VERSION ""

NS_ :

BS_:

BU_: R_STR IAVAS ADAS ADAS_GW ENM THM CHR BAT BEV BEV_GW LCT STA ABG EPS IPMS BST VDC C_ECU C_ECU_GW

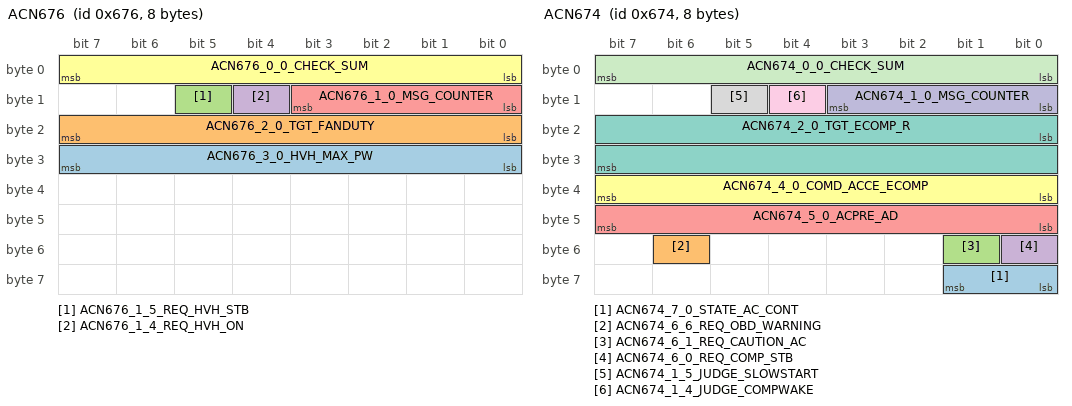
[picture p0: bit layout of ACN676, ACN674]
BO_ 1654 ACN676: 8 C_ECU_GW
 SG_ ACN676_3_0_HVH_MAX_PW : 24|8@1+ (40,0) [0|10200] "W"  THM
 SG_ ACN676_2_0_TGT_FANDUTY : 16|8@1+ (0.4,0) [0|100] "％"  THM
 SG_ ACN676_1_5_REQ_HVH_STB : 13|1@1+ (1,0) [0|1] ""  THM
 SG_ ACN676_1_4_REQ_HVH_ON : 12|1@1+ (1,0) [0|1] ""  THM
 SG_ ACN676_1_0_MSG_COUNTER : 8|4@1+ (1,0) [0|15] ""  THM
 SG_ ACN676_0_0_CHECK_SUM : 0|8@1+ (1,0) [0|255] ""  THM

BO_ 1652 ACN674: 8 C_ECU_GW
 SG_ ACN674_7_0_STATE_AC_CONT : 56|2@1+ (1,0) [0|3] ""  THM
 SG_ ACN674_6_6_REQ_OBD_WARNING : 54|1@1+ (1,0) [0|1] ""  THM
 SG_ ACN674_6_1_REQ_CAUTION_AC : 49|1@1+ (1,0) [0|1] ""  THM
 SG_ ACN674_6_0_REQ_COMP_STB : 48|1@1+ (1,0) [0|1] ""  THM
 SG_ ACN674_5_0_ACPRE_AD : 40|8@1+ (0.01953,0) [0|4.9815] "V"  THM
 SG_ ACN674_4_0_COMD_ACCE_ECOMP : 32|8@1+ (20,0) [0|5100] "rpm/s"  THM
 SG_ ACN674_2_0_TGT_ECOMP_R : 16|16@1+ (1,0) [0|65535] "rpm"  THM
 SG_ ACN674_1_5_JUDGE_SLOWSTART : 13|1@1+ (1,0) [0|1] ""  THM
 SG_ ACN674_1_4_JUDGE_COMPWAKE : 12|1@1+ (1,0) [0|1] ""  THM
 SG_ ACN674_1_0_MSG_COUNTER : 8|4@1+ (1,0) [0|15] ""  THM
 SG_ ACN674_0_0_CHECK_SUM : 0|8@1+ (1,0) [0|255] ""  THM

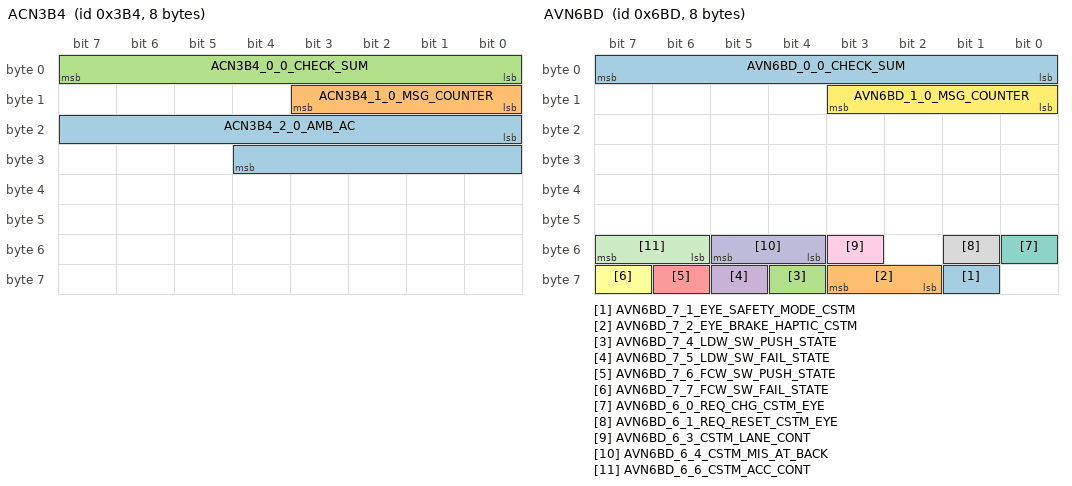
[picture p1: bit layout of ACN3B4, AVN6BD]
BO_ 948 ACN3B4: 8 C_ECU_GW
 SG_ ACN3B4_2_0_AMB_AC : 16|13@1+ (0.1,-400) [-400|419.1] "℃"  THM
 SG_ ACN3B4_1_0_MSG_COUNTER : 8|4@1+ (1,0) [0|15] ""  THM
 SG_ ACN3B4_0_0_CHECK_SUM : 0|8@1+ (1,0) [0|255] ""  THM

BO_ 1725 AVN6BD: 8 C_ECU_GW
 SG_ AVN6BD_7_1_EYE_SAFETY_MODE_CSTM : 57|1@0+ (1,0) [0|1] ""  ADAS
 SG_ AVN6BD_7_2_EYE_BRAKE_HAPTIC_CSTM : 59|2@0+ (1,0) [0|3] ""  ADAS
 SG_ AVN6BD_7_4_LDW_SW_PUSH_STATE : 60|1@0+ (1,0) [0|1] ""  ADAS
 SG_ AVN6BD_7_5_LDW_SW_FAIL_STATE : 61|1@0+ (1,0) [0|1] ""  ADAS
 SG_ AVN6BD_7_6_FCW_SW_PUSH_STATE : 62|1@0+ (1,0) [0|1] ""  ADAS
 SG_ AVN6BD_7_7_FCW_SW_FAIL_STATE : 63|1@0+ (1,0) [0|1] ""  ADAS
 SG_ AVN6BD_6_0_REQ_CHG_CSTM_EYE : 48|1@0+ (1,0) [0|1] ""  ADAS
 SG_ AVN6BD_6_1_REQ_RESET_CSTM_EYE : 49|1@0+ (1,0) [0|1] ""  ADAS
 SG_ AVN6BD_6_3_CSTM_LANE_CONT : 51|1@0+ (1,0) [0|1] ""  ADAS
 SG_ AVN6BD_6_4_CSTM_MIS_AT_BACK : 53|2@0+ (1,0) [0|3] ""  ADAS
 SG_ AVN6BD_6_6_CSTM_ACC_CONT : 55|2@0+ (1,0) [0|3] ""  ADAS
 SG_ AVN6BD_1_0_MSG_COUNTER : 11|4@0+ (1,0) [0|15] ""  ADAS
 SG_ AVN6BD_0_0_CHECK_SUM : 7|8@0+ (1,0) [0|255] ""  ADAS

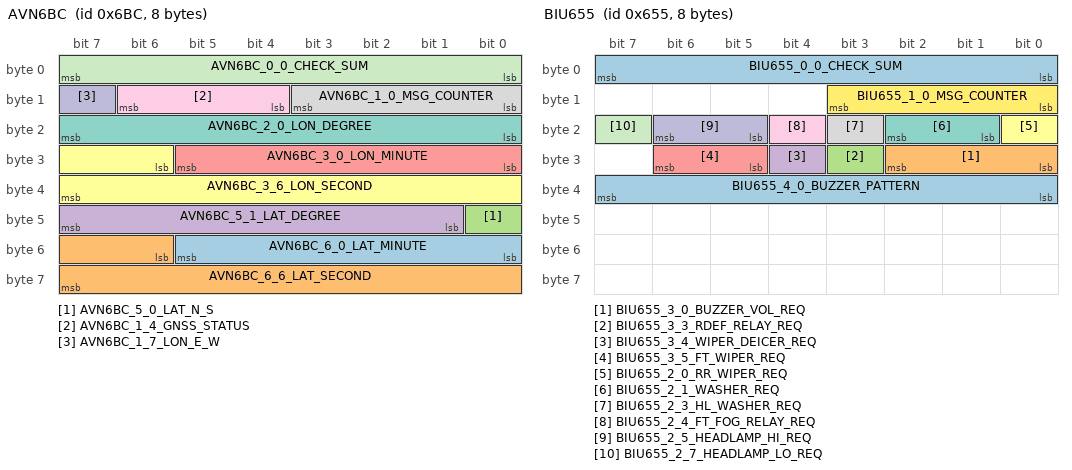
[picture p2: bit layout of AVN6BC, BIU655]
BO_ 1724 AVN6BC: 8 C_ECU_GW
 SG_ AVN6BC_6_0_LAT_MINUTE : 48|6@1+ (1,0) [0|59] ""  ADAS,CHR
 SG_ AVN6BC_6_6_LAT_SECOND : 54|10@1+ (0.1,0) [0|59.9] ""  ADAS,CHR
 SG_ AVN6BC_5_0_LAT_N_S : 40|1@1+ (1,0) [0|1] ""  ADAS,CHR
 SG_ AVN6BC_5_1_LAT_DEGREE : 41|7@1+ (1,0) [0|90] ""  ADAS,CHR
 SG_ AVN6BC_3_0_LON_MINUTE : 24|6@1+ (1,0) [0|59] ""  ADAS,CHR
 SG_ AVN6BC_3_6_LON_SECOND : 30|10@1+ (0.1,0) [0|59.9] ""  ADAS,CHR
 SG_ AVN6BC_2_0_LON_DEGREE : 16|8@1+ (1,0) [0|180] ""  ADAS,CHR
 SG_ AVN6BC_1_0_MSG_COUNTER : 8|4@1+ (1,0) [0|15] ""  ADAS,CHR
 SG_ AVN6BC_1_4_GNSS_STATUS : 12|3@1+ (1,0) [0|7] ""  ADAS,CHR
 SG_ AVN6BC_1_7_LON_E_W : 15|1@1+ (1,0) [0|1] ""  ADAS,CHR
 SG_ AVN6BC_0_0_CHECK_SUM : 0|8@1+ (1,0) [0|255] ""  ADAS,CHR

BO_ 1723 AVN6BB: 8 C_ECU_GW
 SG_ AVN6BB_7_0_ISA_IACC_OFFSET_CSTM : 56|5@1+ (1,0) [0|20] ""  ADAS
 SG_ AVN6BB_7_5_EYE_TOLLBOOTH_DECEL : 61|1@1+ (1,0) [0|1] ""  ADAS
 SG_ AVN6BB_7_6_EYE_CURVE_DECEL_CSTM : 62|1@1+ (1,0) [0|1] ""  ADAS
 SG_ AVN6BB_7_7_EYE_GREEN_LIGHT_CSTM : 63|1@1+ (1,0) [0|1] ""  ADAS
 SG_ AVN6BB_6_0_CCU_FAIL : 48|1@1+ (1,0) [0|1] ""  ADAS,VDC
 SG_ AVN6BB_6_1_EYE_P_CR_CSTM : 49|1@1+ (1,0) [0|1] ""  ADAS
 SG_ AVN6BB_6_2_EYE_ALK_B_LDW_CSTM : 50|2@1+ (1,0) [0|3] ""  ADAS
 SG_ AVN6BB_6_4_EYE_CSTM_REQ : 52|1@1+ (1,0) [0|1] ""  ADAS
 SG_ AVN6BB_6_5_EYE_ELK_CSTM : 53|1@1+ (1,0) [0|1] ""  ADAS
 SG_ AVN6BB_6_6_EYE_ALKB_EDGE_CSTM : 54|1@1+ (1,0) [0|1] "" Vector__XXX
 SG_ AVN6BB_6_7_FCW_ON_OFF : 55|1@1+ (1,0) [0|1] ""  ADAS
 SG_ AVN6BB_5_0_DMS_SELECT_ID : 40|4@1+ (1,0) [0|5] ""  IPMS
 SG_ AVN6BB_5_4_TPMS_TH_MODE_CSTM : 44|2@1+ (1,0) [0|3] ""  ADAS
 SG_ AVN6BB_5_6_DMS_SET_REQ : 46|1@1+ (1,0) [0|1] ""  IPMS
 SG_ AVN6BB_5_7_DMS_RECOG_SET : 47|1@1+ (1,0) [0|1] ""  IPMS
 SG_ AVN6BB_4_0_DMS_EDIT_REQ : 32|4@1+ (1,0) [0|15] ""  IPMS
 SG_ AVN6BB_4_4_VEHICLE_DEMO : 36|1@1+ (1,0) [0|1] ""  IPMS
 SG_ AVN6BB_4_5_SRVD_CSTM_REQ : 37|1@1+ (1,0) [0|1] "" Vector__XXX
 SG_ AVN6BB_4_6_SEAT_RESET_REQ : 38|1@1+ (1,0) [0|1] "" Vector__XXX
 SG_ AVN6BB_4_7_SEATAWAY_SET_CSTM : 39|1@1+ (1,0) [0|1] "" Vector__XXX
 SG_ AVN6BB_3_0_SRVD_ON_OFF : 24|1@1+ (1,0) [0|1] "" Vector__XXX
 SG_ AVN6BB_3_1_PRG_RESET_REQ : 25|1@1+ (1,0) [0|1] "" Vector__XXX
 SG_ AVN6BB_3_2_PRG_MEM_CSTM : 26|1@1+ (1,0) [0|1] "" Vector__XXX
 SG_ AVN6BB_3_3_DMS_ON_OFF : 27|1@1+ (1,0) [0|1] ""  IPMS
 SG_ AVN6BB_3_4_MIR_RESET_REQ : 28|1@1+ (1,0) [0|1] "" Vector__XXX
 SG_ AVN6BB_3_5_MIR_AFOLD_CSTM : 29|1@1+ (1,0) [0|1] "" Vector__XXX
 SG_ AVN6BB_3_6_MIR_RTILT_CSTM : 30|1@1+ (1,0) [0|1] "" Vector__XXX
 SG_ AVN6BB_3_7_EYE_TSA_CSTM : 31|1@1+ (1,0) [0|1] ""  ADAS
 SG_ AVN6BB_2_0_AVH_ON_OFF : 16|2@1+ (1,0) [0|3] ""  VDC
 SG_ AVN6BB_2_2_VDC_ON_OFF : 18|2@1+ (1,0) [0|3] ""  VDC
 SG_ AVN6BB_2_4_CCU_HALT_RESET : 20|1@1+ (1,0) [0|1] ""  ADAS,VDC
 SG_ AVN6BB_2_5_EYE_LDW_TIMING_CSTM : 21|1@1+ (1,0) [0|1] ""  ADAS
 SG_ AVN6BB_2_6_FCW_CSTM : 22|2@1+ (1,0) [0|3] ""  ADAS
 SG_ AVN6BB_1_0_MSG_COUNTER : 8|4@1+ (1,0) [0|15] ""  ADAS,IPMS,VDC
 SG_ AVN6BB_1_4_EYE_WARN_CSTM : 12|1@1+ (1,0) [0|1] ""  ADAS
 SG_ AVN6BB_1_5_EYE_FCTI_CSTM : 13|2@1+ (1,0) [0|3] "" Vector__XXX
 SG_ AVN6BB_1_7_LDW_WARNING_ON_OFF : 15|1@1+ (1,0) [0|1] ""  ADAS
 SG_ AVN6BB_0_0_CHECK_SUM : 0|8@1+ (1,0) [0|255] ""  ADAS,IPMS,VDC

BO_ 1713 AVN6B1: 8 C_ECU_GW
 SG_ AVN6B1_7_1_PRESENT_YEAR : 57|7@1+ (1,0) [0|126] "Year"  ADAS
 SG_ AVN6B1_6_0_PRESENT_DAY : 48|5@1+ (1,0) [1|31] "Day"  ADAS
 SG_ AVN6B1_6_5_PRESENT_MONTH : 53|4@1+ (1,0) [1|12] "Month"  ADAS
 SG_ AVN6B1_5_0_FAIL_AVN : 40|1@1+ (1,0) [0|1] "" Vector__XXX
 SG_ AVN6B1_5_1_IN_OPERATION : 41|1@1+ (1,0) [0|1] "" Vector__XXX
 SG_ AVN6B1_5_2_TYPE_NAVI : 42|2@1+ (1,0) [0|3] "" Vector__XXX
 SG_ AVN6B1_5_4_XM_ENABLE : 44|2@1+ (1,0) [0|3] "" Vector__XXX
 SG_ AVN6B1_5_6_FLG_ABLE_WELCOME_SCL : 46|1@1+ (1,0) [0|1] "" Vector__XXX
 SG_ AVN6B1_5_7_STEER_ANGLE_INTERLOCK : 47|1@1+ (1,0) [0|1] "" Vector__XXX
 SG_ AVN6B1_4_0_PRESENT_TIME_SEC : 32|6@1+ (1,0) [0|59] "s"  ADAS
 SG_ AVN6B1_4_7_BACK_CAMERA_DELAY : 39|1@1+ (1,0) [0|1] "" Vector__XXX
 SG_ AVN6B1_3_0_PRESENT_TIME_MIN : 24|6@1+ (1,0) [0|59] "m"  ADAS
 SG_ AVN6B1_3_7_MVS_FTSNR_INTERRUPT : 31|1@1+ (1,0) [0|1] "" Vector__XXX
 SG_ AVN6B1_2_0_GPS_CLOCK_FLG : 16|1@1+ (1,0) [0|1] ""  ADAS
 SG_ AVN6B1_2_1_PRESENT_TIME_HOUR : 17|5@1+ (1,0) [0|23] "h"  ADAS
 SG_ AVN6B1_2_6_TIME_FORMAT : 22|2@1+ (1,0) [0|3] "" Vector__XXX
 SG_ AVN6B1_1_0_MSG_COUNTER : 8|4@1+ (1,0) [0|15] ""  ADAS
 SG_ AVN6B1_1_4_WAKE_UP_FRAME : 12|1@1+ (1,0) [0|1] "" Vector__XXX
 SG_ AVN6B1_1_5_REQ_COMM_CONT : 13|1@1+ (1,0) [0|1] "" Vector__XXX
 SG_ AVN6B1_1_6_ACTIVE_AVN_CSTM : 14|1@1+ (1,0) [0|1] "" Vector__XXX
 SG_ AVN6B1_1_7_REQ_STOP_CAMERA_OUT : 15|1@1+ (1,0) [0|1] ""  ADAS
 SG_ AVN6B1_0_0_CHECK_SUM : 0|8@1+ (1,0) [0|255] ""  ADAS

BO_ 1019 AVN3FB: 8 C_ECU_GW
 SG_ AVN3FB_7_0_SMT_TIM_RESET_REQ : 56|1@1+ (1,0) [0|1] "" Vector__XXX
 SG_ AVN3FB_7_1_SMT_EG_CSTM_REQ : 57|1@1+ (1,0) [0|1] "" Vector__XXX
 SG_ AVN3FB_7_2_EYE_YEILD_CSTM : 58|1@1+ (1,0) [0|1] ""  ADAS
 SG_ AVN3FB_7_3_EYE_STOP_CSTM : 59|1@1+ (1,0) [0|1] ""  ADAS
 SG_ AVN3FB_7_4_EYE_NO_ENTRY_CSTM : 60|1@1+ (1,0) [0|1] ""  ADAS
 SG_ AVN3FB_7_5_MVS_CAMERA_SELECT_SW : 61|1@1+ (1,0) [0|1] "" Vector__XXX
 SG_ AVN3FB_7_7_ACPANEL_DR_ONLY : 63|1@1+ (1,0) [0|1] "" Vector__XXX
 SG_ AVN3FB_6_0_ACPANEL_PA_TEMP : 48|6@1+ (0.5,13) [1|44] "℃/?" Vector__XXX
 SG_ AVN3FB_6_6_ACPANEL_MODE_DOWN : 54|1@1+ (1,0) [0|1] "" Vector__XXX
 SG_ AVN3FB_6_7_ACPANEL_MODE_UP : 55|1@1+ (1,0) [0|1] "" Vector__XXX
 SG_ AVN3FB_5_0_ACPANEL_DR_TEMP : 40|6@1+ (0.5,13) [1|44] "℃/?" Vector__XXX
 SG_ AVN3FB_5_6_ACPANEL_FAN_DOWN : 46|1@1+ (1,0) [0|1] "" Vector__XXX
 SG_ AVN3FB_5_7_ACPANEL_FAN_UP : 47|1@1+ (1,0) [0|1] "" Vector__XXX
 SG_ AVN3FB_4_0_ACPANEL_FAN_LEVEL : 32|4@1+ (1,0) [0|15] "" Vector__XXX
 SG_ AVN3FB_4_4_ACPANEL_MODE_VENT : 36|4@1+ (1,0) [0|15] "" Vector__XXX
 SG_ AVN3FB_3_0_ACPANEL_PA_TEMP_DOWN : 24|1@1+ (1,0) [0|1] "" Vector__XXX
 SG_ AVN3FB_3_1_ACPANEL_PA_TEMP_UP : 25|1@1+ (1,0) [0|1] "" Vector__XXX
 SG_ AVN3FB_3_2_ACPANEL_DR_TEMP_DOWN : 26|1@1+ (1,0) [0|1] "" Vector__XXX
 SG_ AVN3FB_3_3_ACPANEL_DR_TEMP_UP : 27|1@1+ (1,0) [0|1] "" Vector__XXX
 SG_ AVN3FB_3_4_ACPANEL_SYNC : 28|1@1+ (1,0) [0|1] "" Vector__XXX
 SG_ AVN3FB_3_5_ACPANEL_AC : 29|1@1+ (1,0) [0|1] "" Vector__XXX
 SG_ AVN3FB_3_6_F_DEF_SW : 30|1@1+ (1,0) [0|1] "" Vector__XXX
 SG_ AVN3FB_3_7_R_DEF_SW : 31|1@1+ (1,0) [0|1] "" Vector__XXX
 SG_ AVN3FB_2_0_ACPANEL_AUTO : 16|1@1+ (1,0) [0|1] "" Vector__XXX
 SG_ AVN3FB_2_1_ACPANEL_MAX_AC : 17|1@1+ (1,0) [0|1] "" Vector__XXX
 SG_ AVN3FB_2_2_ACPANEL_SEAT_C_P : 18|1@1+ (1,0) [0|1] "" Vector__XXX
 SG_ AVN3FB_2_3_ACPANEL_SEAT_C_D : 19|1@1+ (1,0) [0|1] "" Vector__XXX
 SG_ AVN3FB_2_4_ACPANEL_SEAT_H_P : 20|1@1+ (1,0) [0|1] "" Vector__XXX
 SG_ AVN3FB_2_5_ACPANEL_SEAT_H_D : 21|1@1+ (1,0) [0|1] "" Vector__XXX
 SG_ AVN3FB_2_6_ACPANEL_INNER_AIR : 22|1@1+ (1,0) [0|1] "" Vector__XXX
 SG_ AVN3FB_2_7_ACPANEL_AC_ON_OFF : 23|1@1+ (1,0) [0|1] "" Vector__XXX
 SG_ AVN3FB_1_0_MSG_COUNTER : 8|4@1+ (1,0) [0|15] ""  ADAS
 SG_ AVN3FB_1_4_EYE_CSTM_REQ_3FB : 12|1@1+ (1,0) [0|1] ""  ADAS
 SG_ AVN3FB_1_5_DDAW_WARNING_CSTM : 13|1@1+ (1,0) [0|1] ""  ADAS
 SG_ AVN3FB_1_6_SIGN_SWITCH_SND : 14|1@1+ (1,0) [0|1] ""  ADAS
 SG_ AVN3FB_1_7_SLWF_CSTM : 15|1@1+ (1,0) [0|1] ""  ADAS
 SG_ AVN3FB_0_0_CHECK_SUM : 0|8@1+ (1,0) [0|255] ""  ADAS

BO_ 818 PMN332: 8 C_ECU_GW
 SG_ PMN332_7_0_RES_CONTROL_STATUS : 56|2@1+ (1,0) [0|3] "" Vector__XXX
 SG_ PMN332_7_2_REQ_RES_P_LOCK : 58|1@1+ (1,0) [0|1] "" Vector__XXX
 SG_ PMN332_7_5_IGB_RELAY_REQ : 61|1@1+ (1,0) [0|1] ""  BEV
 SG_ PMN332_7_6_IGA_RELAY_REQ : 62|1@1+ (1,0) [0|1] ""  BEV
 SG_ PMN332_7_7_REQ_STOP_RES : 63|1@1+ (1,0) [0|1] "" Vector__XXX
 SG_ PMN332_6_0_RES_IDLE_TIME : 48|7@1+ (10,0) [0|1270] "sec" Vector__XXX
 SG_ PMN332_6_7_CUST : 55|1@1+ (1,0) [0|1] "" Vector__XXX
 SG_ PMN332_5_0_PUSHSTART_SW : 40|1@1+ (1,0) [0|1] "" Vector__XXX
 SG_ PMN332_5_1_SIG_KEY_PUSHSTART : 41|1@1+ (1,0) [0|1] "" Vector__XXX
 SG_ PMN332_5_2_STATE_MODE_POWER : 42|2@1+ (1,0) [0|2] "" Vector__XXX
 SG_ PMN332_5_4_BUZ_2SHOT_IN : 44|1@1+ (1,0) [0|1] "" Vector__XXX
 SG_ PMN332_5_5_BUZ_INTERMIT1_IN : 45|1@1+ (1,0) [0|1] "" Vector__XXX
 SG_ PMN332_5_6_BUZ_INTERMIT2_IN : 46|1@1+ (1,0) [0|1] "" Vector__XXX
 SG_ PMN332_5_7_BUZ_CONTINUE_IN : 47|1@1+ (1,0) [0|1] "" Vector__XXX
 SG_ PMN332_2_0_WARN_SSP_SIG1 : 16|1@1+ (1,0) [0|1] "" Vector__XXX
 SG_ PMN332_2_1_WARN_SSP_SIG2 : 17|3@1+ (1,0) [0|4] "" Vector__XXX
 SG_ PMN332_2_4_SMT_PWR_SIG : 20|2@1+ (1,0) [0|2] "" Vector__XXX
 SG_ PMN332_2_7_BUZ_1SHOT_IN : 23|1@1+ (1,0) [0|1] "" Vector__XXX
 SG_ PMN332_1_0_MSG_COUNTER : 8|4@1+ (1,0) [0|15] ""  BEV
 SG_ PMN332_0_0_CHECK_SUM : 0|8@1+ (1,0) [0|255] ""  BEV

BO_ 1622 BIU656: 8 C_ECU_GW
 SG_ BIU656_6_0_KICK_OPEN_REQ_PRG : 48|1@1+ (1,0) [0|1] "" Vector__XXX
 SG_ BIU656_6_1_KICK_CLOSE_REQ_PRG : 49|1@1+ (1,0) [0|1] "" Vector__XXX
 SG_ BIU656_6_6_CARGO_LAMP_OUT : 54|1@1+ (1,0) [0|1] "" Vector__XXX
 SG_ BIU656_6_7_PERMITT_KEY_RG_UNL : 55|1@1+ (1,0) [0|1] "" Vector__XXX
 SG_ BIU656_5_0_PRG_DRVR_OPENERSW : 40|1@1+ (1,0) [0|1] "" Vector__XXX
 SG_ BIU656_5_1_HF_PRG_OFF_SW : 41|1@1+ (1,0) [0|1] "" Vector__XXX
 SG_ BIU656_5_2_PERMIT_OPEN_RG : 42|1@1+ (1,0) [0|1] "" Vector__XXX
 SG_ BIU656_5_3_BUZ_ON_OFF : 43|1@1+ (1,0) [0|1] "" Vector__XXX
 SG_ BIU656_5_4_PRG_DRVR_SW_PERMIT : 44|1@1+ (1,0) [0|1] "" Vector__XXX
 SG_ BIU656_5_5_CSTM_HF_PRG_LOCK : 45|1@1+ (1,0) [0|1] "" Vector__XXX
 SG_ BIU656_5_6_CSTM_KICK_SENSOR : 46|1@1+ (1,0) [0|1] "" Vector__XXX
 SG_ BIU656_5_7_KICK_REQ_PRG : 47|1@1+ (1,0) [0|1] "" Vector__XXX
 SG_ BIU656_4_0_NOT_SMT_KEY_RG_SW : 32|2@1+ (1,0) [0|3] "" Vector__XXX
 SG_ BIU656_4_2_SMT_KEY_RG_SW : 34|2@1+ (1,0) [0|3] "" Vector__XXX
 SG_ BIU656_4_4_OPEN_RG_OPENER_SW : 36|2@1+ (1,0) [0|3] "" Vector__XXX
 SG_ BIU656_3_4_CHECKED_KEYNO : 28|3@1+ (1,0) [0|7] "" Vector__XXX
 SG_ BIU656_3_7_LOCKSTATUS_DRVR : 31|1@1+ (1,0) [0|1] "" Vector__XXX
 SG_ BIU656_2_0_TRIG_LOCK_UNLOCK : 16|12@1+ (1,0) [0|4095] ""  IPMS
 SG_ BIU656_1_0_MSG_COUNTER : 8|4@1+ (1,0) [0|15] "" Vector__XXX
 SG_ BIU656_0_0_CHECK_SUM : 0|8@1+ (1,0) [0|255] "" Vector__XXX

BO_ 1621 BIU655: 8 C_ECU_GW
 SG_ BIU655_4_0_BUZZER_PATTERN : 32|8@1+ (1,0) [0|240] "" Vector__XXX
 SG_ BIU655_3_0_BUZZER_VOL_REQ : 24|3@1+ (1,0) [0|7] "" Vector__XXX
 SG_ BIU655_3_3_RDEF_RELAY_REQ : 27|1@1+ (1,0) [0|1] "" Vector__XXX
 SG_ BIU655_3_4_WIPER_DEICER_REQ : 28|1@1+ (1,0) [0|1] "" Vector__XXX
 SG_ BIU655_3_5_FT_WIPER_REQ : 29|2@1+ (1,0) [0|3] "" Vector__XXX
 SG_ BIU655_2_0_RR_WIPER_REQ : 16|1@1+ (1,0) [0|1] "" Vector__XXX
 SG_ BIU655_2_1_WASHER_REQ : 17|2@1+ (1,0) [0|3] ""  ADAS
 SG_ BIU655_2_3_HL_WASHER_REQ : 19|1@1+ (1,0) [0|1] "" Vector__XXX
 SG_ BIU655_2_4_FT_FOG_RELAY_REQ : 20|1@1+ (1,0) [0|1] "" Vector__XXX
 SG_ BIU655_2_5_HEADLAMP_HI_REQ : 21|2@1+ (1,0) [0|3] "" Vector__XXX
 SG_ BIU655_2_7_HEADLAMP_LO_REQ : 23|1@1+ (1,0) [0|1] "" Vector__XXX
 SG_ BIU655_1_0_MSG_COUNTER : 8|4@1+ (1,0) [0|15] "" Vector__XXX
 SG_ BIU655_0_0_CHECK_SUM : 0|8@1+ (1,0) [0|255] "" Vector__XXX

BO_ 1618 BIU652: 8 C_ECU_GW
 SG_ BIU652_7_0_IND_SECURITY_IMB : 56|8@1+ (1,0) [0|240] "" Vector__XXX
 SG_ BIU652_6_0_OCCUPATION_3RDRH : 48|1@1+ (1,0) [0|1] "" Vector__XXX
 SG_ BIU652_6_1_OCCUPATION_3RDCTR : 49|1@1+ (1,0) [0|1] "" Vector__XXX
 SG_ BIU652_6_2_OCCUPATION_3RDLH : 50|1@1+ (1,0) [0|1] "" Vector__XXX
 SG_ BIU652_6_3_OCCUPATION_RRRH : 51|1@1+ (1,0) [0|1] ""  ABG
 SG_ BIU652_6_4_OCCUPATION_RRCTR : 52|1@1+ (1,0) [0|1] ""  ABG
 SG_ BIU652_6_5_OCCUPATION_RRLH : 53|1@1+ (1,0) [0|1] ""  ABG
 SG_ BIU652_6_6_HORNHAZARD_RES_SIG : 54|1@1+ (1,0) [0|1] "" Vector__XXX
 SG_ BIU652_6_7_OCCUPATION_DRVR : 55|1@1+ (1,0) [0|1] ""  ABG
 SG_ BIU652_5_0_STATUS_ROOMLAMP : 40|3@1+ (1,0) [0|7] "" Vector__XXX
 SG_ BIU652_5_3_HEADLAMP_SMALL : 43|1@1+ (1,0) [0|1] "" Vector__XXX
 SG_ BIU652_5_4_ALL_UNLOCK_STATE : 44|1@1+ (1,0) [0|1] "" Vector__XXX
 SG_ BIU652_5_5_DRVR_UNLOCK_STATE : 45|1@1+ (1,0) [0|1] "" Vector__XXX
 SG_ BIU652_5_6_ALL_LOCK_STATE : 46|1@1+ (1,0) [0|1] "" Vector__XXX
 SG_ BIU652_4_0_TRIG_LOCK_UNLOCK : 32|8@1+ (1,0) [0|255] ""  IPMS
 SG_ BIU652_3_0_DOOR_DRVR : 24|1@1+ (1,0) [0|1] "" Vector__XXX
 SG_ BIU652_3_1_DOOR_PASS : 25|1@1+ (1,0) [0|1] "" Vector__XXX
 SG_ BIU652_3_2_DOOR_RRRH : 26|1@1+ (1,0) [0|1] "" Vector__XXX
 SG_ BIU652_3_3_DOOR_RRLH : 27|1@1+ (1,0) [0|1] "" Vector__XXX
 SG_ BIU652_3_4_DOOR_RG : 28|1@1+ (1,0) [0|1] "" Vector__XXX
 SG_ BIU652_3_5_DOOR_TR : 29|1@1+ (1,0) [0|1] "" Vector__XXX
 SG_ BIU652_3_7_OPENSW_RG : 31|1@1+ (1,0) [0|1] "" Vector__XXX
 SG_ BIU652_2_0_LOCKSTATUS_DRVR : 16|1@1+ (1,0) [0|1] "" Vector__XXX
 SG_ BIU652_2_1_LOCKSTATUS_PASS : 17|1@1+ (1,0) [0|1] "" Vector__XXX
 SG_ BIU652_2_2_LOCKSTATUS_RRRH : 18|1@1+ (1,0) [0|1] "" Vector__XXX
 SG_ BIU652_2_3_LOCKSTATUS_RRLH : 19|1@1+ (1,0) [0|1] "" Vector__XXX
 SG_ BIU652_2_4_LOCKSTATUS_RG : 20|1@1+ (1,0) [0|1] "" Vector__XXX
 SG_ BIU652_2_6_UNLOCK_DOORKEYSW : 22|1@1+ (1,0) [0|1] "" Vector__XXX
 SG_ BIU652_2_7_LOCK_DOORKEYSW : 23|1@1+ (1,0) [0|1] "" Vector__XXX
 SG_ BIU652_1_0_MSG_COUNTER : 8|4@1+ (1,0) [0|15] ""  ABG,IPMS
 SG_ BIU652_0_0_CHECK_SUM : 0|8@1+ (1,0) [0|255] ""  ABG,IPMS

BO_ 1617 BIU651: 8 C_ECU_GW
 SG_ BIU651_7_0_PWPOS_RL : 56|2@1+ (1,0) [0|3] "" Vector__XXX
 SG_ BIU651_7_2_PWPOS_RR : 58|2@1+ (1,0) [0|3] "" Vector__XXX
 SG_ BIU651_7_4_PWPOS_PASS : 60|2@1+ (1,0) [0|3] "" Vector__XXX
 SG_ BIU651_7_6_PWPOS_DRVR : 62|2@1+ (1,0) [0|3] "" Vector__XXX
 SG_ BIU651_6_0_IND_ACTIVE_HBA : 48|2@1+ (1,0) [0|3] "" Vector__XXX
 SG_ BIU651_6_2_ADB_ACTIVE : 50|1@1+ (1,0) [0|1] ""  ADAS
 SG_ BIU651_6_3_JUDGE_ILL : 51|1@1+ (1,0) [0|1] "" Vector__XXX
 SG_ BIU651_6_4_TYPE_LO_BEAM : 52|2@1+ (1,0) [0|3] "" Vector__XXX
 SG_ BIU651_6_6_TYPE_HI_BEAM : 54|2@1+ (1,0) [0|3] "" Vector__XXX
 SG_ BIU651_5_0_SRF_ACTIVE : 40|1@1+ (1,0) [0|1] ""  ADAS
 SG_ BIU651_5_1_SRF_IND : 41|2@1+ (1,0) [0|3] ""  ADAS
 SG_ BIU651_5_3_SRF_LAMP_LIGHT : 43|1@1+ (1,0) [0|1] ""  ADAS
 SG_ BIU651_5_4_SRF_LAMP_LEFT : 44|1@1+ (1,0) [0|1] ""  ADAS
 SG_ BIU651_5_5_MSG_STATUS_HBA : 45|2@1+ (1,0) [0|3] "" Vector__XXX
 SG_ BIU651_5_7_IND_FAIL_HBA : 47|1@1+ (1,0) [0|1] "" Vector__XXX
 SG_ BIU651_4_0_BUZ_PATTERN : 32|4@1+ (1,0) [0|8] "" Vector__XXX
 SG_ BIU651_4_4_CSTM_OPE_ALARM : 36|2@1+ (1,0) [0|3] "" Vector__XXX
 SG_ BIU651_4_6_CSTM_HBA : 38|2@1+ (1,0) [0|3] ""  ADAS
 SG_ BIU651_3_0_HEADLAMP_PASS_SW : 24|1@1+ (1,0) [0|1] ""  ADAS
 SG_ BIU651_3_1_HEADLAMP_AUTO_SW : 25|1@1+ (1,0) [0|1] ""  ADAS
 SG_ BIU651_3_2_JUDGE_DOOR_LOCK : 26|1@1+ (1,0) [0|1] "" Vector__XXX
 SG_ BIU651_3_3_JUDGE_DOOR_UNLOCK : 27|1@1+ (1,0) [0|1] "" Vector__XXX
 SG_ BIU651_3_4_HEADLAMP_Lo_SW : 28|1@1+ (1,0) [0|1] "" Vector__XXX
 SG_ BIU651_3_5_HEADLAMP_HI_SW : 29|1@1+ (1,0) [0|1] ""  ADAS
 SG_ BIU651_3_6_WIPER_AUTO_SW : 30|1@1+ (1,0) [0|1] "" Vector__XXX
 SG_ BIU651_3_7_PRG_LIN_MEMORY_ON_OFF : 31|1@1+ (1,0) [0|1] "" Vector__XXX
 SG_ BIU651_2_0_CSTM_ILLUMI_SSR : 16|1@1+ (1,0) [0|1] "" Vector__XXX
 SG_ BIU651_2_1_HANDLE : 17|1@1+ (1,0) [0|1] ""  ADAS
 SG_ BIU651_2_2_CSTM_SMT : 18|1@1+ (1,0) [0|1] "" Vector__XXX
 SG_ BIU651_2_3_AJARDOOR_STATUS : 19|1@1+ (1,0) [0|1] "" Vector__XXX
 SG_ BIU651_2_4_ONETOUCH_LAMP_OUT : 20|1@1+ (1,0) [0|1] "" Vector__XXX
 SG_ BIU651_2_5_PRG_FAIL_FLAG : 21|1@1+ (1,0) [0|1] "" Vector__XXX
 SG_ BIU651_2_6_CSTM_PSMECU : 22|1@1+ (1,0) [0|1] "" Vector__XXX
 SG_ BIU651_2_7_STATE_REGIST_DEL : 23|1@1+ (1,0) [0|1] "" Vector__XXX
 SG_ BIU651_1_0_MSG_COUNTER : 8|4@1+ (1,0) [0|15] ""  ADAS
 SG_ BIU651_1_4_SRPOS : 12|3@1+ (1,0) [0|7] "" Vector__XXX
 SG_ BIU651_1_7_WIPER_INT_STATUS : 15|1@1+ (1,0) [0|1] "" Vector__XXX
 SG_ BIU651_0_0_CHECK_SUM : 0|8@1+ (1,0) [0|255] ""  ADAS

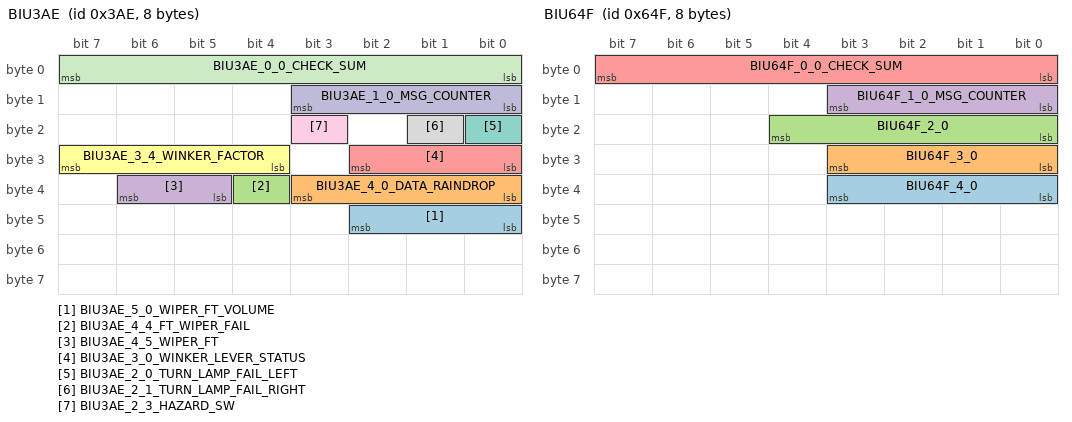
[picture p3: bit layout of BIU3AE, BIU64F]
BO_ 942 BIU3AE: 8 C_ECU_GW
 SG_ BIU3AE_5_0_WIPER_FT_VOLUME : 40|3@1+ (1,0) [0|5] "" Vector__XXX
 SG_ BIU3AE_4_0_DATA_RAINDROP : 32|4@1+ (1,0) [0|8] ""  ADAS
 SG_ BIU3AE_4_4_FT_WIPER_FAIL : 36|1@1+ (1,0) [0|1] "" Vector__XXX
 SG_ BIU3AE_4_5_WIPER_FT : 37|2@1+ (1,0) [0|3] ""  ADAS
 SG_ BIU3AE_3_0_WINKER_LEVER_STATUS : 24|3@1+ (1,0) [0|5] ""  ADAS
 SG_ BIU3AE_3_4_WINKER_FACTOR : 28|4@1+ (1,0) [0|15] ""  ADAS,ABG
 SG_ BIU3AE_2_0_TURN_LAMP_FAIL_LEFT : 16|1@1+ (1,0) [0|1] ""  ADAS
 SG_ BIU3AE_2_1_TURN_LAMP_FAIL_RIGHT : 17|1@1+ (1,0) [0|1] ""  ADAS
 SG_ BIU3AE_2_3_HAZARD_SW : 19|1@1+ (1,0) [0|1] ""  ADAS
 SG_ BIU3AE_1_0_MSG_COUNTER : 8|4@1+ (1,0) [0|15] ""  ADAS,ABG
 SG_ BIU3AE_0_0_CHECK_SUM : 0|8@1+ (1,0) [0|255] ""  ADAS,ABG

BO_ 940 BIU3AC: 8 C_ECU_GW
 SG_ BIU3AC_7_0_HEADLAMP_SMALL : 56|1@1+ (1,0) [0|1] ""  ADAS,ADAS_GW
 SG_ BIU3AC_7_1_HEADLAMP_LO_REQ : 57|1@1+ (1,0) [0|1] ""  ADAS,ADAS_GW
 SG_ BIU3AC_7_2_HEADLAMP_HI_REQ : 58|1@1+ (1,0) [0|1] ""  ADAS,ADAS_GW
 SG_ BIU3AC_7_3_FT_FOG_RELAY_REQ : 59|1@1+ (1,0) [0|1] ""  ADAS,ADAS_GW
 SG_ BIU3AC_7_4_FOGLAMP_RR : 60|1@1+ (1,0) [0|1] ""  ADAS_GW
 SG_ BIU3AC_7_5_DRL : 61|1@1+ (1,0) [0|1] ""  ADAS_GW
 SG_ BIU3AC_7_6_WIPER_FRONT : 62|1@1+ (1,0) [0|1] ""  ADAS,ADAS_GW
 SG_ BIU3AC_7_7_RDEF_RELAY_REQ : 63|1@1+ (1,0) [0|1] ""  ADAS_GW
 SG_ BIU3AC_6_0_RDEFOGSW : 48|1@1+ (1,0) [0|1] ""  ADAS_GW
 SG_ BIU3AC_6_1_CSTM_PRG : 49|1@1+ (1,0) [0|1] ""  ADAS_GW
 SG_ BIU3AC_6_2_FAIL_SHIFTLOCKSOL : 50|1@1+ (1,0) [0|1] ""  ADAS_GW
 SG_ BIU3AC_6_3_REQ_CANCEL_ISS : 51|1@1+ (1,0) [0|1] ""  ADAS_GW
 SG_ BIU3AC_6_4_REVERSE_MT : 52|1@1+ (1,0) [0|1] ""  ADAS_GW
 SG_ BIU3AC_6_5_HANDBRAKE : 53|1@1+ (1,0) [0|1] ""  ADAS,ADAS_GW
 SG_ BIU3AC_6_6_BRAKELAMPSW : 54|1@1+ (1,0) [0|1] ""  ADAS,ADAS_GW
 SG_ BIU3AC_6_7_TOWING_SW : 55|1@1+ (1,0) [0|1] ""  ADAS,ADAS_GW
 SG_ BIU3AC_5_0_LANE_OFF_SW : 40|2@1+ (1,0) [0|3] ""  ADAS_GW
 SG_ BIU3AC_5_2_PCR_OFF_SW : 42|2@1+ (1,0) [0|3] ""  ADAS_GW
 SG_ BIU3AC_5_4_DIMMER_CANCEL : 44|1@1+ (1,0) [0|1] ""  ADAS_GW
 SG_ BIU3AC_5_5_KEYSW : 45|1@1+ (1,0) [0|1] ""  ADAS_GW
 SG_ BIU3AC_5_6_IND_ND_SHIFTLOCK : 46|1@1+ (1,0) [0|1] ""  ADAS_GW
 SG_ BIU3AC_4_0_DOOR_DRVR : 32|1@1+ (1,0) [0|1] ""  ADAS,ADAS_GW,IPMS,VDC
 SG_ BIU3AC_4_1_DOOR_PASS : 33|1@1+ (1,0) [0|1] ""  ADAS,ADAS_GW,VDC
 SG_ BIU3AC_4_2_DOOR_RRRH : 34|1@1+ (1,0) [0|1] ""  ADAS,ADAS_GW,VDC
 SG_ BIU3AC_4_3_DOOR_RRLH : 35|1@1+ (1,0) [0|1] ""  ADAS,ADAS_GW,VDC
 SG_ BIU3AC_4_4_DOOR_RG : 36|1@1+ (1,0) [0|1] ""  ADAS_GW
 SG_ BIU3AC_4_5_DOOR_TR : 37|1@1+ (1,0) [0|1] ""  ADAS_GW
 SG_ BIU3AC_4_6_HOOD_CLOSE : 38|1@1+ (1,0) [0|1] ""  ADAS_GW
 SG_ BIU3AC_4_7_HOOD_OPEN : 39|1@1+ (1,0) [0|1] ""  ADAS_GW
 SG_ BIU3AC_3_0_GW_STSW_RES : 24|1@1+ (1,0) [0|1] ""  ADAS_GW
 SG_ BIU3AC_3_1_GW_POWER_RES : 25|2@1+ (1,0) [0|2] ""  ADAS_GW
 SG_ BIU3AC_3_3_ST1 : 27|1@1+ (1,0) [0|1] ""  ADAS_GW
 SG_ BIU3AC_3_4_ST2 : 28|1@1+ (1,0) [0|1] ""  ADAS_GW
 SG_ BIU3AC_3_5_ACC : 29|1@1+ (1,0) [0|1] ""  ADAS_GW
 SG_ BIU3AC_3_6_IGA : 30|1@1+ (1,0) [0|1] ""  ADAS_GW,IPMS,VDC
 SG_ BIU3AC_3_7_BAT_BACKUP : 31|1@1+ (1,0) [0|1] ""  ADAS_GW
 SG_ BIU3AC_2_0_CSTM_AC : 16|1@1+ (1,0) [0|1] ""  ADAS_GW
 SG_ BIU3AC_2_1_IMB_SMT : 17|2@1+ (1,0) [0|3] ""  ADAS_GW
 SG_ BIU3AC_2_3_CSTM_WGN_SDN : 19|1@1+ (1,0) [0|1] ""  ADAS,ADAS_GW
 SG_ BIU3AC_2_4_VAL_SEAT_BACK_CTSM : 20|1@1+ (1,0) [0|1] ""  ADAS_GW
 SG_ BIU3AC_2_5_VAL_MIR_AFOLD_CTSM : 21|1@1+ (1,0) [0|1] ""  ADAS_GW
 SG_ BIU3AC_2_6_VAL_MIR_RTILT_CTSM : 22|1@1+ (1,0) [0|1] ""  ADAS_GW
 SG_ BIU3AC_2_7_WIPER_REAR : 23|1@1+ (1,0) [0|1] ""  ADAS_GW
 SG_ BIU3AC_1_0_MSG_COUNTER : 8|4@1+ (1,0) [0|15] ""  ADAS,ADAS_GW,IPMS,VDC
 SG_ BIU3AC_1_4_PADDLESHIFT_DOWN_SW : 12|1@1+ (1,0) [0|1] ""  ADAS_GW
 SG_ BIU3AC_1_5_PADDLESHIFT_UP_SW : 13|1@1+ (1,0) [0|1] ""  ADAS_GW
 SG_ BIU3AC_1_6_MANUALMODE_SW : 14|1@1+ (1,0) [0|1] ""  ADAS_GW
 SG_ BIU3AC_0_0_CHECK_SUM : 0|8@1+ (1,0) [0|255] ""  ADAS,ADAS_GW,IPMS,VDC

BO_ 960 BIU3C0: 8 C_ECU_GW

BO_ 1616 BIU650: 8 C_ECU_GW
 SG_ BIU650_7_0_Reserved : 56|1@1+ (1,0) [0|1] "" Vector__XXX
 SG_ BIU650_7_1_Reserved : 57|1@1+ (1,0) [0|1] "" Vector__XXX
 SG_ BIU650_7_2_Reserved : 58|1@1+ (1,0) [0|1] "" Vector__XXX
 SG_ BIU650_7_3_DOOR_LINK_SW_STS : 59|1@1+ (1,0) [0|1] "" Vector__XXX
 SG_ BIU650_7_4_Reserved : 60|1@1+ (1,0) [0|1] "" Vector__XXX
 SG_ BIU650_6_0_Reserved : 48|3@1+ (1,0) [0|7] "" Vector__XXX
 SG_ BIU650_6_3_RR_WIPER_STATUS : 51|2@1+ (1,0) [0|3] "" Vector__XXX
 SG_ BIU650_6_5_WIPER_SENSITIVITY_CTM : 53|2@1+ (1,0) [0|3] "" Vector__XXX
 SG_ BIU650_5_0_Reserved : 40|1@1+ (1,0) [0|1] "" Vector__XXX
 SG_ BIU650_5_1_Reserved : 41|1@1+ (1,0) [0|1] "" Vector__XXX
 SG_ BIU650_5_2_FMH_DOOR_LOCK : 42|2@1+ (1,0) [0|3] "" Vector__XXX
 SG_ BIU650_5_4_LMH_DOOR_LOCK : 44|2@1+ (1,0) [0|3] "" Vector__XXX
 SG_ BIU650_4_0_REQ_OPE_AUTOLIGHT : 32|2@1+ (1,0) [0|3] "" Vector__XXX
 SG_ BIU650_4_2_STATE_SHINSSR : 34|2@1+ (1,0) [0|3] "" Vector__XXX
 SG_ BIU650_4_4_STATE_RLS_FAIL : 36|2@1+ (1,0) [0|3] "" Vector__XXX
 SG_ BIU650_3_0_REQ_FWASHER_ITLOCK : 24|1@1+ (1,0) [0|1] "" Vector__XXX
 SG_ BIU650_3_1_FWIPER_RTN : 25|1@1+ (1,0) [0|1] "" Vector__XXX
 SG_ BIU650_3_2_TURN_LAMP_STATE_LEFT : 26|1@1+ (1,0) [0|1] "" Vector__XXX
 SG_ BIU650_3_3_TURN_LAMP_STATE_RIGHT : 27|1@1+ (1,0) [0|1] "" Vector__XXX
 SG_ BIU650_3_4_Reserved : 28|1@1+ (1,0) [0|1] "" Vector__XXX
 SG_ BIU650_2_0_HEADLAMP_SMALL_SW : 16|1@1+ (1,0) [0|1] "" Vector__XXX
 SG_ BIU650_2_1_HEADLAMP_LO_SW : 17|1@1+ (1,0) [0|1] "" Vector__XXX
 SG_ BIU650_2_2_HEADLAMP_OFF_SW : 18|1@1+ (1,0) [0|1] "" Vector__XXX
 SG_ BIU650_2_3_HEADLAMP_Hi_SW : 19|1@1+ (1,0) [0|1] "" Vector__XXX
 SG_ BIU650_2_4_HEAD_LAMP_PASS_SW : 20|1@1+ (1,0) [0|1] "" Vector__XXX
 SG_ BIU650_2_5_FFOG_SW : 21|1@1+ (1,0) [0|1] "" Vector__XXX
 SG_ BIU650_2_6_RFOG_SW : 22|1@1+ (1,0) [0|1] "" Vector__XXX
 SG_ BIU650_1_0_MSG_COUNTER : 8|4@1+ (1,0) [0|15] "" Vector__XXX
 SG_ BIU650_0_0_CHECK_SUM : 0|8@1+ (1,0) [0|255] "" Vector__XXX

BO_ 1615 BIU64F: 8 C_ECU_GW
 SG_ BIU64F_4_0 : 32|4@1+ (1,0) [0|15] ""  IAVAS
 SG_ BIU64F_3_0 : 24|4@1+ (1,0) [0|15] ""  IAVAS
 SG_ BIU64F_2_0 : 16|5@1+ (1,0) [0|31] ""  IAVAS
 SG_ BIU64F_1_0_MSG_COUNTER : 8|4@1+ (1,0) [0|15] ""  IAVAS
 SG_ BIU64F_0_0_CHECK_SUM : 0|8@1+ (1,0) [0|255] ""  IAVAS

BO_ 305 R_STR131: 8 R_STR

BO_ 1350 EPS546: 8 EPS
 SG_ EPS546_0_0_NETWORK_STATUS : 0|64@1+ (1,0) [0|0] ""  C_ECU

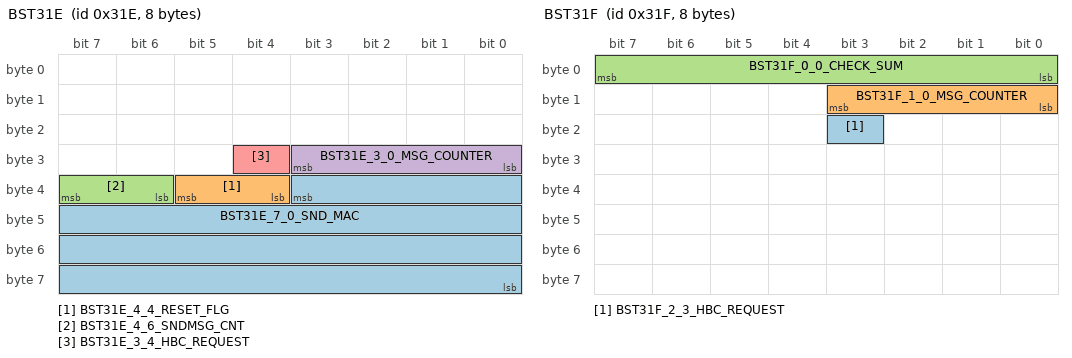
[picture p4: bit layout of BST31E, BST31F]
BO_ 798 BST31E: 8 BST
 SG_ BST31E_7_0_SND_MAC : 35|28@0+ (1,0) [0|268435455] ""  VDC
 SG_ BST31E_4_4_RESET_FLG : 37|2@0+ (1,0) [0|3] ""  VDC
 SG_ BST31E_4_6_SNDMSG_CNT : 39|2@0+ (1,0) [0|3] ""  VDC
 SG_ BST31E_3_0_MSG_COUNTER : 27|4@0+ (1,0) [0|15] ""  VDC
 SG_ BST31E_3_4_HBC_REQUEST : 28|1@0+ (1,0) [0|1] ""  VDC

BO_ 799 BST31F: 8 BST
 SG_ BST31F_2_3_HBC_REQUEST : 19|1@1+ (1,0) [0|1] ""  VDC
 SG_ BST31F_1_0_MSG_COUNTER : 8|4@1+ (1,0) [0|15] ""  VDC
 SG_ BST31F_0_0_CHECK_SUM : 0|8@1+ (1,0) [0|255] ""  VDC

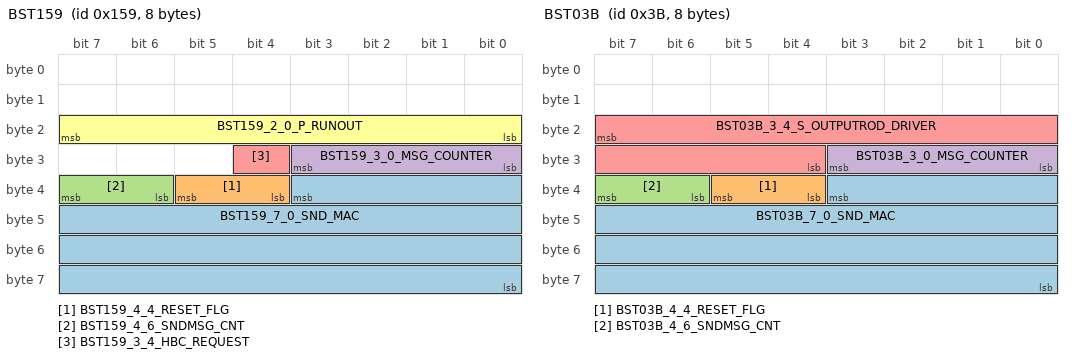
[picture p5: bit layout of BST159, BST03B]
BO_ 345 BST159: 8 BST
 SG_ BST159_7_0_SND_MAC : 35|28@0+ (1,0) [0|268435455] ""  VDC
 SG_ BST159_4_4_RESET_FLG : 37|2@0+ (1,0) [0|3] ""  VDC
 SG_ BST159_4_6_SNDMSG_CNT : 39|2@0+ (1,0) [0|3] ""  VDC
 SG_ BST159_3_0_MSG_COUNTER : 27|4@0+ (1,0) [0|15] ""  VDC
 SG_ BST159_3_4_HBC_REQUEST : 28|1@0+ (1,0) [0|1] ""  VDC
 SG_ BST159_2_0_P_RUNOUT : 23|8@0+ (1,0) [0|255] "bar"  VDC

BO_ 59 BST03B: 8 BST
 SG_ BST03B_7_0_SND_MAC : 35|28@0+ (1,0) [0|268435455] ""  VDC
 SG_ BST03B_4_4_RESET_FLG : 37|2@0+ (1,0) [0|3] ""  VDC
 SG_ BST03B_4_6_SNDMSG_CNT : 39|2@0+ (1,0) [0|3] ""  VDC
 SG_ BST03B_3_0_MSG_COUNTER : 27|4@0+ (1,0) [0|15] ""  VDC
 SG_ BST03B_3_4_S_OUTPUTROD_DRIVER : 23|12@0+ (0.015625,-5) [-5|47] "mm"  VDC

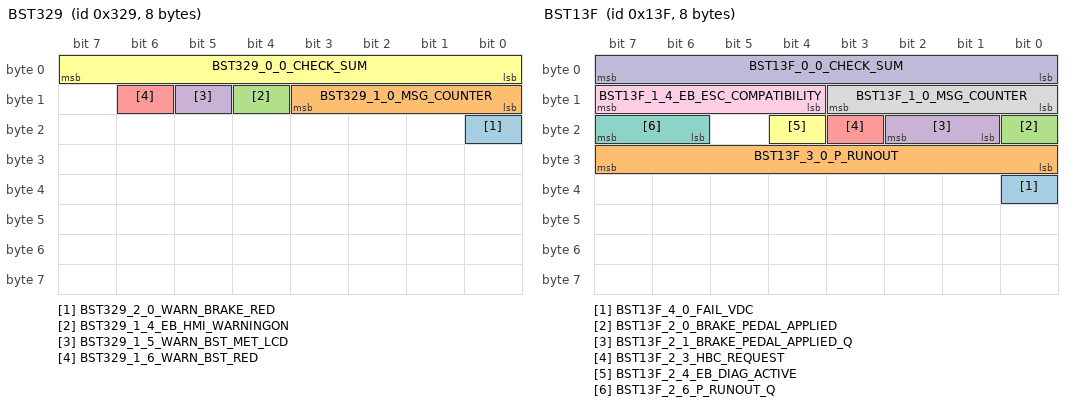
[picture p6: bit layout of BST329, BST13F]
BO_ 809 BST329: 8 BST
 SG_ BST329_2_0_WARN_BRAKE_RED : 16|1@1+ (1,0) [0|1] ""  C_ECU_GW
 SG_ BST329_1_0_MSG_COUNTER : 8|4@1+ (1,0) [0|15] ""  ABG,C_ECU_GW
 SG_ BST329_1_4_EB_HMI_WARNINGON : 12|1@1+ (1,0) [0|1] ""  C_ECU_GW
 SG_ BST329_1_5_WARN_BST_MET_LCD : 13|1@1+ (1,0) [0|1] ""  C_ECU_GW
 SG_ BST329_1_6_WARN_BST_RED : 14|1@1+ (1,0) [0|1] ""  C_ECU_GW
 SG_ BST329_0_0_CHECK_SUM : 0|8@1+ (1,0) [0|255] ""  ABG,C_ECU_GW

BO_ 319 BST13F: 8 BST
 SG_ BST13F_4_0_FAIL_VDC : 32|1@1+ (1,0) [0|1] ""  VDC
 SG_ BST13F_3_0_P_RUNOUT : 24|8@1+ (1,0) [0|255] "bar"  VDC
 SG_ BST13F_2_0_BRAKE_PEDAL_APPLIED : 16|1@1+ (1,0) [0|1] ""  VDC
 SG_ BST13F_2_1_BRAKE_PEDAL_APPLIED_Q : 17|2@1+ (1,0) [0|3] ""  VDC
 SG_ BST13F_2_3_HBC_REQUEST : 19|1@1+ (1,0) [0|1] ""  VDC
 SG_ BST13F_2_4_EB_DIAG_ACTIVE : 20|1@1+ (1,0) [0|1] ""  VDC
 SG_ BST13F_2_6_P_RUNOUT_Q : 22|2@1+ (1,0) [0|3] ""  VDC
 SG_ BST13F_1_0_MSG_COUNTER : 8|4@1+ (1,0) [0|15] ""  VDC
 SG_ BST13F_1_4_EB_ESC_COMPATIBILITY : 12|4@1+ (1,0) [0|15] ""  VDC
 SG_ BST13F_0_0_CHECK_SUM : 0|8@1+ (1,0) [0|255] ""  VDC

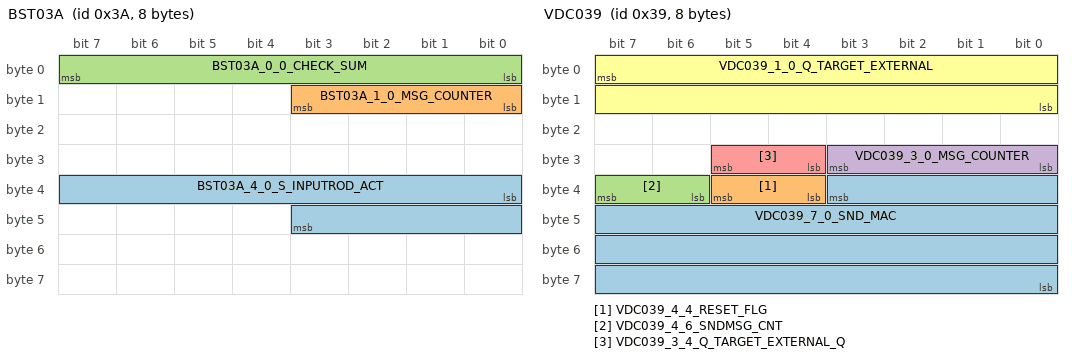
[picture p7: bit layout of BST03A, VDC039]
BO_ 58 BST03A: 8 BST
 SG_ BST03A_4_0_S_INPUTROD_ACT : 32|12@1+ (0.015625,-5) [-5|47] "mm"  ABG
 SG_ BST03A_1_0_MSG_COUNTER : 8|4@1+ (1,0) [0|15] ""  ABG
 SG_ BST03A_0_0_CHECK_SUM : 0|8@1+ (1,0) [0|255] ""  ABG

BO_ 1282 BST502: 8 BST
 SG_ BST502_1_4_ActiveWakeUpBit : 12|1@1+ (1,0) [0|1] ""  IAVAS,VDC,C_ECU
 SG_ BST502_0_0_SourceNodeID : 0|8@1+ (1,0) [0|255] ""  IAVAS,VDC,C_ECU

BO_ 811 EPB32B: 8 VDC
 SG_ EPB32B_7_0_AVH_TARGET_PRESS : 56|8@1+ (0.0235,0) [0|255] "MPa"  C_ECU_GW
 SG_ EPB32B_6_0_VEHICLE_RUN_STOP_FLG : 48|2@1+ (1,0) [0|3] ""  ABG,C_ECU_GW
 SG_ EPB32B_6_2_REQ_HILL_P_CAUTION : 50|1@1+ (1,0) [0|1] ""  C_ECU_GW
 SG_ EPB32B_5_0_FLG_AVH_OILPRES_EPB : 40|1@1+ (1,0) [0|1] ""  C_ECU_GW
 SG_ EPB32B_5_1_FLG_AVH : 41|1@1+ (1,0) [0|1] ""  ADAS,BEV,C_ECU_GW
 SG_ EPB32B_5_2_AVH_INTENSIFY_PRES : 42|1@1+ (1,0) [0|1] ""  C_ECU_GW
 SG_ EPB32B_5_3_BREAK_IND : 43|2@1+ (1,0) [0|3] ""  C_ECU_GW
 SG_ EPB32B_5_5_AVH_ON_LAMP : 45|1@1+ (1,0) [0|1] ""  C_ECU_GW
 SG_ EPB32B_5_6_AVH_FUNC_ON_LUMP : 46|1@1+ (1,0) [0|1] ""  ADAS,C_ECU_GW
 SG_ EPB32B_5_7_AVH_ACTIVE : 47|1@1+ (1,0) [0|1] ""  ADAS,C_ECU_GW
 SG_ EPB32B_4_0_BUZZER : 32|2@1+ (1,0) [0|3] ""  C_ECU_GW
 SG_ EPB32B_4_2_HILL_HOLD_ON_LAMP : 34|1@1+ (1,0) [0|1] ""  C_ECU_GW
 SG_ EPB32B_4_3_CLAMP_LAMP : 35|2@1+ (1,0) [0|3] ""  C_ECU_GW
 SG_ EPB32B_4_5_WARN_LAMP : 37|2@1+ (1,0) [0|3] ""  C_ECU_GW
 SG_ EPB32B_4_7_WARN_EPB_MET_LCD : 39|1@1+ (1,0) [0|1] ""  C_ECU_GW
 SG_ EPB32B_3_0_STATUS_EPB : 24|3@1+ (1,0) [0|7] ""  ADAS,THM,BEV,ABG,IPMS,C_ECU,C_ECU_GW
 SG_ EPB32B_3_3_DYNAMIC_PARKING : 27|1@1+ (1,0) [0|1] ""  ADAS,C_ECU_GW
 SG_ EPB32B_3_4_HILL_HOLD_RUN_FLG : 28|1@1+ (1,0) [0|1] ""  ADAS,C_ECU_GW
 SG_ EPB32B_3_5_INHIBIT_ISS_DELAY : 29|1@1+ (1,0) [0|1] ""  C_ECU_GW
 SG_ EPB32B_3_6_INHIBIT_ISS : 30|1@1+ (1,0) [0|1] ""  C_ECU_GW
 SG_ EPB32B_3_7_AVH_PERMIT_CONT_ACC : 31|1@1+ (1,0) [0|1] ""  ADAS,C_ECU_GW
 SG_ EPB32B_2_0_ERR_INFO : 16|2@1+ (1,0) [0|3] ""  C_ECU_GW
 SG_ EPB32B_2_2_EPB_FAIL_FLG1 : 18|1@1+ (1,0) [0|1] ""  ADAS,C_ECU_GW
 SG_ EPB32B_2_3_EPB_FAIL_FLG2 : 19|1@1+ (1,0) [0|1] ""  ADAS,C_ECU_GW
 SG_ EPB32B_2_4_EPB_FAIL_FLG3 : 20|1@1+ (1,0) [0|1] ""  ADAS,C_ECU_GW
 SG_ EPB32B_1_0_MSG_COUNTER : 8|4@1+ (1,0) [0|15] ""  ADAS,THM,BEV,ABG,C_ECU_GW
 SG_ EPB32B_1_4_WAKE_UP_FRAME : 12|1@1+ (1,0) [0|1] ""  C_ECU_GW
 SG_ EPB32B_1_5_REQ_COMM_CONT : 13|1@1+ (1,0) [0|1] ""  C_ECU_GW
 SG_ EPB32B_1_6 : 14|1@1+ (1,0) [0|1] ""  C_ECU_GW
 SG_ EPB32B_0_0_CHECK_SUM : 0|8@1+ (1,0) [0|255] ""  ADAS,THM,BEV,ABG,C_ECU_GW

BO_ 1281 EPB501: 8 VDC
 SG_ EPB501_1_4_ActiveWakeUpBit : 12|1@1+ (1,0) [0|1] ""  IAVAS,BST,C_ECU
 SG_ EPB501_0_0_SourceNodeID : 0|8@1+ (1,0) [0|255] ""  IAVAS,BST,C_ECU

BO_ 57 VDC039: 8 VDC
 SG_ VDC039_7_0_SND_MAC : 35|28@0+ (1,0) [0|268435455] ""  BST
 SG_ VDC039_4_4_RESET_FLG : 37|2@0+ (1,0) [0|3] ""  BST
 SG_ VDC039_4_6_SNDMSG_CNT : 39|2@0+ (1,0) [0|3] ""  BST
 SG_ VDC039_3_0_MSG_COUNTER : 27|4@0+ (1,0) [0|15] ""  BST
 SG_ VDC039_3_4_Q_TARGET_EXTERNAL_Q : 29|2@0+ (1,0) [0|3] ""  BST
 SG_ VDC039_1_0_Q_TARGET_EXTERNAL : 7|16@0+ (0.0078125,-252) [-252|252] "ml/s"  BST

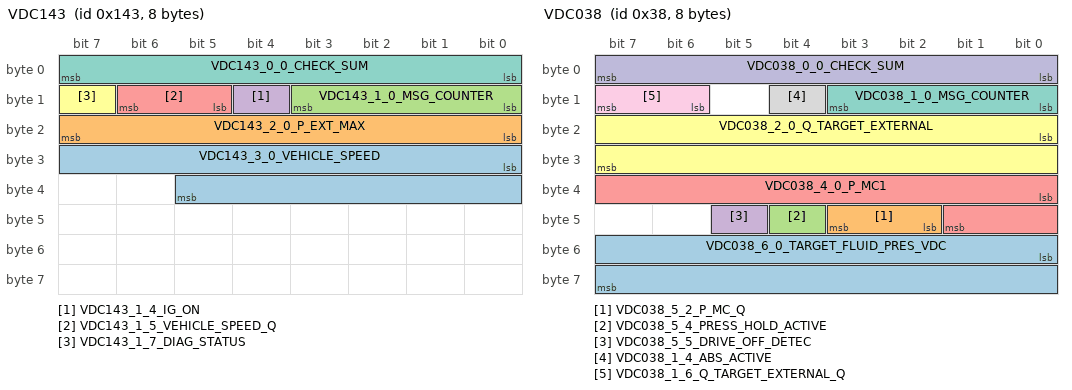
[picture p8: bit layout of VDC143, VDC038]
BO_ 323 VDC143: 8 VDC
 SG_ VDC143_3_0_VEHICLE_SPEED : 24|14@1+ (0.05625,0) [0|299.98125] "km/h"  ABG,C_ECU,C_ECU_GW
 SG_ VDC143_2_0_P_EXT_MAX : 16|8@1+ (1,0) [0|250] "bar"  C_ECU_GW
 SG_ VDC143_1_0_MSG_COUNTER : 8|4@1+ (1,0) [0|15] ""  ABG,C_ECU_GW
 SG_ VDC143_1_4_IG_ON : 12|1@1+ (1,0) [0|1] ""  C_ECU_GW
 SG_ VDC143_1_5_VEHICLE_SPEED_Q : 13|2@1+ (1,0) [0|3] ""  C_ECU_GW
 SG_ VDC143_1_7_DIAG_STATUS : 15|1@1+ (1,0) [0|1] ""  C_ECU_GW
 SG_ VDC143_0_0_CHECK_SUM : 0|8@1+ (1,0) [0|255] ""  ABG,C_ECU_GW

BO_ 56 VDC038: 8 VDC
 SG_ VDC038_6_0_TARGET_FLUID_PRES_VDC : 48|16@1+ (0.005,0) [0|15] "Mpa"  BST
 SG_ VDC038_5_2_P_MC_Q : 42|2@1+ (1,0) [0|3] ""  BST
 SG_ VDC038_5_4_PRESS_HOLD_ACTIVE : 44|1@1+ (1,0) [0|1] ""  BST
 SG_ VDC038_5_5_DRIVE_OFF_DETEC : 45|1@1+ (1,0) [0|1] ""  BST
 SG_ VDC038_4_0_P_MC1 : 32|10@1+ (0.3,-30) [-30|276.6] "bar"  BST
 SG_ VDC038_2_0_Q_TARGET_EXTERNAL : 16|16@1+ (0.0078125,-252) [-252|252] "ml/s"  BST
 SG_ VDC038_1_0_MSG_COUNTER : 8|4@1+ (1,0) [0|15] ""  BST
 SG_ VDC038_1_4_ABS_ACTIVE : 12|1@1+ (1,0) [0|1] ""  BST
 SG_ VDC038_1_6_Q_TARGET_EXTERNAL_Q : 14|2@1+ (1,0) [0|3] ""  BST
 SG_ VDC038_0_0_CHECK_SUM : 0|8@1+ (1,0) [0|255] ""  BST

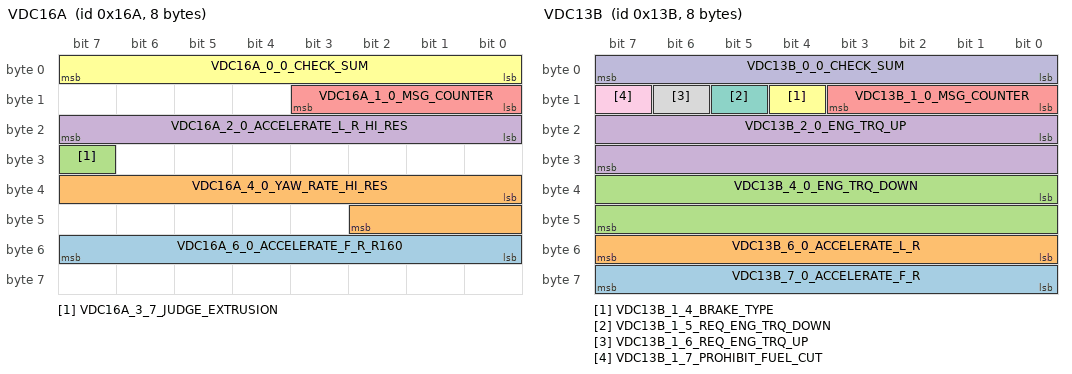
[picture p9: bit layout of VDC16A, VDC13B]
BO_ 362 VDC16A: 8 VDC
 SG_ VDC16A_6_0_ACCELERATE_F_R_R160 : 48|8@1- (0.2,0) [-17.6|17.6] "m/s^2"  ABG,C_ECU_GW
 SG_ VDC16A_4_0_YAW_RATE_HI_RES : 32|11@1- (0.1,0) [-85|85] "deg/s"  ABG,C_ECU_GW
 SG_ VDC16A_3_7_JUDGE_EXTRUSION : 31|1@1+ (1,0) [0|1] ""  C_ECU_GW
 SG_ VDC16A_2_0_ACCELERATE_L_R_HI_RES : 16|8@1- (0.1,0) [-7|7] "m/s2"  ADAS,C_ECU_GW
 SG_ VDC16A_1_0_MSG_COUNTER : 8|4@1+ (1,0) [0|15] ""  ADAS,ABG,C_ECU_GW
 SG_ VDC16A_0_0_CHECK_SUM : 0|8@1+ (1,0) [0|255] ""  ADAS,ABG,C_ECU_GW

BO_ 808 VDC328: 8 VDC
 SG_ VDC328_7_1_IND_WARN_CBC : 57|1@1+ (1,0) [0|1] ""  ADAS,C_ECU_GW
 SG_ VDC328_7_2_ACTIVATE_CBC : 58|1@1+ (1,0) [0|1] ""  ADAS,C_ECU_GW
 SG_ VDC328_7_3_FLAG_ACT_CBC : 59|1@1+ (1,0) [0|1] ""  BEV,C_ECU_GW
 SG_ VDC328_6_0_PROHIBIT_VDC_OFF_CCU : 48|1@1+ (1,0) [0|1] ""  C_ECU_GW
 SG_ VDC328_6_1_PROHIBIT_AVH_CCU : 49|1@1+ (1,0) [0|1] ""  C_ECU_GW
 SG_ VDC328_5_0_VDC_BUZZER : 40|2@1+ (1,0) [0|3] ""  C_ECU_GW
 SG_ VDC328_5_2_WARN_BRAKE_BOOST : 42|1@1+ (1,0) [0|1] ""  ABG,C_ECU_GW
 SG_ VDC328_5_4_WARN_RBS : 44|2@1+ (1,0) [0|3] ""  C_ECU_GW
 SG_ VDC328_5_6_IND_HSA_ON : 46|1@1+ (1,0) [0|1] ""  C_ECU_GW
 SG_ VDC328_5_7_IND_TCS_OFF : 47|1@1+ (1,0) [0|1] ""  C_ECU_GW
 SG_ VDC328_4_0_IND_VDC_OFF : 32|1@1+ (1,0) [0|1] ""  ADAS,BEV,ABG,C_ECU_GW
 SG_ VDC328_4_1_STATE_ACTIVATE_VDC : 33|1@1+ (1,0) [0|1] ""  BEV,C_ECU_GW
 SG_ VDC328_4_2_IND_HSA_OFF : 34|1@1+ (1,0) [0|1] ""  C_ECU_GW
 SG_ VDC328_4_3_IND_HDC : 35|2@1+ (1,0) [0|3] ""  C_ECU_GW
 SG_ VDC328_4_5_WARNING_BRAKE_SYS : 37|2@1+ (1,0) [0|3] ""  C_ECU_GW
 SG_ VDC328_4_7_ACTIVE_OHB : 39|1@1+ (1,0) [0|1] ""  C_ECU_GW
 SG_ VDC328_3_0_IND_WARN_EBD : 24|1@1+ (1,0) [0|1] ""  ABG,C_ECU_GW
 SG_ VDC328_3_1_IND_WARN_ABS : 25|1@1+ (1,0) [0|1] ""  C_ECU_GW
 SG_ VDC328_3_2_IND_WARN_VDC : 26|1@1+ (1,0) [0|1] ""  ABG,C_ECU_GW
 SG_ VDC328_3_3_IND_WARN_HSA : 27|1@1+ (1,0) [0|1] ""  C_ECU_GW
 SG_ VDC328_3_4_WARN_BRAKEFLUID_LV : 28|2@1+ (1,0) [0|3] ""  ABG,C_ECU_GW
 SG_ VDC328_3_6_IND_TCS_OFF : 30|1@1+ (1,0) [0|1] ""  ADAS,BEV,C_ECU_GW
 SG_ VDC328_3_7_EXIST_EPB : 31|1@1+ (1,0) [0|1] ""  ADAS,C_ECU_GW
 SG_ VDC328_2_0_WARN_EBD_MET_LCD : 16|1@1+ (1,0) [0|1] ""  C_ECU_GW
 SG_ VDC328_2_1_WARN_ABS_MET_LCD : 17|1@1+ (1,0) [0|1] ""  C_ECU_GW
 SG_ VDC328_2_2_WARN_VDC_MET_LCD : 18|1@1+ (1,0) [0|1] ""  C_ECU_GW
 SG_ VDC328_2_3_WARN_HSA_MET_LCD : 19|1@1+ (1,0) [0|1] ""  C_ECU_GW
 SG_ VDC328_2_4_EXIST_VECTARING : 20|1@1+ (1,0) [0|1] ""  C_ECU_GW
 SG_ VDC328_1_0_MSG_COUNTER : 8|4@1+ (1,0) [0|15] ""  ADAS,BEV,ABG,C_ECU_GW
 SG_ VDC328_0_0_CHECK_SUM : 0|8@1+ (1,0) [0|255] ""  ADAS,BEV,ABG,C_ECU_GW

BO_ 316 VDC13C: 8 VDC
 SG_ VDC13C_7_0_RCV_FAIL_ADA : 56|1@1+ (1,0) [0|1] ""  ADAS,ADAS_GW,C_ECU_GW
 SG_ VDC13C_7_1_FAIL_PCU : 57|1@1+ (1,0) [0|1] ""  ADAS,ADAS_GW,C_ECU_GW
 SG_ VDC13C_7_2_CONT_STATE_ES_BRAKE : 58|1@1+ (1,0) [0|1] ""  ADAS,ADAS_GW,C_ECU_GW
 SG_ VDC13C_7_3_ASST_PRECRUSH_ACC : 59|1@1+ (1,0) [0|1] ""  ADAS,ADAS_GW,C_ECU_GW
 SG_ VDC13C_7_4_CONT_STATE_PRECRUSH : 60|1@1+ (1,0) [0|1] ""  ADAS,ADAS_GW,C_ECU_GW
 SG_ VDC13C_7_5_PERMIT_BRAKE_ACC : 61|1@1+ (1,0) [0|1] ""  ADAS,ADAS_GW,BST,C_ECU_GW
 SG_ VDC13C_7_6_DETECT_BRAKING : 62|1@1+ (1,0) [0|1] ""  ADAS,ADAS_GW,EPS,C_ECU_GW
 SG_ VDC13C_7_7_EMERGENCY_BRAKE : 63|1@1+ (1,0) [0|1] ""  ADAS_GW,C_ECU_GW
 SG_ VDC13C_6_0_SPD_PULSE_INTEGRAL : 48|6@1+ (1,0) [0|63] ""  ADAS_GW,C_ECU_GW
 SG_ VDC13C_6_6_VDC_OFF : 54|1@1+ (1,0) [0|1] ""  ADAS,ADAS_GW,BEV,C_ECU_GW
 SG_ VDC13C_6_7_STBY_PREVIEW_VDC : 55|1@1+ (1,0) [0|1] ""  ADAS,ADAS_GW,C_ECU_GW
 SG_ VDC13C_5_0_SPD_PULSE_RRRH : 40|7@1+ (1,0) [0|95] ""  ADAS,ADAS_GW,LCT,C_ECU_GW
 SG_ VDC13C_5_7_ACTIVATE_TSM : 47|1@1+ (1,0) [0|1] ""  ADAS,ADAS_GW,C_ECU_GW
 SG_ VDC13C_4_0_SPD_PULSE_RRLH : 32|7@1+ (1,0) [0|95] ""  ADAS,ADAS_GW,LCT,C_ECU_GW
 SG_ VDC13C_4_7_ACTIVATE_RMI : 39|1@1+ (1,0) [0|1] ""  ADAS,ADAS_GW,C_ECU_GW
 SG_ VDC13C_3_0_SPD_PULSE_FTRH : 24|7@1+ (1,0) [0|95] ""  ADAS,ADAS_GW,LCT,C_ECU_GW
 SG_ VDC13C_3_7_ACTIVATE_VECTARING : 31|1@1+ (1,0) [0|1] ""  ADAS,ADAS_GW,C_ECU_GW
 SG_ VDC13C_2_0_SPD_PULSE_FTLH : 16|7@1+ (1,0) [0|95] ""  ADAS,ADAS_GW,LCT,C_ECU_GW
 SG_ VDC13C_2_7_STATE_ACTIVATE_HSA : 23|1@1+ (1,0) [0|1] ""  ADAS,ADAS_GW,C_ECU_GW
 SG_ VDC13C_1_0_MSG_COUNTER : 8|4@1+ (1,0) [0|15] ""  ADAS,ADAS_GW,BEV,LCT,EPS,BST,C_ECU_GW
 SG_ VDC13C_1_4_ACTIVE_BRAKEHOLD : 12|1@1+ (1,0) [0|1] ""  ADAS_GW,C_ECU_GW
 SG_ VDC13C_1_5_PROHIBIT_BRAKEHOLD : 13|1@1+ (1,0) [0|1] ""  ADAS_GW,C_ECU_GW
 SG_ VDC13C_1_6_BRAKELAMP_RELAY : 14|1@1+ (1,0) [0|1] ""  ADAS,ADAS_GW,C_ECU_GW
 SG_ VDC13C_1_7_STATUS_BRAKELAMP : 15|1@1+ (1,0) [0|1] ""  ADAS_GW,C_ECU_GW
 SG_ VDC13C_0_0_CHECK_SUM : 0|8@1+ (1,0) [0|255] ""  ADAS,ADAS_GW,BEV,LCT,EPS,BST,C_ECU_GW

BO_ 315 VDC13B: 8 VDC
 SG_ VDC13B_7_0_ACCELERATE_F_R : 56|8@1- (0.1,0) [-12.5|12.5] "m/s^2"  ADAS,ADAS_GW,C_ECU,C_ECU_GW
 SG_ VDC13B_6_0_ACCELERATE_L_R : 48|8@1- (0.1923,0) [-17.64|17.64] "m/s^2"  ADAS,ADAS_GW,ABG,EPS,C_ECU,C_ECU_GW
 SG_ VDC13B_4_0_ENG_TRQ_DOWN : 32|16@1+ (0.1,-1000) [-1000|5553.5] "Nm"  ADAS_GW,C_ECU_GW
 SG_ VDC13B_2_0_ENG_TRQ_UP : 16|16@1+ (0.1,-1000) [-1000|5553.5] "Nm"  ADAS_GW,C_ECU_GW
 SG_ VDC13B_1_0_MSG_COUNTER : 8|4@1+ (1,0) [0|15] ""  ADAS,ADAS_GW,ABG,EPS,C_ECU_GW
 SG_ VDC13B_1_4_BRAKE_TYPE : 12|1@1+ (1,0) [0|1] ""  ADAS,ADAS_GW,C_ECU_GW
 SG_ VDC13B_1_5_REQ_ENG_TRQ_DOWN : 13|1@1+ (1,0) [0|1] ""  ADAS_GW,C_ECU_GW
 SG_ VDC13B_1_6_REQ_ENG_TRQ_UP : 14|1@1+ (1,0) [0|1] ""  ADAS_GW,C_ECU_GW
 SG_ VDC13B_1_7_PROHIBIT_FUEL_CUT : 15|1@1+ (1,0) [0|1] ""  ADAS_GW,C_ECU_GW
 SG_ VDC13B_0_0_CHECK_SUM : 0|8@1+ (1,0) [0|255] ""  ADAS,ADAS_GW,ABG,EPS,C_ECU_GW

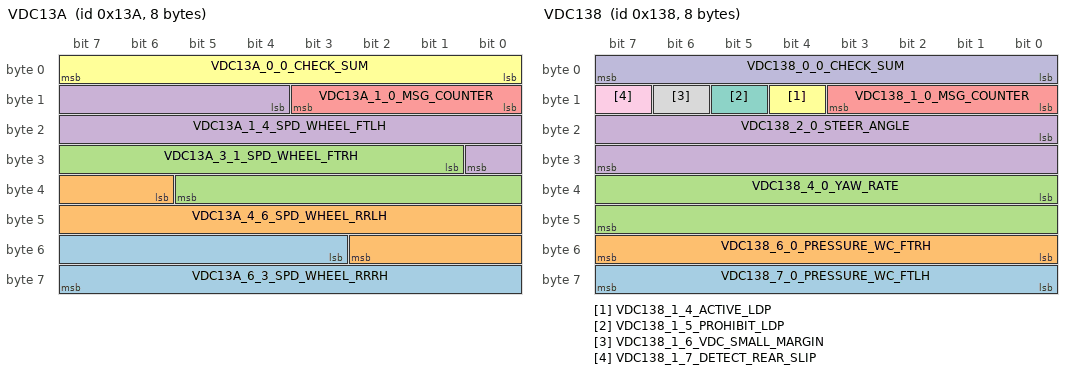
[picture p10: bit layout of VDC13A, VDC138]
BO_ 314 VDC13A: 8 VDC
 SG_ VDC13A_6_3_SPD_WHEEL_RRRH : 51|13@1+ (0.05625,0) [0|299.98125] "km/h"  ADAS,ADAS_GW,EPS,C_ECU_GW
 SG_ VDC13A_4_6_SPD_WHEEL_RRLH : 38|13@1+ (0.05625,0) [0|299.98125] "km/h"  ADAS,ADAS_GW,EPS,C_ECU_GW
 SG_ VDC13A_3_1_SPD_WHEEL_FTRH : 25|13@1+ (0.05625,0) [0|299.98125] "km/h"  ADAS,ADAS_GW,EPS,C_ECU_GW
 SG_ VDC13A_1_4_SPD_WHEEL_FTLH : 12|13@1+ (0.05625,0) [0|299.98125] "km/h"  ADAS,ADAS_GW,EPS,C_ECU_GW
 SG_ VDC13A_1_0_MSG_COUNTER : 8|4@1+ (1,0) [0|15] ""  ADAS,ADAS_GW,EPS,C_ECU_GW
 SG_ VDC13A_0_0_CHECK_SUM : 0|8@1+ (1,0) [0|255] ""  ADAS,ADAS_GW,EPS,C_ECU_GW

BO_ 313 VDC139: 8 VDC
 SG_ VDC139_7_4_FAIL_PRESSURE_SSR : 60|1@1+ (1,0) [0|1] ""  ADAS,ADAS_GW,BEV,C_ECU_GW
 SG_ VDC139_7_5_STATUS_EPB : 61|3@1+ (1,0) [0|7] ""  ADAS_GW,EPS,C_ECU_GW
 SG_ VDC139_6_0_SSR_N_PRESS : 48|12@1+ (1,0) [193|3896] ""  ADAS_GW,C_ECU_GW
 SG_ VDC139_5_0_PRESSURE_BRAKE : 40|8@1+ (0.13058823529412,0) [0|25] "MPa"  ADAS,ADAS_GW,BEV,ABG,C_ECU,C_ECU_GW
 SG_ VDC139_4_0_HDC_STATUS : 32|2@1+ (1,0) [0|3] ""  ADAS,ADAS_GW,BEV,C_ECU_GW
 SG_ VDC139_4_2_BRAKELAMPSW : 34|1@1+ (1,0) [0|1] ""  ADAS,ADAS_GW,BEV,ABG,C_ECU_GW
 SG_ VDC139_4_3_FAIL_BRAKELAMPSW : 35|1@1+ (1,0) [0|1] ""  ADAS,ADAS_GW,BEV,C_ECU_GW
 SG_ VDC139_4_4_ACTIVATE_ABS : 36|1@1+ (1,0) [0|1] ""  ADAS,ADAS_GW,ABG,C_ECU_GW
 SG_ VDC139_4_5_ACTIVATE_TCS : 37|1@1+ (1,0) [0|1] ""  ADAS,ADAS_GW,BEV,ABG,C_ECU_GW
 SG_ VDC139_4_6_CONT_OVER_STR : 38|1@1+ (1,0) [0|1] ""  ADAS,ADAS_GW,BEV,ABG,C_ECU_GW
 SG_ VDC139_4_7_CONT_UNDER_STR : 39|1@1+ (1,0) [0|1] ""  ADAS,ADAS_GW,BEV,ABG,C_ECU_GW
 SG_ VDC139_3_5_FAIL_VDC_SSR : 29|1@1+ (1,0) [0|1] ""  ADAS,ADAS_GW,EPS,C_ECU_GW
 SG_ VDC139_3_6_FAIL_SPD_SSR_FHI : 30|1@1+ (1,0) [0|1] ""  ADAS,ADAS_GW,BEV,LCT,EPS,C_ECU_GW
 SG_ VDC139_3_7_FAIL_ABS_SYS : 31|1@1+ (1,0) [0|1] ""  ADAS,ADAS_GW,BEV,ABG,C_ECU_GW
 SG_ VDC139_2_0_SPD_WHEEL_AVE : 16|13@1+ (0.05625,0) [0|299.98125] "km/h"  IAVAS,ADAS,ADAS_GW,LCT,EPS,IPMS,C_ECU,C_ECU_GW
 SG_ VDC139_1_0_MSG_COUNTER : 8|4@1+ (1,0) [0|15] ""  IAVAS,ADAS,ADAS_GW,BEV,LCT,ABG,EPS,IPMS,C_ECU,C_ECU_GW
 SG_ VDC139_1_4_FAIL_HDC_SYS : 12|1@1+ (1,0) [0|1] ""  ADAS,ADAS_GW,BEV,C_ECU_GW
 SG_ VDC139_1_5_VEHICLE_HIGHT : 13|2@1+ (1,0) [0|2] ""  ADAS,ADAS_GW,EPS,C_ECU_GW
 SG_ VDC139_1_7_REPROGRAMING : 15|1@1+ (1,0) [0|1] ""  ADAS_GW,EPS,C_ECU_GW
 SG_ VDC139_0_0_CHECK_SUM : 0|8@1+ (1,0) [0|255] ""  IAVAS,ADAS,ADAS_GW,BEV,LCT,ABG,EPS,IPMS,C_ECU,C_ECU_GW

BO_ 312 VDC138: 8 VDC
 SG_ VDC138_7_0_PRESSURE_WC_FTLH : 56|8@1+ (0.08,0) [0|20.4] "MPa"  ADAS,ADAS_GW,C_ECU_GW
 SG_ VDC138_6_0_PRESSURE_WC_FTRH : 48|8@1+ (0.08,0) [0|20.4] "MPa"  ADAS,ADAS_GW,C_ECU_GW
 SG_ VDC138_4_0_YAW_RATE : 32|16@1- (0.0047358121330724,0) [-1.571|1.571] "rad/s"  ADAS,ADAS_GW,EPS,C_ECU,C_ECU_GW
 SG_ VDC138_2_0_STEER_ANGLE : 16|16@1- (0.1,0) [-719.9|719.9] "deg"  ADAS,ADAS_GW,ABG,EPS,IPMS,C_ECU,C_ECU_GW
 SG_ VDC138_1_0_MSG_COUNTER : 8|4@1+ (1,0) [0|15] ""  ADAS,ADAS_GW,ABG,EPS,IPMS,C_ECU_GW
 SG_ VDC138_1_4_ACTIVE_LDP : 12|1@1+ (1,0) [0|1] ""  ADAS_GW,C_ECU_GW
 SG_ VDC138_1_5_PROHIBIT_LDP : 13|1@1+ (1,0) [0|1] ""  ADAS_GW,C_ECU_GW
 SG_ VDC138_1_6_VDC_SMALL_MARGIN : 14|1@1+ (1,0) [0|1] ""  ADAS_GW,C_ECU_GW
 SG_ VDC138_1_7_DETECT_REAR_SLIP : 15|1@1+ (1,0) [0|1] ""  ADAS,ADAS_GW,C_ECU_GW
 SG_ VDC138_0_0_CHECK_SUM : 0|8@1+ (1,0) [0|255] ""  ADAS,ADAS_GW,ABG,EPS,IPMS,C_ECU_GW

BO_ 309 VDC135: 8 VDC

BO_ 308 VDC134: 8 VDC

BO_ 503 IPMS1F7: 64 IPMS

BO_ 502 IPMS1F6: 64 IPMS

BO_ 501 IPMS1F5: 64 IPMS

BO_ 500 IPMS1F4: 64 IPMS

BO_ 947 IPMS3B3: 32 IPMS
 SG_ IPMS3B3_4_0_JUDGE_LEAN_FORWARD : 32|1@1+ (1,0) [0|1] ""  C_ECU_GW
 SG_ IPMS3B3_4_1_JUDGE_LOOK_DOWN : 33|1@1+ (1,0) [0|1] ""  C_ECU_GW
 SG_ IPMS3B3_4_2_JUDGE_LEAN_BACK : 34|1@1+ (1,0) [0|1] ""  C_ECU_GW
 SG_ IPMS3B3_4_3_JUDGE_BEND_BACKWARD : 35|1@1+ (1,0) [0|1] ""  C_ECU_GW
 SG_ IPMS3B3_4_4_JUDGE_TILT_HEAD : 36|1@1+ (1,0) [0|1] ""  C_ECU_GW
 SG_ IPMS3B3_4_5_JUDGE_FALL_SIDEWAYS : 37|1@1+ (1,0) [0|1] ""  C_ECU_GW
 SG_ IPMS3B3_4_6_JUDGE_LEAN_AGAINST : 38|1@1+ (1,0) [0|1] ""  C_ECU_GW
 SG_ IPMS3B3_3_0_JUDGE_LOSING_POSTURE : 24|1@1+ (1,0) [0|1] ""  ADAS,C_ECU_GW
 SG_ IPMS3B3_3_1_JUDGE_SHORT_DIST : 25|1@1+ (1,0) [0|1] ""  ADAS,C_ECU_GW
 SG_ IPMS3B3_3_2_JUDGE_MICRO_SLEEP : 26|1@1+ (1,0) [0|1] ""  ADAS,C_ECU_GW
 SG_ IPMS3B3_2_0_E2E_COUNTER : 16|8@1+ (1,0) [0|255] ""  ADAS,C_ECU_GW
 SG_ IPMS3B3_0_0_E2E_CRC : 0|16@1+ (1,0) [0|65535] ""  ADAS,C_ECU_GW

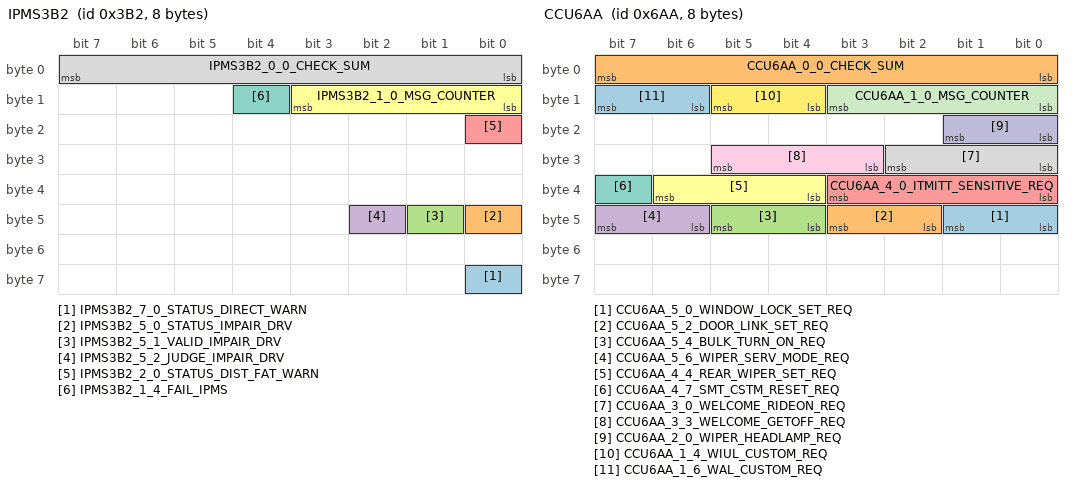
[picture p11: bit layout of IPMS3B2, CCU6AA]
BO_ 946 IPMS3B2: 8 IPMS
 SG_ IPMS3B2_7_0_STATUS_DIRECT_WARN : 56|1@1+ (1,0) [0|0] ""  C_ECU_GW
 SG_ IPMS3B2_5_0_STATUS_IMPAIR_DRV : 40|1@1+ (1,0) [0|1] ""  C_ECU,C_ECU_GW
 SG_ IPMS3B2_5_1_VALID_IMPAIR_DRV : 41|1@1+ (1,0) [0|1] ""  C_ECU_GW
 SG_ IPMS3B2_5_2_JUDGE_IMPAIR_DRV : 42|1@1+ (1,0) [0|1] ""  C_ECU_GW
 SG_ IPMS3B2_2_0_STATUS_DIST_FAT_WARN : 16|1@1+ (1,0) [0|1] ""  C_ECU_GW
 SG_ IPMS3B2_1_0_MSG_COUNTER : 8|4@1+ (1,0) [0|15] ""  C_ECU,C_ECU_GW
 SG_ IPMS3B2_1_4_FAIL_IPMS : 12|1@1+ (1,0) [0|1] ""  C_ECU,C_ECU_GW
 SG_ IPMS3B2_0_0_CHECK_SUM : 0|8@1+ (1,0) [0|255] ""  C_ECU,C_ECU_GW

BO_ 1709 CCU6AD: 8 C_ECU_GW
 SG_ CCU6AD_7_0_DMS_SET_REQ : 56|1@1+ (1,0) [0|1] ""  IPMS
 SG_ CCU6AD_7_1_DP_POPUP_RES : 57|2@1+ (1,0) [0|3] "" Vector__XXX
 SG_ CCU6AD_6_3_EYE_MONI_BLUE_IND_SET : 51|1@1+ (1,0) [0|1] "" Vector__XXX
 SG_ CCU6AD_6_2_EYE_MONI_GRE_IND_SET : 50|1@1+ (1,0) [0|1] "" Vector__XXX
 SG_ CCU6AD_6_1_EYE_MONI_YEL_IND_SET : 49|1@1+ (1,0) [0|1] "" Vector__XXX
 SG_ CCU6AD_6_0_EYE_MONI_RED_IND_SET : 48|1@1+ (1,0) [0|1] "" Vector__XXX
 SG_ CCU6AD_5_0_DP_OPERATION_FLAG : 40|4@1+ (1,0) [0|15] ""  IPMS
 SG_ CCU6AD_5_4_DP_OPERATION_NO : 44|4@1+ (1,0) [0|15] ""  IPMS
 SG_ CCU6AD_4_7_DP_CCU_FAIL : 39|1@1+ (1,0) [0|1] "" Vector__XXX
 SG_ CCU6AD_4_3_ALERT_BUZZ_REQ : 35|3@1+ (1,0) [0|3] "" Vector__XXX
 SG_ CCU6AD_4_0_ALERT_VOL_LEVEL_SET : 32|3@1+ (1,0) [0|3] "" Vector__XXX
 SG_ CCU6AD_3_2_PREC_CAR_START_VOL : 26|3@1+ (1,0) [0|3] "" Vector__XXX
 SG_ CCU6AD_3_0_PREC_CAR_SIG_VOL_SET : 24|2@1+ (1,0) [0|2] "" Vector__XXX
 SG_ CCU6AD_2_3_MET_TEMP_UNIT_SET : 19|2@1+ (1,0) [0|2] "" Vector__XXX
 SG_ CCU6AD_2_0_UNIT_SET : 16|3@1+ (1,0) [0|6] "" Vector__XXX
 SG_ CCU6AD_1_0_MSG_COUNTER : 8|4@1+ (1,0) [0|15] "" Vector__XXX
 SG_ CCU6AD_1_4_DP_DKY_OPERATION_NO : 12|4@1+ (1,0) [0|15] "" Vector__XXX
 SG_ CCU6AD_0_0_CHECK_SUM : 0|8@1+ (1,0) [0|255] "" Vector__XXX

BO_ 1706 CCU6AA: 8 C_ECU_GW
 SG_ CCU6AA_5_0_WINDOW_LOCK_SET_REQ : 40|2@1+ (1,0) [0|1] "" Vector__XXX
 SG_ CCU6AA_5_2_DOOR_LINK_SET_REQ : 42|2@1+ (1,0) [0|1] "" Vector__XXX
 SG_ CCU6AA_5_4_BULK_TURN_ON_REQ : 44|2@1+ (1,0) [0|1] "" Vector__XXX
 SG_ CCU6AA_5_6_WIPER_SERV_MODE_REQ : 46|2@1+ (1,0) [0|3] "" Vector__XXX
 SG_ CCU6AA_4_0_ITMITT_SENSITIVE_REQ : 32|4@1+ (1,0) [0|21] "" Vector__XXX
 SG_ CCU6AA_4_4_REAR_WIPER_SET_REQ : 36|3@1+ (1,0) [0|3] "" Vector__XXX
 SG_ CCU6AA_4_7_SMT_CSTM_RESET_REQ : 39|1@1+ (1,0) [0|1] "" Vector__XXX
 SG_ CCU6AA_3_0_WELCOME_RIDEON_REQ : 24|3@1+ (1,0) [0|7] "" Vector__XXX
 SG_ CCU6AA_3_3_WELCOME_GETOFF_REQ : 27|3@1+ (1,0) [0|7] "" Vector__XXX
 SG_ CCU6AA_2_0_WIPER_HEADLAMP_REQ : 16|2@1+ (1,0) [0|3] "" Vector__XXX
 SG_ CCU6AA_1_0_MSG_COUNTER : 8|4@1+ (1,0) [0|15] "" Vector__XXX
 SG_ CCU6AA_1_4_WIUL_CUSTOM_REQ : 12|2@1+ (1,0) [0|2] "" Vector__XXX
 SG_ CCU6AA_1_6_WAL_CUSTOM_REQ : 14|2@1+ (1,0) [0|2] "" Vector__XXX
 SG_ CCU6AA_0_0_CHECK_SUM : 0|8@1+ (1,0) [0|255] "" Vector__XXX

BO_ 1704 CCU6A8: 8 C_ECU_GW
 SG_ CCU6A8_7_5_TRQ_CHG_MODE_SET : 61|2@1+ (1,0) [0|3] "" Vector__XXX
 SG_ CCU6A8_7_3_ADAPT_DEC_CHG_REQ : 59|2@1+ (1,0) [0|3] "" Vector__XXX
 SG_ CCU6A8_7_0_DEC_SELECT_REQ_B : 56|3@1+ (1,0) [0|3] "" Vector__XXX
 SG_ CCU6A8_6_5_DEC_SELECT_REQ_D : 53|3@1+ (1,0) [0|3] "" Vector__XXX
 SG_ CCU6A8_6_2_DEC_SELECT_REQ_ALL : 50|3@1+ (1,0) [0|3] "" Vector__XXX
 SG_ CCU6A8_6_0_DEC_SELECT_REQ_IND : 48|2@1+ (1,0) [0|3] "" Vector__XXX
 SG_ CCU6A8_5_2_TOWING_MODE_REQ : 42|2@1+ (1,0) [0|2] "" Vector__XXX
 SG_ CCU6A8_5_0_FACTORY_MODE_STATE : 40|2@1+ (1,0) [0|3] "" Vector__XXX
 SG_ CCU6A8_4_2_TRIP_RESET_REQ : 34|2@1+ (1,0) [0|1] "" Vector__XXX
 SG_ CCU6A8_4_0_TRIP_SWITCH_REQ : 32|2@1+ (1,0) [0|3] "" Vector__XXX
 SG_ CCU6A8_3_0_DOW_SFT_POS_SET : 24|2@1+ (1,0) [0|1] "" Vector__XXX
 SG_ CCU6A8_2_6_DOW_SET : 22|2@1+ (1,0) [0|1] "" Vector__XXX
 SG_ CCU6A8_2_4_RCTA_SET : 20|2@1+ (1,0) [0|1] "" Vector__XXX
 SG_ CCU6A8_2_2_BSD_LCA_2ND_SET : 18|2@1+ (1,0) [0|1] "" Vector__XXX
 SG_ CCU6A8_2_0_SRVD_SET : 16|2@1+ (1,0) [0|1] "" Vector__XXX
 SG_ CCU6A8_1_6_RCR_CSTM_RESET_REQ : 14|1@1+ (1,0) [0|1] "" Vector__XXX
 SG_ CCU6A8_1_4_BEV_CSTM_RESET_REQ : 12|1@1+ (1,0) [0|1] "" Vector__XXX
 SG_ CCU6A8_1_0_MSG_COUNTER : 8|4@1+ (1,0) [0|15] "" Vector__XXX
 SG_ CCU6A8_0_0_CHECK_SUM : 0|8@1+ (1,0) [0|255] "" Vector__XXX

BO_ 1149 CCU47D: 32 C_ECU_GW
 SG_ CCU47D_3_0_AA_EST_CHG_TIME : 24|32@1+ (1,0) [0|4294967294] "sec"  ENM,LCT
 SG_ CCU47D_2_0_E2E_COUNTER : 16|8@1+ (1,0) [0|255] ""  ADAS,ENM,LCT
 SG_ CCU47D_0_0_E2E_CRC : 0|16@1+ (1,0) [0|65535] ""  ADAS,ENM,LCT

BO_ 1148 CCU47C: 32 C_ECU_GW
 SG_ CCU47C_7_0_AA_CRG_MAX_OUT_WAT : 56|32@1+ (1,0) [0|4294967294] "watts"  ENM
 SG_ CCU47C_3_0_AA_DEP_MIN_BAT_LEVEL : 24|32@1+ (1,0) [0|4294967294] "wh"  ENM
 SG_ CCU47C_2_0_E2E_COUNTER : 16|8@1+ (1,0) [0|255] ""  ADAS,ENM,LCT
 SG_ CCU47C_0_0_E2E_CRC : 0|16@1+ (1,0) [0|65535] ""  ADAS,ENM,LCT

BO_ 1144 CCU478: 32 C_ECU_GW
 SG_ CCU478_25_0_LAT_CHG_WEEK_DAYS : 200|8@1+ (1,0) [0|255] "" Vector__XXX
 SG_ CCU478_24_3_Reserved : 195|5@1+ (1,0) [0|31] "" Vector__XXX
 SG_ CCU478_23_0_LAT_CHG_END_TIME : 184|11@1+ (1,0) [0|1439] "min" Vector__XXX
 SG_ CCU478_22_5_Reserved : 181|3@1+ (1,0) [0|7] "" Vector__XXX
 SG_ CCU478_21_2_LAT_CHG_START_TIME : 170|11@1+ (1,0) [0|1439] "min" Vector__XXX
 SG_ CCU478_21_0_LAT_CHG_SET_TYPE : 168|2@1+ (1,0) [0|3] "" Vector__XXX
 SG_ CCU478_20_6_Reserved : 166|2@1+ (1,0) [0|3] "" Vector__XXX
 SG_ CCU478_20_2_TIRE_SIZE : 162|4@1+ (1,0) [0|7] "" Vector__XXX
 SG_ CCU478_20_0_TIRE_TYPE : 160|2@1+ (1,0) [0|3] "" Vector__XXX
 SG_ CCU478_19_4_Reserved : 156|2@1+ (1,0) [0|3] "" Vector__XXX
 SG_ CCU478_19_2_SW_PFO_MOD_CHG : 154|2@1+ (1,0) [0|2] "" Vector__XXX
 SG_ CCU478_19_0_DEP_TIM_CHG_FLG : 152|1@1+ (1,0) [0|3] "" Vector__XXX
 SG_ CCU478_18_0_DEP_TIM4_WEEK_DAYS : 144|8@1+ (1,0) [0|255] "" Vector__XXX
 SG_ CCU478_17_3_Reserved : 139|5@1+ (1,0) [0|31] "" Vector__XXX
 SG_ CCU478_16_0_DEP_TIM4_START_TIME : 128|11@1+ (1,0) [0|1439] "min" Vector__XXX
 SG_ CCU478_15_7_DEP_TIM4_PER_FLG : 127|1@1+ (1,0) [0|1] "" Vector__XXX
 SG_ CCU478_15_5_DEP_TIM4_SW_STS : 125|2@1+ (1,0) [0|3] "" Vector__XXX
 SG_ CCU478_15_0_TIM4_DISP_ID : 120|5@1+ (1,0) [0|31] "" Vector__XXX
 SG_ CCU478_14_0_DEP_TIM3_WEEK_DAYS : 112|8@1+ (1,0) [0|255] "" Vector__XXX
 SG_ CCU478_13_3_Reserved : 107|5@1+ (1,0) [0|31] "" Vector__XXX
 SG_ CCU478_12_0_DEP_TIM3_START_TIME : 96|11@1+ (1,0) [0|1439] "min" Vector__XXX
 SG_ CCU478_11_7_DEP_TIM3_PER_FLG : 95|1@1+ (1,0) [0|1] "" Vector__XXX
 SG_ CCU478_11_5_DEP_TIM3_SW_STS : 93|2@1+ (1,0) [0|3] "" Vector__XXX
 SG_ CCU478_11_0_TIM3_DISP_ID : 88|5@1+ (1,0) [0|31] "" Vector__XXX
 SG_ CCU478_10_0_DEP_TIM2_WEEK_DAYS : 80|8@1+ (1,0) [0|255] "" Vector__XXX
 SG_ CCU478_9_3_Reserved : 75|5@1+ (1,0) [0|31] "" Vector__XXX
 SG_ CCU478_8_0_DEP_TIM2_START_TIME : 64|11@1+ (1,0) [0|1439] "min" Vector__XXX
 SG_ CCU478_7_7_DEP_TIM2_PER_FLG : 63|1@1+ (1,0) [0|1] "" Vector__XXX
 SG_ CCU478_7_5_DEP_TIM2_SW_STS : 61|2@1+ (1,0) [0|3] "" Vector__XXX
 SG_ CCU478_7_0_TIM2_DISP_ID : 56|5@1+ (1,0) [0|31] "" Vector__XXX
 SG_ CCU478_6_0_DEP_TIM1_WEEK_DAYS : 48|8@1+ (1,0) [0|255] "" Vector__XXX
 SG_ CCU478_5_3_Reserved : 43|5@1+ (1,0) [0|31] "" Vector__XXX
 SG_ CCU478_4_0_DEP_TIM1_START_TIME : 32|11@1+ (1,0) [0|1439] "min" Vector__XXX
 SG_ CCU478_3_7_DEP_TIM1_PER_FLG : 31|1@1+ (1,0) [0|1] "" Vector__XXX
 SG_ CCU478_3_5_DEP_TIM1_SW_STS : 29|2@1+ (1,0) [0|3] "" Vector__XXX
 SG_ CCU478_3_0_TIM1_DISP_ID : 24|5@1+ (1,0) [0|31] "" Vector__XXX
 SG_ CCU478_2_0_E2E_COUNTER : 16|8@1+ (1,0) [0|255] "" Vector__XXX
 SG_ CCU478_0_0_E2E_CRC : 0|16@1+ (1,0) [0|65535] "" Vector__XXX

BO_ 927 AVN39F: 8 C_ECU_GW

BO_ 1105 CCU451: 32 C_ECU_GW
 SG_ CCU451_31_0_BYTE26 : 248|8@1+ (1,0) [0|255] "" Vector__XXX
 SG_ CCU451_30_0_BYTE25 : 240|8@1+ (1,0) [0|255] "" Vector__XXX
 SG_ CCU451_29_0_BYTE24 : 232|8@1+ (1,0) [0|255] "" Vector__XXX
 SG_ CCU451_28_0_BYTE23 : 224|8@1+ (1,0) [0|255] "" Vector__XXX
 SG_ CCU451_27_0_BYTE22 : 216|8@1+ (1,0) [0|255] "" Vector__XXX
 SG_ CCU451_26_0_BYTE21 : 208|8@1+ (1,0) [0|255] "" Vector__XXX
 SG_ CCU451_25_0_BYTE20 : 200|8@1+ (1,0) [0|255] "" Vector__XXX
 SG_ CCU451_24_0_BYTE19 : 192|8@1+ (1,0) [0|255] "" Vector__XXX
 SG_ CCU451_23_0_BYTE18 : 184|8@1+ (1,0) [0|255] "" Vector__XXX
 SG_ CCU451_22_0_BYTE17 : 176|8@1+ (1,0) [0|255] "" Vector__XXX
 SG_ CCU451_21_0_BYTE16 : 168|8@1+ (1,0) [0|255] "" Vector__XXX
 SG_ CCU451_20_0_BYTE15 : 160|8@1+ (1,0) [0|255] "" Vector__XXX
 SG_ CCU451_19_0_BYTE14 : 152|8@1+ (1,0) [0|255] "" Vector__XXX
 SG_ CCU451_18_0_BYTE13 : 144|8@1+ (1,0) [0|255] "" Vector__XXX
 SG_ CCU451_17_0_BYTE12 : 136|8@1+ (1,0) [0|255] "" Vector__XXX
 SG_ CCU451_16_0_BYTE11 : 128|8@1+ (1,0) [0|255] "" Vector__XXX
 SG_ CCU451_15_0_BYTE10 : 120|8@1+ (1,0) [0|255] "" Vector__XXX
 SG_ CCU451_14_0_BYTE9 : 112|8@1+ (1,0) [0|255] "" Vector__XXX
 SG_ CCU451_13_0_BYTE8 : 104|8@1+ (1,0) [0|255] "" Vector__XXX
 SG_ CCU451_12_0_BYTE7 : 96|8@1+ (1,0) [0|255] "" Vector__XXX
 SG_ CCU451_11_0_BYTE6 : 88|8@1+ (1,0) [0|255] "" Vector__XXX
 SG_ CCU451_10_0_BYTE5 : 80|8@1+ (1,0) [0|255] "" Vector__XXX
 SG_ CCU451_9_0_BYTE4 : 72|8@1+ (1,0) [0|255] "" Vector__XXX
 SG_ CCU451_8_0_CHG_BTN_FLG_CCU : 64|3@1+ (1,0) [0|4] "" Vector__XXX
 SG_ CCU451_8_3_CHG_CNG_FLG_CCU : 67|1@1+ (1,0) [0|1] "" Vector__XXX
 SG_ CCU451_8_4_Reserved : 68|4@1+ (1,0) [0|15] "" Vector__XXX
 SG_ CCU451_7_3_Reserved : 59|5@1+ (1,0) [0|31] "" Vector__XXX
 SG_ CCU451_6_0_CHG_COMTI : 48|11@1+ (1,0) [0|1439] "" Vector__XXX
 SG_ CCU451_5_0_SW_RIGHT_NOW_PRE_CON : 40|2@1+ (1,0) [0|4] ""  ENM
 SG_ CCU451_5_2_Reserved : 42|6@1+ (1,0) [0|63] "" Vector__XXX
 SG_ CCU451_4_1_CHG_HILMT_REQ : 33|7@1+ (1,0) [50|100] "%" Vector__XXX
 SG_ CCU451_4_0_CHG_STP_REQ : 32|1@1+ (1,0) [0|1] "" Vector__XXX
 SG_ CCU451_3_4_DCCHG_PWRUPLMT : 28|4@1+ (1,0) [0|15] "" Vector__XXX
 SG_ CCU451_3_0_ACCHG_CORUPLMT : 24|4@1+ (1,0) [0|15] "" Vector__XXX
 SG_ CCU451_2_0_E2E_COUNTER : 16|8@1+ (1,0) [0|255] ""  ENM
 SG_ CCU451_0_0_E2E_CRC : 0|16@1+ (1,0) [0|65535] ""  ENM

BO_ 1726 CCU6BE: 32 C_ECU_GW
 SG_ CCU6BE_10_0_CCU_BOOT_STATE : 80|3@1+ (1,0) [0|7] "" Vector__XXX
 SG_ CCU6BE_9_0_DISP_DRAINAGE : 72|4@1+ (1,0) [0|5] ""  THM
 SG_ CCU6BE_8_0_DISP_POURING_WATER : 64|4@1+ (1,0) [0|13] ""  THM
 SG_ CCU6BE_7_4_QDK_DEV : 60|4@1+ (1,0) [0|15] "" Vector__XXX
 SG_ CCU6BE_5_0_SLOTID_ERASE : 40|16@1+ (1,0) [0|65535] "" Vector__XXX
 SG_ CCU6BE_4_2_QDK_OSWAP : 34|2@1+ (1,0) [0|2] "" Vector__XXX
 SG_ CCU6BE_4_4_QDK_FDRQ : 36|2@1+ (1,0) [0|2] "" Vector__XXX
 SG_ CCU6BE_4_6_QDK_OWCQ : 38|2@1+ (1,0) [0|2] "" Vector__XXX
 SG_ CCU6BE_3_0_QDK_ORRQ : 24|2@1+ (1,0) [0|2] "" Vector__XXX
 SG_ CCU6BE_3_2_QDK_OGRQ : 26|2@1+ (1,0) [0|2] "" Vector__XXX
 SG_ CCU6BE_3_4_QDK_ODRQ : 28|2@1+ (1,0) [0|2] "" Vector__XXX
 SG_ CCU6BE_3_6_QDK_ADLQ : 30|2@1+ (1,0) [0|2] "" Vector__XXX
 SG_ CCU6BE_2_0_E2E_COUNTER : 16|8@1+ (1,0) [0|255] ""  THM
 SG_ CCU6BE_0_0_CRC : 0|16@1+ (1,0) [0|65535] ""  THM

BO_ 1312 IAVAS520: 8 IAVAS
 SG_ IAVAS520_1_4_ActiveWakeUpBit : 12|1@1+ (1,0) [0|1] ""  BEV,IPMS,BST,VDC,C_ECU
 SG_ IAVAS520_0_0_SourceNodeID : 0|8@1+ (1,0) [0|255] ""  BEV,IPMS,BST,VDC,C_ECU

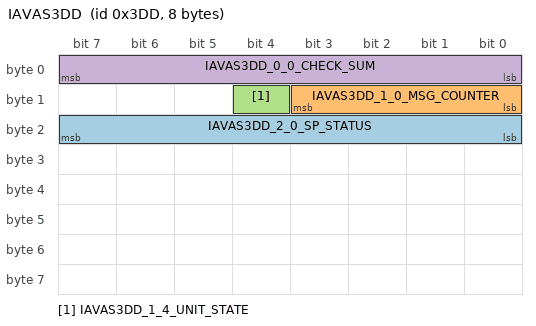
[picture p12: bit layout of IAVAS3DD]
BO_ 989 IAVAS3DD: 8 IAVAS
 SG_ IAVAS3DD_2_0_SP_STATUS : 16|8@1+ (1,0) [0|4] ""  C_ECU_GW
 SG_ IAVAS3DD_1_0_MSG_COUNTER : 8|4@1+ (1,0) [0|15] ""  C_ECU_GW
 SG_ IAVAS3DD_1_4_UNIT_STATE : 12|1@1+ (1,0) [0|1] ""  C_ECU_GW
 SG_ IAVAS3DD_0_0_CHECK_SUM : 0|8@1+ (1,0) [0|255] ""  C_ECU_GW

CM_ SG_ 1654 ACN676_3_0_HVH_MAX_PW "高電圧水加熱ヒータ 電力上限指示
";
CM_ SG_ 1654 ACN676_2_0_TGT_FANDUTY "目標電動FAN DUTY(空調)
";
CM_ SG_ 1654 ACN676_1_5_REQ_HVH_STB "高電圧水加熱ヒータ STB ON要求
";
CM_ SG_ 1654 ACN676_1_4_REQ_HVH_ON "高電圧水加熱ヒータ ON要求
";
CM_ SG_ 1654 ACN676_1_0_MSG_COUNTER "メッセージカウンタ
";
CM_ SG_ 1654 ACN676_0_0_CHECK_SUM "チェックサム
";
CM_ SG_ 1652 ACN674_7_0_STATE_AC_CONT "A/C制御状態通知
";
CM_ SG_ 1652 ACN674_6_6_REQ_OBD_WARNING "BEVOBD警告灯点灯要求(A/C)
";
CM_ SG_ 1652 ACN674_6_1_REQ_CAUTION_AC "A/C故障による文言表示要求
";
CM_ SG_ 1652 ACN674_6_0_REQ_COMP_STB "インバータSTB ON/OFF要求
(電動コンプレッサ駆動準備信号)
";
CM_ SG_ 1652 ACN674_5_0_ACPRE_AD "冷媒圧力センサデータA/D値
";
CM_ SG_ 1652 ACN674_4_0_COMD_ACCE_ECOMP "電動コンプレッサ指令加速度
";
CM_ SG_ 1652 ACN674_2_0_TGT_ECOMP_R "電動コンプレッサ目標回転数
";
CM_ SG_ 1652 ACN674_1_5_JUDGE_SLOWSTART "スロースタート可否信号
";
CM_ SG_ 1652 ACN674_1_4_JUDGE_COMPWAKE "起動制限可否信号
";
CM_ SG_ 1652 ACN674_1_0_MSG_COUNTER "メッセージカウンタ
";
CM_ SG_ 1652 ACN674_0_0_CHECK_SUM "チェックサム
";
CM_ SG_ 948 ACN3B4_2_0_AMB_AC "外気温(A/C)
";
CM_ SG_ 948 ACN3B4_1_0_MSG_COUNTER "ﾒｯｾｰｼﾞｶｳﾝﾀ
";
CM_ SG_ 948 ACN3B4_0_0_CHECK_SUM "ﾁｪｯｸｻﾑ
";
CM_ SG_ 1725 AVN6BD_7_1_EYE_SAFETY_MODE_CSTM "障害物なし加速抑制カスタマイズ
";
CM_ SG_ 1725 AVN6BD_7_2_EYE_BRAKE_HAPTIC_CSTM "ブレーキハプティックカスタマイズ
";
CM_ SG_ 1725 AVN6BD_7_4_LDW_SW_PUSH_STATE "LDW音OFFハードSW押下状態
";
CM_ SG_ 1725 AVN6BD_7_5_LDW_SW_FAIL_STATE "LDW音OFFハードSW異常状態
";
CM_ SG_ 1725 AVN6BD_7_6_FCW_SW_PUSH_STATE "FCW音OFFハードSW押下状態
";
CM_ SG_ 1725 AVN6BD_7_7_FCW_SW_FAIL_STATE "FCW音OFFハードSW異常状態
";
CM_ SG_ 1725 AVN6BD_6_0_REQ_CHG_CSTM_EYE "アイサイトカスタマイズ要求変更
";
CM_ SG_ 1725 AVN6BD_6_1_REQ_RESET_CSTM_EYE "アイサイトカスタマイズリセット要求
";
CM_ SG_ 1725 AVN6BD_6_3_CSTM_LANE_CONT "アイサイトカスタマイズ変更設定(通行車線)
";
CM_ SG_ 1725 AVN6BD_6_4_CSTM_MIS_AT_BACK "アイサイトカスタマイズ変更設定(AT誤後進抑制制御)
";
CM_ SG_ 1725 AVN6BD_6_6_CSTM_ACC_CONT "アイサイトカスタマイズ変更設定(ACC加速特性)
";
CM_ SG_ 1725 AVN6BD_1_0_MSG_COUNTER "ﾒｯｾｰｼﾞｶｳﾝﾀ
";
CM_ SG_ 1725 AVN6BD_0_0_CHECK_SUM "ﾁｪｯｸｻﾑ
";
CM_ SG_ 1724 AVN6BC_6_0_LAT_MINUTE "緯度_分
";
CM_ SG_ 1724 AVN6BC_6_6_LAT_SECOND "緯度_秒
";
CM_ SG_ 1724 AVN6BC_5_0_LAT_N_S "緯度_南北
";
CM_ SG_ 1724 AVN6BC_5_1_LAT_DEGREE "緯度_度
";
CM_ SG_ 1724 AVN6BC_3_0_LON_MINUTE "経度_分
";
CM_ SG_ 1724 AVN6BC_3_6_LON_SECOND "経度_秒
";
CM_ SG_ 1724 AVN6BC_2_0_LON_DEGREE "経度_度
";
CM_ SG_ 1724 AVN6BC_1_0_MSG_COUNTER "ﾒｯｾｰｼﾞｶｳﾝﾀ
";
CM_ SG_ 1724 AVN6BC_1_4_GNSS_STATUS "GNSS測位状態
";
CM_ SG_ 1724 AVN6BC_1_7_LON_E_W "経度_東西
";
CM_ SG_ 1724 AVN6BC_0_0_CHECK_SUM "ﾁｪｯｸｻﾑ
";
CM_ SG_ 1723 AVN6BB_7_0_ISA_IACC_OFFSET_CSTM "ISA制限車速・iACCセット車速オフセット値
";
CM_ SG_ 1723 AVN6BB_7_5_EYE_TOLLBOOTH_DECEL "料金所減速ｶｽﾀﾏｲｽﾞ(高度運転支援)
";
CM_ SG_ 1723 AVN6BB_7_6_EYE_CURVE_DECEL_CSTM "カーブ減速ｶｽﾀﾏｲｽﾞ（高度運転支援）
";
CM_ SG_ 1723 AVN6BB_7_7_EYE_GREEN_LIGHT_CSTM "青信号切り替わりお知らせ設定
";
CM_ SG_ 1723 AVN6BB_6_0_CCU_FAIL "CCU/CIDﾌｪｰﾙﾌﾗｸﾞ
";
CM_ SG_ 1723 AVN6BB_6_1_EYE_P_CR_CSTM "P-CR ON/OFF設定
";
CM_ SG_ 1723 AVN6BB_6_2_EYE_ALK_B_LDW_CSTM "車線逸脱防止+車線逸脱警報 ON/OFF設定
";
CM_ SG_ 1723 AVN6BB_6_4_EYE_CSTM_REQ "EyeSightｶｽﾀﾏｲｽﾞ変更要求
";
CM_ SG_ 1723 AVN6BB_6_5_EYE_ELK_CSTM "ELK ON/OFF設定
";
CM_ SG_ 1723 AVN6BB_6_6_EYE_ALKB_EDGE_CSTM "ﾛｰﾄﾞｴｯｼﾞALKBｶｽﾀﾏｲｽﾞ（ALKの制御種別）
";
CM_ SG_ 1723 AVN6BB_6_7_FCW_ON_OFF "FCW機能 ON/OFF設定
";
CM_ SG_ 1723 AVN6BB_5_0_DMS_SELECT_ID "DMS選択ID
";
CM_ SG_ 1723 AVN6BB_5_4_TPMS_TH_MODE_CSTM "TPMS閾値ﾓｰﾄﾞｶｽﾀﾏｲｽﾞ
";
CM_ SG_ 1723 AVN6BB_5_6_DMS_SET_REQ "DMS設定変更要求ﾌﾗｸﾞ
";
CM_ SG_ 1723 AVN6BB_5_7_DMS_RECOG_SET "DMS個人認識ON/OFF設定
";
CM_ SG_ 1723 AVN6BB_4_0_DMS_EDIT_REQ "DMS操作中ﾌﾗｸﾞ
";
CM_ SG_ 1723 AVN6BB_4_4_VEHICLE_DEMO "車両連携デモモード（DMSなど）
";
CM_ SG_ 1723 AVN6BB_4_5_SRVD_CSTM_REQ "SRVDｶｽﾀﾏｲｽﾞ変更要求
";
CM_ SG_ 1723 AVN6BB_4_6_SEAT_RESET_REQ "ｼｰﾄｶｽﾀﾏｲｽﾞﾘｾｯﾄ要求
";
CM_ SG_ 1723 AVN6BB_4_7_SEATAWAY_SET_CSTM "ｼｰﾄ後退設定変更要求
";
CM_ SG_ 1723 AVN6BB_3_0_SRVD_ON_OFF "SRVD ON/OFF SW情報
";
CM_ SG_ 1723 AVN6BB_3_1_PRG_RESET_REQ "PRGｶｽﾀﾏｲｽﾞﾘｾｯﾄ要求
";
CM_ SG_ 1723 AVN6BB_3_2_PRG_MEM_CSTM "PRGﾒﾓﾘ設定変更要求
";
CM_ SG_ 1723 AVN6BB_3_3_DMS_ON_OFF "DMS ON/OFF SW情報
";
CM_ SG_ 1723 AVN6BB_3_4_MIR_RESET_REQ "ﾄﾞｱﾐﾗｰｶｽﾀﾏｲｽﾞﾘｾｯﾄ要求
";
CM_ SG_ 1723 AVN6BB_3_5_MIR_AFOLD_CSTM "ｵｰﾄ電動格納ﾄﾞｱﾐﾗｰ設定変更要求
";
CM_ SG_ 1723 AVN6BB_3_6_MIR_RTILT_CSTM "ﾘﾊﾞｰｽ連動ﾄﾞｱﾐﾗｰ設定変更要求
";
CM_ SG_ 1723 AVN6BB_3_7_EYE_TSA_CSTM "標識認識連動TSA（ISA/iACC） ON/OFF設定
";
CM_ SG_ 1723 AVN6BB_2_0_AVH_ON_OFF "AVH ON/OFF SW情報
";
CM_ SG_ 1723 AVN6BB_2_2_VDC_ON_OFF "VDC ON/OFF 情報
";
CM_ SG_ 1723 AVN6BB_2_4_CCU_HALT_RESET "CCUリセット・一時停止フラグ
";
CM_ SG_ 1723 AVN6BB_2_5_EYE_LDW_TIMING_CSTM "LDWタイミングユーザ設定値
";
CM_ SG_ 1723 AVN6BB_2_6_FCW_CSTM "FCWカスタマイズ設定
";
CM_ SG_ 1723 AVN6BB_1_0_MSG_COUNTER "ﾒｯｾｰｼﾞｶｳﾝﾀ
";
CM_ SG_ 1723 AVN6BB_1_4_EYE_WARN_CSTM "ｽﾃｱ振動ｶｽﾀﾏｲｽﾞ
";
CM_ SG_ 1723 AVN6BB_1_5_EYE_FCTI_CSTM "FCTI(交差車両接近通知)
";
CM_ SG_ 1723 AVN6BB_1_7_LDW_WARNING_ON_OFF "LDW音 ON/OFF設定
";
CM_ SG_ 1723 AVN6BB_0_0_CHECK_SUM "ﾁｪｯｸｻﾑ
";
CM_ SG_ 1713 AVN6B1_7_1_PRESENT_YEAR "現在年月日(年)
";
CM_ SG_ 1713 AVN6B1_6_0_PRESENT_DAY "現在年月日（日）
";
CM_ SG_ 1713 AVN6B1_6_5_PRESENT_MONTH "現在年月日(月)
";
CM_ SG_ 1713 AVN6B1_5_0_FAIL_AVN "AVNﾌｪｰﾙ情報
";
CM_ SG_ 1713 AVN6B1_5_1_IN_OPERATION "操作中ﾌﾗｸﾞ
";
CM_ SG_ 1713 AVN6B1_5_2_TYPE_NAVI "ﾅﾋﾞ有無ﾌﾗｸﾞ
";
CM_ SG_ 1713 AVN6B1_5_4_XM_ENABLE "XM有無ﾌﾗｸﾞ
";
CM_ SG_ 1713 AVN6B1_5_6_FLG_ABLE_WELCOME_SCL "ｳｪﾙｶﾑ画面表示可能ﾌﾗｸﾞ
";
CM_ SG_ 1713 AVN6B1_5_7_STEER_ANGLE_INTERLOCK "Rカメラガイド線舵角連動設定(ON/OFF)（H/Unit）
";
CM_ SG_ 1713 AVN6B1_4_0_PRESENT_TIME_SEC "現在時刻(秒)
";
CM_ SG_ 1713 AVN6B1_4_7_BACK_CAMERA_DELAY "Rカメラ9秒Delay表示設定(ON/OFF)（H/Unit）
";
CM_ SG_ 1713 AVN6B1_3_0_PRESENT_TIME_MIN "現在時刻(分)
";
CM_ SG_ 1713 AVN6B1_3_7_MVS_FTSNR_INTERRUPT "ｸﾘｿﾅ自動前方視界支援設定
";
CM_ SG_ 1713 AVN6B1_2_0_GPS_CLOCK_FLG "時刻補正有効ﾌﾗｸﾞ
";
CM_ SG_ 1713 AVN6B1_2_1_PRESENT_TIME_HOUR "現在時刻(時)
";
CM_ SG_ 1713 AVN6B1_2_6_TIME_FORMAT "タイムフォーマット切替(12h/24h)
";
CM_ SG_ 1713 AVN6B1_1_0_MSG_COUNTER "ﾒｯｾｰｼﾞｶｳﾝﾀ
";
CM_ SG_ 1713 AVN6B1_1_4_WAKE_UP_FRAME "ｳｪｲｸｱｯﾌﾟﾌﾚｰﾑ識別ﾌﾗｸﾞ
";
CM_ SG_ 1713 AVN6B1_1_5_REQ_COMM_CONT "通信継続要求ﾌﾗｸﾞ
";
CM_ SG_ 1713 AVN6B1_1_6_ACTIVE_AVN_CSTM "車両ｶｽﾀﾏｲｽﾞ実施状態ﾌﾗｸﾞ（H/Unit）
";
CM_ SG_ 1713 AVN6B1_1_7_REQ_STOP_CAMERA_OUT "カメラ映像出力停止要求フラグ（H/Unit）
";
CM_ SG_ 1713 AVN6B1_0_0_CHECK_SUM "ﾁｪｯｸｻﾑ
";
CM_ SG_ 1019 AVN3FB_7_0_SMT_TIM_RESET_REQ "自動ｴﾝｼﾞﾝ停止ﾀｲﾏﾘｾｯﾄ要求
";
CM_ SG_ 1019 AVN3FB_7_1_SMT_EG_CSTM_REQ "自動ｴﾝｼﾞﾝ停止カスタマイズ変更要求
";
CM_ SG_ 1019 AVN3FB_7_2_EYE_YEILD_CSTM "特殊標識表示ON/OFF設定（前方優先道路）
";
CM_ SG_ 1019 AVN3FB_7_3_EYE_STOP_CSTM "特殊標識表示ON/OFF設定（一時停止）
";
CM_ SG_ 1019 AVN3FB_7_4_EYE_NO_ENTRY_CSTM "特殊標識表示ON/OFF設定（進入禁止）
";
CM_ SG_ 1019 AVN3FB_7_5_MVS_CAMERA_SELECT_SW "MVSｶﾒﾗ切替画面内ｽｲｯﾁ情報
";
CM_ SG_ 1019 AVN3FB_7_7_ACPANEL_DR_ONLY "ｴｱｺﾝﾊﾟﾈﾙ 一席集中 SW
";
CM_ SG_ 1019 AVN3FB_6_0_ACPANEL_PA_TEMP "ｴｱｺﾝﾊﾟﾈﾙ Ｐ席TEMP
";
CM_ SG_ 1019 AVN3FB_6_6_ACPANEL_MODE_DOWN "ｴｱｺﾝﾊﾟﾈﾙ 吹き出し口MODE- SW
";
CM_ SG_ 1019 AVN3FB_6_7_ACPANEL_MODE_UP "ｴｱｺﾝﾊﾟﾈﾙ 吹き出し口MODE+ SW
";
CM_ SG_ 1019 AVN3FB_5_0_ACPANEL_DR_TEMP "ｴｱｺﾝﾊﾟﾈﾙ D席TEMP
";
CM_ SG_ 1019 AVN3FB_5_6_ACPANEL_FAN_DOWN "ｴｱｺﾝﾊﾟﾈﾙ FAN DOWN SW
";
CM_ SG_ 1019 AVN3FB_5_7_ACPANEL_FAN_UP "ｴｱｺﾝﾊﾟﾈﾙ FAN UP SW
";
CM_ SG_ 1019 AVN3FB_4_0_ACPANEL_FAN_LEVEL "ｴｱｺﾝﾊﾟﾈﾙ FAN段数
";
CM_ SG_ 1019 AVN3FB_4_4_ACPANEL_MODE_VENT "ｴｱｺﾝﾊﾟﾈﾙ 吹き出し口MODE指定
";
CM_ SG_ 1019 AVN3FB_3_0_ACPANEL_PA_TEMP_DOWN "ｴｱｺﾝﾊﾟﾈﾙ P席TEMP設定DOWN SW
";
CM_ SG_ 1019 AVN3FB_3_1_ACPANEL_PA_TEMP_UP "ｴｱｺﾝﾊﾟﾈﾙ P席TEMP設定UP SW
";
CM_ SG_ 1019 AVN3FB_3_2_ACPANEL_DR_TEMP_DOWN "ｴｱｺﾝﾊﾟﾈﾙ D席TEMP設定DOWN SW
";
CM_ SG_ 1019 AVN3FB_3_3_ACPANEL_DR_TEMP_UP "ｴｱｺﾝﾊﾟﾈﾙ D席TEMP設定UP SW
";
CM_ SG_ 1019 AVN3FB_3_4_ACPANEL_SYNC "ｴｱｺﾝﾊﾟﾈﾙ SYNC SW
";
CM_ SG_ 1019 AVN3FB_3_5_ACPANEL_AC "ｴｱｺﾝﾊﾟﾈﾙ A/C SW
";
CM_ SG_ 1019 AVN3FB_3_6_F_DEF_SW "Front DEF SW
";
CM_ SG_ 1019 AVN3FB_3_7_R_DEF_SW "Rear DEF SW
";
CM_ SG_ 1019 AVN3FB_2_0_ACPANEL_AUTO "ｴｱｺﾝﾊﾟﾈﾙ AUTO SW
";
CM_ SG_ 1019 AVN3FB_2_1_ACPANEL_MAX_AC "ｴｱｺﾝﾊﾟﾈﾙ MAX A/C SW
";
CM_ SG_ 1019 AVN3FB_2_2_ACPANEL_SEAT_C_P "ｴｱｺﾝﾊﾟﾈﾙ ﾍﾞﾝﾁﾚｰｼｮﾝｼｰﾄ P席 SW
";
CM_ SG_ 1019 AVN3FB_2_3_ACPANEL_SEAT_C_D "ｴｱｺﾝﾊﾟﾈﾙ ﾍﾞﾝﾁﾚｰｼｮﾝｼｰﾄ D席 SW
";
CM_ SG_ 1019 AVN3FB_2_4_ACPANEL_SEAT_H_P "ｴｱｺﾝﾊﾟﾈﾙ SEAT HEATER P席 SW
";
CM_ SG_ 1019 AVN3FB_2_5_ACPANEL_SEAT_H_D "ｴｱｺﾝﾊﾟﾈﾙ SEAT HEATER D席 SW
";
CM_ SG_ 1019 AVN3FB_2_6_ACPANEL_INNER_AIR "ｴｱｺﾝﾊﾟﾈﾙ 内外気 SW
";
CM_ SG_ 1019 AVN3FB_2_7_ACPANEL_AC_ON_OFF "ｴｱｺﾝﾊﾟﾈﾙ 空調ON/OFF
";
CM_ SG_ 1019 AVN3FB_1_0_MSG_COUNTER "ﾒｯｾｰｼﾞｶｳﾝﾀ
";
CM_ SG_ 1019 AVN3FB_1_4_EYE_CSTM_REQ_3FB "EyeSightｶｽﾀﾏｲｽﾞ変更要求_3FB
";
CM_ SG_ 1019 AVN3FB_1_5_DDAW_WARNING_CSTM "DDAW ON/OFF設定
";
CM_ SG_ 1019 AVN3FB_1_6_SIGN_SWITCH_SND "標識切り替わり音 ON/OFF設定
";
CM_ SG_ 1019 AVN3FB_1_7_SLWF_CSTM "SLWF ON/OFF設定
";
CM_ SG_ 1019 AVN3FB_0_0_CHECK_SUM "ﾁｪｯｸｻﾑ
";
CM_ SG_ 818 PMN332_7_0_RES_CONTROL_STATUS "リモスタ制御状態
";
CM_ SG_ 818 PMN332_7_2_REQ_RES_P_LOCK "ﾘﾓｽﾀ制御ｼﾌﾄPﾛｯｸ要求
";
CM_ SG_ 818 PMN332_7_5_IGB_RELAY_REQ "IGbリレー指示値
";
CM_ SG_ 818 PMN332_7_6_IGA_RELAY_REQ "IGaリレー指示値
";
CM_ SG_ 818 PMN332_7_7_REQ_STOP_RES "ﾘﾓｽﾀ停止要求
";
CM_ SG_ 818 PMN332_6_0_RES_IDLE_TIME "ﾘﾓｽﾀ累積ｴﾝｼﾞﾝON時間
";
CM_ SG_ 818 PMN332_6_7_CUST "自動E/G停止カスタマイズ設定値
";
CM_ SG_ 818 PMN332_5_0_PUSHSTART_SW "ﾌﾟｯｼｭｽﾀｰﾄSW信号
";
CM_ SG_ 818 PMN332_5_1_SIG_KEY_PUSHSTART "ﾌﾟｯｼｭｽﾀｰﾄ用ｷｰ信号
";
CM_ SG_ 818 PMN332_5_2_STATE_MODE_POWER "電源ﾓｰﾄﾞ状態信号
";
CM_ SG_ 818 PMN332_5_4_BUZ_2SHOT_IN "室内ﾌﾞｻﾞｰ　単発2回吹鳴要求
";
CM_ SG_ 818 PMN332_5_5_BUZ_INTERMIT1_IN "室内ﾌﾞｻﾞｰ　断続吹鳴1要求
";
CM_ SG_ 818 PMN332_5_6_BUZ_INTERMIT2_IN "室内ﾌﾞｻﾞｰ　断続吹鳴2要求(0.7s周期)
";
CM_ SG_ 818 PMN332_5_7_BUZ_CONTINUE_IN "室内ﾌﾞｻﾞｰ　連続吹鳴要求
";
CM_ SG_ 818 PMN332_2_0_WARN_SSP_SIG1 "ｽﾏｰﾄｼｽﾃﾑ警報信号(電源)1
";
CM_ SG_ 818 PMN332_2_1_WARN_SSP_SIG2 "ｽﾏｰﾄｼｽﾃﾑ警報信号(電源)2
";
CM_ SG_ 818 PMN332_2_4_SMT_PWR_SIG "ｽﾏｰﾄｼｽﾃﾑ電源状態信号
";
CM_ SG_ 818 PMN332_2_7_BUZ_1SHOT_IN "室内ﾌﾞｻﾞｰ　単発1回吹鳴
";
CM_ SG_ 818 PMN332_1_0_MSG_COUNTER "ﾒｯｾｰｼﾞｶｳﾝﾀ
";
CM_ SG_ 818 PMN332_0_0_CHECK_SUM "ﾁｪｯｸｻﾑ
";
CM_ SG_ 1622 BIU656_6_0_KICK_OPEN_REQ_PRG "ｷｯｸ要因PRGｵｰﾌﾟﾝ要求
";
CM_ SG_ 1622 BIU656_6_1_KICK_CLOSE_REQ_PRG "ｷｯｸ要因PRGｸﾛｰｽﾞ要求
";
CM_ SG_ 1622 BIU656_6_6_CARGO_LAMP_OUT "カーゴランプ出力情報
";
CM_ SG_ 1622 BIU656_6_7_PERMITT_KEY_RG_UNL "キーレス R/G SW RG解錠許可状態
";
CM_ SG_ 1622 BIU656_5_0_PRG_DRVR_OPENERSW "PRGD席ｵｰﾌﾟﾅSW
";
CM_ SG_ 1622 BIU656_5_1_HF_PRG_OFF_SW "ﾊﾝｽﾞﾌﾘｰPRG OFF SW
";
CM_ SG_ 1622 BIU656_5_2_PERMIT_OPEN_RG "R/Gｵｰﾌﾟﾝ許可状態
";
CM_ SG_ 1622 BIU656_5_3_BUZ_ON_OFF "ﾌﾞｻﾞｰ吹鳴ON/OFF
";
CM_ SG_ 1622 BIU656_5_4_PRG_DRVR_SW_PERMIT "PRG D席ｵｰﾌﾟﾅｰSW許可状態
";
CM_ SG_ 1622 BIU656_5_5_CSTM_HF_PRG_LOCK "ﾊﾝｽﾞﾌﾘｰPRGﾛｯｸ有無
";
CM_ SG_ 1622 BIU656_5_6_CSTM_KICK_SENSOR "ｷｯｸｾﾝｻ有無
";
CM_ SG_ 1622 BIU656_5_7_KICK_REQ_PRG "ｷｯｸ要因PRG駆動要求
";
CM_ SG_ 1622 BIU656_4_0_NOT_SMT_KEY_RG_SW "ｷｰﾚｽ R/G SW（ｽﾏｰﾄ無し車）
";
CM_ SG_ 1622 BIU656_4_2_SMT_KEY_RG_SW "ｷｰﾚｽ R/G SW（ｽﾏｰﾄ有り車）
";
CM_ SG_ 1622 BIU656_4_4_OPEN_RG_OPENER_SW "RｹﾞｰﾄｵｰﾌﾟﾅSW駆動処理
";
CM_ SG_ 1622 BIU656_3_4_CHECKED_KEYNO "照合ｷｰNo.
";
CM_ SG_ 1622 BIU656_3_7_LOCKSTATUS_DRVR "ﾄﾞｱﾛｯｸ状態信号（運席）
";
CM_ SG_ 1622 BIU656_2_0_TRIG_LOCK_UNLOCK "ﾄﾞｱﾛｯｸ/ｱﾝﾛｯｸ出力情報
";
CM_ SG_ 1622 BIU656_1_0_MSG_COUNTER "ﾒｯｾｰｼﾞｶｳﾝﾀ
";
CM_ SG_ 1622 BIU656_0_0_CHECK_SUM "ﾁｪｯｸｻﾑ
";
CM_ SG_ 1621 BIU655_4_0_BUZZER_PATTERN "ﾌﾞｻﾞｰ出力ﾊﾟﾀｰﾝ要求
";
CM_ SG_ 1621 BIU655_3_0_BUZZER_VOL_REQ "室外ﾌﾞｻﾞｰ音量要求
";
CM_ SG_ 1621 BIU655_3_3_RDEF_RELAY_REQ "ﾘｱﾃﾞﾌｫｯｶﾞ出力要求
";
CM_ SG_ 1621 BIU655_3_4_WIPER_DEICER_REQ "ﾜｲﾊﾟﾃﾞｱｲｻ出力要求
";
CM_ SG_ 1621 BIU655_3_5_FT_WIPER_REQ "Fﾜｲﾊﾟ駆動要求
";
CM_ SG_ 1621 BIU655_2_0_RR_WIPER_REQ "Rﾜｲﾊﾟ駆動要求
";
CM_ SG_ 1621 BIU655_2_1_WASHER_REQ "ｳｫｯｼｬ出力要求
";
CM_ SG_ 1621 BIU655_2_3_HL_WASHER_REQ "H/Lｳｫｯｼｬ出力要求
";
CM_ SG_ 1621 BIU655_2_4_FT_FOG_RELAY_REQ "Fﾌｫｸﾞﾗﾝﾌﾟﾘﾚｰ出力要求
";
CM_ SG_ 1621 BIU655_2_5_HEADLAMP_HI_REQ "ﾗｲﾃｨﾝｸﾞHi出力要求
";
CM_ SG_ 1621 BIU655_2_7_HEADLAMP_LO_REQ "ﾗｲﾃｨﾝｸﾞLo出力要求
";
CM_ SG_ 1621 BIU655_1_0_MSG_COUNTER "ﾒｯｾｰｼﾞｶｳﾝﾀ
";
CM_ SG_ 1621 BIU655_0_0_CHECK_SUM "ﾁｪｯｸｻﾑ
";
CM_ SG_ 1618 BIU652_7_0_IND_SECURITY_IMB "ｾｷｭﾘﾃｨ(ｲﾓﾋﾞ)ｲﾝｼﾞｹｰﾀ表示
";
CM_ SG_ 1618 BIU652_6_0_OCCUPATION_3RDRH "3列目右乗員有無信号
";
CM_ SG_ 1618 BIU652_6_1_OCCUPATION_3RDCTR "3列目中央乗員有無信号
";
CM_ SG_ 1618 BIU652_6_2_OCCUPATION_3RDLH "3列目左乗員有無信号
";
CM_ SG_ 1618 BIU652_6_3_OCCUPATION_RRRH "後席右乗員有無信号
";
CM_ SG_ 1618 BIU652_6_4_OCCUPATION_RRCTR "後席中央乗員有無信号
";
CM_ SG_ 1618 BIU652_6_5_OCCUPATION_RRLH "後席左乗員有無信号
";
CM_ SG_ 1618 BIU652_6_6_HORNHAZARD_RES_SIG "ﾘﾓｰﾄﾎｰﾝ&ﾗｲﾄ応答信号
";
CM_ SG_ 1618 BIU652_6_7_OCCUPATION_DRVR "D席乗員有無信号
";
CM_ SG_ 1618 BIU652_5_0_STATUS_ROOMLAMP "ﾙｰﾑﾗﾝﾌﾟ状態
";
CM_ SG_ 1618 BIU652_5_3_HEADLAMP_SMALL "ﾍｯﾄﾞﾗﾝﾌﾟ　ｽﾓｰﾙ
";
CM_ SG_ 1618 BIU652_5_4_ALL_UNLOCK_STATE "全席ｱﾝﾛｯｸ出力状態
";
CM_ SG_ 1618 BIU652_5_5_DRVR_UNLOCK_STATE "運転席ｱﾝﾛｯｸ出力状態
";
CM_ SG_ 1618 BIU652_5_6_ALL_LOCK_STATE "全席ﾛｯｸ出力状態
";
CM_ SG_ 1618 BIU652_4_0_TRIG_LOCK_UNLOCK "ﾄﾞｱﾛｯｸ/ｱﾝﾛｯｸ出力要因信号
";
CM_ SG_ 1618 BIU652_3_0_DOOR_DRVR "ﾄﾞｱSW　D席
";
CM_ SG_ 1618 BIU652_3_1_DOOR_PASS "ﾄﾞｱSW　P席
";
CM_ SG_ 1618 BIU652_3_2_DOOR_RRRH "ﾄﾞｱSW　後席右
";
CM_ SG_ 1618 BIU652_3_3_DOOR_RRLH "ﾄﾞｱSW　後席左
";
CM_ SG_ 1618 BIU652_3_4_DOOR_RG "ﾄﾞｱSW　Rｹﾞｰﾄ
";
CM_ SG_ 1618 BIU652_3_5_DOOR_TR "ﾄﾞｱSW　ﾄﾗﾝｸ
";
CM_ SG_ 1618 BIU652_3_7_OPENSW_RG "ﾘﾔｹﾞｰﾄｵｰﾌﾟﾅSW信号
";
CM_ SG_ 1618 BIU652_2_0_LOCKSTATUS_DRVR "ﾄﾞｱﾛｯｸ状態信号（運席）
";
CM_ SG_ 1618 BIU652_2_1_LOCKSTATUS_PASS "ﾄﾞｱﾛｯｸ状態信号（助手席）
";
CM_ SG_ 1618 BIU652_2_2_LOCKSTATUS_RRRH "ﾄﾞｱﾛｯｸ状態信号（後席右）
";
CM_ SG_ 1618 BIU652_2_3_LOCKSTATUS_RRLH "ﾄﾞｱﾛｯｸ状態信号（後席左）
";
CM_ SG_ 1618 BIU652_2_4_LOCKSTATUS_RG "ﾄﾞｱﾛｯｸ状態信号（Rｹﾞｰﾄ）
";
CM_ SG_ 1618 BIU652_2_6_UNLOCK_DOORKEYSW "ﾄﾞｱｷｰSW　ｱﾝﾛｯｸ
";
CM_ SG_ 1618 BIU652_2_7_LOCK_DOORKEYSW "ﾄﾞｱｷｰSW ﾛｯｸ
";
CM_ SG_ 1618 BIU652_1_0_MSG_COUNTER "ﾒｯｾｰｼﾞｶｳﾝﾀ
";
CM_ SG_ 1618 BIU652_0_0_CHECK_SUM "ﾁｪｯｸｻﾑ
";
CM_ SG_ 1617 BIU651_7_0_PWPOS_RL "RL席窓位置
";
CM_ SG_ 1617 BIU651_7_2_PWPOS_RR "RR席窓位置
";
CM_ SG_ 1617 BIU651_7_4_PWPOS_PASS "P席窓位置
";
CM_ SG_ 1617 BIU651_7_6_PWPOS_DRVR "D席窓位置
";
CM_ SG_ 1617 BIU651_6_0_IND_ACTIVE_HBA "HBA作動灯
";
CM_ SG_ 1617 BIU651_6_2_ADB_ACTIVE "ADB有無ﾌﾗｸﾞ
";
CM_ SG_ 1617 BIU651_6_3_JUDGE_ILL "照度判定信号
";
CM_ SG_ 1617 BIU651_6_4_TYPE_LO_BEAM "Loﾋﾞｰﾑ光源種類
";
CM_ SG_ 1617 BIU651_6_6_TYPE_HI_BEAM "Hiﾋﾞｰﾑ光源種類
";
CM_ SG_ 1617 BIU651_5_0_SRF_ACTIVE "SRF有無ﾌﾗｸﾞ
";
CM_ SG_ 1617 BIU651_5_1_SRF_IND "SRF OFF ｲﾝｼﾞｹｰﾀ
";
CM_ SG_ 1617 BIU651_5_3_SRF_LAMP_LIGHT "SRF（右）点灯状態
";
CM_ SG_ 1617 BIU651_5_4_SRF_LAMP_LEFT "SRF（左）点灯状態
";
CM_ SG_ 1617 BIU651_5_5_MSG_STATUS_HBA "HBA文言表示
";
CM_ SG_ 1617 BIU651_5_7_IND_FAIL_HBA "HBAﾌｪｰﾙ灯
";
CM_ SG_ 1617 BIU651_4_0_BUZ_PATTERN "ﾌﾞｻﾞｰ吹鳴ﾊﾟﾀｰﾝ情報
";
CM_ SG_ 1617 BIU651_4_4_CSTM_OPE_ALARM "ｾｷｭﾘﾃｨｱﾗｰﾑ　ｶｽﾀﾏｲｽﾞ
";
CM_ SG_ 1617 BIU651_4_6_CSTM_HBA "HBA（ﾐﾗｰ/ｱｲｻｲﾄ）有無ﾌﾗｸﾞ
";
CM_ SG_ 1617 BIU651_3_0_HEADLAMP_PASS_SW "ﾍｯﾄﾞﾗﾝﾌﾟ　PASSｽｲｯﾁ
";
CM_ SG_ 1617 BIU651_3_1_HEADLAMP_AUTO_SW "ﾍｯﾄﾞﾗﾝﾌﾟ　AUTOｽｲｯﾁ
";
CM_ SG_ 1617 BIU651_3_2_JUDGE_DOOR_LOCK "室内照明制御用ﾄﾞｱﾛｯｸ判定ﾌﾗｸﾞ
";
CM_ SG_ 1617 BIU651_3_3_JUDGE_DOOR_UNLOCK "室内照明制御用ﾄﾞｱｱﾝﾛｯｸ判定
";
CM_ SG_ 1617 BIU651_3_4_HEADLAMP_Lo_SW "ﾍｯﾄﾞﾗﾝﾌﾟ　Loｽｲｯﾁ
";
CM_ SG_ 1617 BIU651_3_5_HEADLAMP_HI_SW "ﾍｯﾄﾞﾗﾝﾌﾟ　Hiｽｲｯﾁ
";
CM_ SG_ 1617 BIU651_3_6_WIPER_AUTO_SW "ﾜｲﾊﾟｰ AUTO SW
";
CM_ SG_ 1617 BIU651_3_7_PRG_LIN_MEMORY_ON_OFF "PRG LIN通信用 メモリ機能 ON/OFF状態
";
CM_ SG_ 1617 BIU651_2_0_CSTM_ILLUMI_SSR "照度ｾﾝｻ有無ﾌﾗｸﾞ
";
CM_ SG_ 1617 BIU651_2_1_HANDLE "ﾊﾝﾄﾞﾙ情報
";
CM_ SG_ 1617 BIU651_2_2_CSTM_SMT "ｽﾏｰﾄ有無
";
CM_ SG_ 1617 BIU651_2_3_AJARDOOR_STATUS "半ﾄﾞｱ判定結果
";
CM_ SG_ 1617 BIU651_2_4_ONETOUCH_LAMP_OUT "ﾜﾝﾀｯﾁ全照明出力
";
CM_ SG_ 1617 BIU651_2_5_PRG_FAIL_FLAG "PRG通信異常フラグ
";
CM_ SG_ 1617 BIU651_2_6_CSTM_PSMECU "ｼｰﾄﾒﾓﾘ有無ﾌﾗｸﾞ
";
CM_ SG_ 1617 BIU651_2_7_STATE_REGIST_DEL "ﾒﾓﾘ登録/消去状態ﾌﾗｸﾞ
";
CM_ SG_ 1617 BIU651_1_0_MSG_COUNTER "ﾒｯｾｰｼﾞｶｳﾝﾀ
";
CM_ SG_ 1617 BIU651_1_4_SRPOS "サンルーフガラス位置
";
CM_ SG_ 1617 BIU651_1_7_WIPER_INT_STATUS "Fﾜｲﾊﾟ間欠作動状態
";
CM_ SG_ 1617 BIU651_0_0_CHECK_SUM "ﾁｪｯｸｻﾑ
";
CM_ SG_ 942 BIU3AE_5_0_WIPER_FT_VOLUME "ﾄﾞﾗｲﾊﾞAUTO感度設定
";
CM_ SG_ 942 BIU3AE_4_0_DATA_RAINDROP "雨滴情報
";
CM_ SG_ 942 BIU3AE_4_4_FT_WIPER_FAIL "Fﾜｲﾊﾟﾌｪｰﾙ状態
";
CM_ SG_ 942 BIU3AE_4_5_WIPER_FT "FtﾜｲﾊﾟSW状態
";
CM_ SG_ 942 BIU3AE_3_0_WINKER_LEVER_STATUS "ウィンカーレバー状態
";
CM_ SG_ 942 BIU3AE_3_4_WINKER_FACTOR "ｳｨﾝｶｰ出力要因
";
CM_ SG_ 942 BIU3AE_2_0_TURN_LAMP_FAIL_LEFT "メインバルブ異常検知(左)
";
CM_ SG_ 942 BIU3AE_2_1_TURN_LAMP_FAIL_RIGHT "メインバルブ異常検知(右)
";
CM_ SG_ 942 BIU3AE_2_3_HAZARD_SW "ハザードSW状態
";
CM_ SG_ 942 BIU3AE_1_0_MSG_COUNTER "ﾒｯｾｰｼﾞｶｳﾝﾀ
";
CM_ SG_ 942 BIU3AE_0_0_CHECK_SUM "ﾁｪｯｸｻﾑ
";
CM_ SG_ 940 BIU3AC_7_0_HEADLAMP_SMALL "ﾍｯﾄﾞﾗﾝﾌﾟ　ｽﾓｰﾙ
";
CM_ SG_ 940 BIU3AC_7_1_HEADLAMP_LO_REQ "ﾗｲﾃｨﾝｸﾞLo出力要求
";
CM_ SG_ 940 BIU3AC_7_2_HEADLAMP_HI_REQ "ﾗｲﾃｨﾝｸﾞHi出力要求
";
CM_ SG_ 940 BIU3AC_7_3_FT_FOG_RELAY_REQ "Fﾌｫｸﾞﾗﾝﾌﾟﾘﾚｰ出力要求
";
CM_ SG_ 940 BIU3AC_7_4_FOGLAMP_RR "ﾘｱﾌｫｸﾞﾗﾝﾌﾟ
";
CM_ SG_ 940 BIU3AC_7_5_DRL "DRL出力信号
";
CM_ SG_ 940 BIU3AC_7_6_WIPER_FRONT "FTﾜｲﾊﾟ(RTN)
";
CM_ SG_ 940 BIU3AC_7_7_RDEF_RELAY_REQ "ﾘｱﾃﾞﾌｫｯｶﾞ出力要求
";
CM_ SG_ 940 BIU3AC_6_0_RDEFOGSW "ﾘｱﾃﾞﾌｫｯｶﾞSW状態
";
CM_ SG_ 940 BIU3AC_6_1_CSTM_PRG "ﾊﾟﾜｰﾘｱｹﾞｰﾄ有無ﾌﾗｸﾞ
";
CM_ SG_ 940 BIU3AC_6_2_FAIL_SHIFTLOCKSOL "ｼﾌﾄﾛｯｸｿﾚﾉｲﾄﾞ異常
";
CM_ SG_ 940 BIU3AC_6_3_REQ_CANCEL_ISS "ISSｷｬﾝｾﾙ要求
";
CM_ SG_ 940 BIU3AC_6_4_REVERSE_MT "MTﾘﾊﾞｰｽSW
";
CM_ SG_ 940 BIU3AC_6_5_HANDBRAKE "ﾊﾟｰｷﾝｸﾞﾌﾞﾚｰｷSW
";
CM_ SG_ 940 BIU3AC_6_6_BRAKELAMPSW "ﾌﾞﾚｰｷﾗﾝﾌﾟSW
";
CM_ SG_ 940 BIU3AC_6_7_TOWING_SW "ﾄｰｲﾝｸﾞSW
";
CM_ SG_ 940 BIU3AC_5_0_LANE_OFF_SW "LANE OFFｽｲｯﾁ
";
CM_ SG_ 940 BIU3AC_5_2_PCR_OFF_SW "P-CR　OFFｽｲｯﾁ
";
CM_ SG_ 940 BIU3AC_5_4_DIMMER_CANCEL "ﾃﾞｨﾏｰｷｬﾝｾﾙ信号
";
CM_ SG_ 940 BIU3AC_5_5_KEYSW "ｷｰSW
";
CM_ SG_ 940 BIU3AC_5_6_IND_ND_SHIFTLOCK "N-Dｼﾌﾄﾛｯｸ用ﾌﾞﾚｰｷ押下表示有無
";
CM_ SG_ 940 BIU3AC_4_0_DOOR_DRVR "ﾄﾞｱSW　D席
";
CM_ SG_ 940 BIU3AC_4_1_DOOR_PASS "ﾄﾞｱSW　P席
";
CM_ SG_ 940 BIU3AC_4_2_DOOR_RRRH "ﾄﾞｱSW　後席右
";
CM_ SG_ 940 BIU3AC_4_3_DOOR_RRLH "ﾄﾞｱSW　後席左
";
CM_ SG_ 940 BIU3AC_4_4_DOOR_RG "ﾄﾞｱSW　Rｹﾞｰﾄ
";
CM_ SG_ 940 BIU3AC_4_5_DOOR_TR "ﾄﾞｱSW　ﾄﾗﾝｸ
";
CM_ SG_ 940 BIU3AC_4_6_HOOD_CLOSE "ﾌｰﾄﾞSW　閉側
";
CM_ SG_ 940 BIU3AC_4_7_HOOD_OPEN "ﾌｰﾄﾞＳＷ　開側
";
CM_ SG_ 940 BIU3AC_3_0_GW_STSW_RES "RESからのSTSWﾃﾞｰﾀ
";
CM_ SG_ 940 BIU3AC_3_1_GW_POWER_RES "SMTからのﾘﾓｽﾀ電源ONﾃﾞｰﾀ
";
CM_ SG_ 940 BIU3AC_3_3_ST1 "STﾌﾗｸﾞ1
";
CM_ SG_ 940 BIU3AC_3_4_ST2 "STﾌﾗｸﾞ2
";
CM_ SG_ 940 BIU3AC_3_5_ACC "ACC
";
CM_ SG_ 940 BIU3AC_3_6_IGA "IG-a
";
CM_ SG_ 940 BIU3AC_3_7_BAT_BACKUP "B/up
";
CM_ SG_ 940 BIU3AC_2_0_CSTM_AC "A/C　ＣＡＮ接続有無ﾌﾗｸﾞ
";
CM_ SG_ 940 BIU3AC_2_1_IMB_SMT "IM/SMT判別情報
";
CM_ SG_ 940 BIU3AC_2_3_CSTM_WGN_SDN "WGN/SDN判別ﾌﾗｸﾞ
";
CM_ SG_ 940 BIU3AC_2_4_VAL_SEAT_BACK_CTSM "ｼｰﾄ現在設定値
";
CM_ SG_ 940 BIU3AC_2_5_VAL_MIR_AFOLD_CTSM "ﾐﾗｰ電格設定値
";
CM_ SG_ 940 BIU3AC_2_6_VAL_MIR_RTILT_CTSM "R連動ﾐﾗｰ設定値
";
CM_ SG_ 940 BIU3AC_2_7_WIPER_REAR "RRﾜｲﾊﾟ(RTN)
";
CM_ SG_ 940 BIU3AC_1_0_MSG_COUNTER "ﾒｯｾｰｼﾞｶｳﾝﾀ
";
CM_ SG_ 940 BIU3AC_1_4_PADDLESHIFT_DOWN_SW "ﾊﾟﾄﾞﾙｼﾌﾄﾀﾞｳﾝSW
";
CM_ SG_ 940 BIU3AC_1_5_PADDLESHIFT_UP_SW "ﾊﾟﾄﾞﾙｼﾌﾄｱｯﾌﾟSW
";
CM_ SG_ 940 BIU3AC_1_6_MANUALMODE_SW "ﾏﾆｭｱﾙﾓｰﾄﾞSW
";
CM_ SG_ 940 BIU3AC_0_0_CHECK_SUM "ﾁｪｯｸｻﾑ
";
CM_ SG_ 1616 BIU650_7_0_Reserved "ワイパーサービスモードSW操作禁止フラグ
";
CM_ SG_ 1616 BIU650_7_1_Reserved "ワイパーサービスモード有無フラグ
";
CM_ SG_ 1616 BIU650_7_2_Reserved "ワイパーサービスモード状態
";
CM_ SG_ 1616 BIU650_7_3_DOOR_LINK_SW_STS "室内灯DOOR連動SW状態
";
CM_ SG_ 1616 BIU650_7_4_Reserved "ウィンドウロックSW信号
";
CM_ SG_ 1616 BIU650_6_0_Reserved "オートライト感度調整設定値
";
CM_ SG_ 1616 BIU650_6_3_RR_WIPER_STATUS "Ｒワイパ駆動状態
";
CM_ SG_ 1616 BIU650_6_5_WIPER_SENSITIVITY_CTM "ワイパ感度設定
";
CM_ SG_ 1616 BIU650_5_0_Reserved "ﾄﾞｱSW運転席信号
";
CM_ SG_ 1616 BIU650_5_1_Reserved "全ﾄﾞｱ開閉変化ｲﾍﾞﾝﾄ判定
";
CM_ SG_ 1616 BIU650_5_2_FMH_DOOR_LOCK "フォローミーホームドアロック判定
";
CM_ SG_ 1616 BIU650_5_4_LMH_DOOR_LOCK "リードミーホームドアロック判定
";
CM_ SG_ 1616 BIU650_4_0_REQ_OPE_AUTOLIGHT "オートライト点灯/消灯要求
";
CM_ SG_ 1616 BIU650_4_2_STATE_SHINSSR "ライトセンサステータス
";
CM_ SG_ 1616 BIU650_4_4_STATE_RLS_FAIL "RLS異常状態
";
CM_ SG_ 1616 BIU650_3_0_REQ_FWASHER_ITLOCK "F ウォッシャ連動要求
";
CM_ SG_ 1616 BIU650_3_1_FWIPER_RTN "F ワイパ（RTN)補正
";
CM_ SG_ 1616 BIU650_3_2_TURN_LAMP_STATE_LEFT "左ターンランプ状態
";
CM_ SG_ 1616 BIU650_3_3_TURN_LAMP_STATE_RIGHT "右ターンランプ状態
";
CM_ SG_ 1616 BIU650_3_4_Reserved "RES操作ﾗｲﾃｨﾝｸﾞ1出力要求
";
CM_ SG_ 1616 BIU650_2_0_HEADLAMP_SMALL_SW "ライティング1SW信号
";
CM_ SG_ 1616 BIU650_2_1_HEADLAMP_LO_SW "ライティング2SW信号
";
CM_ SG_ 1616 BIU650_2_2_HEADLAMP_OFF_SW "ライティングOFF SW信号
";
CM_ SG_ 1616 BIU650_2_3_HEADLAMP_Hi_SW "ディマーHi SW 信号
";
CM_ SG_ 1616 BIU650_2_4_HEAD_LAMP_PASS_SW "ディマーPass SW 信号
";
CM_ SG_ 1616 BIU650_2_5_FFOG_SW "FフォグランプSW信号
";
CM_ SG_ 1616 BIU650_2_6_RFOG_SW "RフォグランプSW信号
";
CM_ SG_ 1616 BIU650_1_0_MSG_COUNTER "メッセージカウンタ
";
CM_ SG_ 1616 BIU650_0_0_CHECK_SUM "チェックサム
";
CM_ SG_ 1615 BIU64F_4_0 "吹鳴回数
";
CM_ SG_ 1615 BIU64F_3_0 "音量
";
CM_ SG_ 1615 BIU64F_2_0 "吹鳴要求パターン
";
CM_ SG_ 1615 BIU64F_1_0_MSG_COUNTER "ﾒｯｾｰｼﾞｶｳﾝﾀ
";
CM_ SG_ 1615 BIU64F_0_0_CHECK_SUM "ﾁｪｯｸｻﾑ
";
CM_ SG_ 1350 EPS546_0_0_NETWORK_STATUS "ﾈｯﾄﾜｰｸｽﾃｰﾀｽ
";
CM_ SG_ 798 BST31E_7_0_SND_MAC "送信用MAC
";
CM_ SG_ 798 BST31E_4_4_RESET_FLG "ﾘｾｯﾄﾌﾗｸﾞ
";
CM_ SG_ 798 BST31E_4_6_SNDMSG_CNT "送信用ﾒｯｾｰｼﾞｶｳﾝﾀ
";
CM_ SG_ 798 BST31E_3_0_MSG_COUNTER "ﾒｯｾｰｼﾞｶｳﾝﾀ
";
CM_ SG_ 798 BST31E_3_4_HBC_REQUEST "HBC要求信号
";
CM_ SG_ 799 BST31F_2_3_HBC_REQUEST "HBC要求信号
";
CM_ SG_ 799 BST31F_1_0_MSG_COUNTER "メッセージカウンタ
";
CM_ SG_ 799 BST31F_0_0_CHECK_SUM "チェックサム
";
CM_ SG_ 345 BST159_7_0_SND_MAC "送信用MAC
";
CM_ SG_ 345 BST159_4_4_RESET_FLG "ﾘｾｯﾄﾌﾗｸﾞ
";
CM_ SG_ 345 BST159_4_6_SNDMSG_CNT "送信用ﾒｯｾｰｼﾞｶｳﾝﾀ
";
CM_ SG_ 345 BST159_3_0_MSG_COUNTER "ﾒｯｾｰｼﾞｶｳﾝﾀ
";
CM_ SG_ 345 BST159_3_4_HBC_REQUEST "HBC要求信号
";
CM_ SG_ 345 BST159_2_0_P_RUNOUT "全負荷点相当液圧値
";
CM_ SG_ 59 BST03B_7_0_SND_MAC "送信用MAC
";
CM_ SG_ 59 BST03B_4_4_RESET_FLG "ﾘｾｯﾄﾌﾗｸﾞ
";
CM_ SG_ 59 BST03B_4_6_SNDMSG_CNT "送信用ﾒｯｾｰｼﾞｶｳﾝﾀ
";
CM_ SG_ 59 BST03B_3_0_MSG_COUNTER "ﾒｯｾｰｼﾞｶｳﾝﾀ
";
CM_ SG_ 59 BST03B_3_4_S_OUTPUTROD_DRIVER "ドライバ要求ストローク値
";
CM_ SG_ 809 BST329_2_0_WARN_BRAKE_RED "電動ﾌﾞｰｽﾀﾜｰﾆﾝｸﾞﾗﾝﾌﾟ信号（赤）
";
CM_ SG_ 809 BST329_1_0_MSG_COUNTER "メッセージカウンタ
";
CM_ SG_ 809 BST329_1_4_EB_HMI_WARNINGON "電動ﾌﾞｰｽﾀﾜｰﾆﾝｸﾞﾗﾝﾌﾟ信号
";
CM_ SG_ 809 BST329_1_5_WARN_BST_MET_LCD "メータ内液晶用BSTウォーニング
";
CM_ SG_ 809 BST329_1_6_WARN_BST_RED "ﾜｰﾆﾝｸﾞﾗﾝﾌﾟ信号（赤）
";
CM_ SG_ 809 BST329_0_0_CHECK_SUM "チェックサム
";
CM_ SG_ 319 BST13F_4_0_FAIL_VDC "VDC通信異常
";
CM_ SG_ 319 BST13F_3_0_P_RUNOUT "全負荷点相当液圧値
";
CM_ SG_ 319 BST13F_2_0_BRAKE_PEDAL_APPLIED "ブレーキペダル操作フラグ
";
CM_ SG_ 319 BST13F_2_1_BRAKE_PEDAL_APPLIED_Q "ブレーキペダル操作フラグステータス
";
CM_ SG_ 319 BST13F_2_3_HBC_REQUEST "HBC要求信号
";
CM_ SG_ 319 BST13F_2_4_EB_DIAG_ACTIVE "電動ブースタダイアグモード信号
";
CM_ SG_ 319 BST13F_2_6_P_RUNOUT_Q "全負荷点相当液圧ステータス信号
";
CM_ SG_ 319 BST13F_1_0_MSG_COUNTER "メッセージカウンタ
";
CM_ SG_ 319 BST13F_1_4_EB_ESC_COMPATIBILITY "BST-VDC互換性確認信号
";
CM_ SG_ 319 BST13F_0_0_CHECK_SUM "チェックサム
";
CM_ SG_ 58 BST03A_4_0_S_INPUTROD_ACT "Input Rodストローク値
";
CM_ SG_ 58 BST03A_1_0_MSG_COUNTER "メッセージカウンタ
";
CM_ SG_ 58 BST03A_0_0_CHECK_SUM "チェックサム
";
CM_ SG_ 1282 BST502_1_4_ActiveWakeUpBit "Active Wakeup ﾌﾗｸﾞ
";
CM_ SG_ 1282 BST502_0_0_SourceNodeID "送信元ID
";
CM_ SG_ 811 EPB32B_7_0_AVH_TARGET_PRESS "AVH目標保持圧
";
CM_ SG_ 811 EPB32B_6_0_VEHICLE_RUN_STOP_FLG "車両走行停止判定ﾌﾗｸﾞ
";
CM_ SG_ 811 EPB32B_6_2_REQ_HILL_P_CAUTION "坂道駐車警告表示要求
";
CM_ SG_ 811 EPB32B_5_0_FLG_AVH_OILPRES_EPB "AVH制御ﾌﾗｸﾞ(液圧/EPB)
";
CM_ SG_ 811 EPB32B_5_1_FLG_AVH "AVH作動ﾌﾗｸﾞ
";
CM_ SG_ 811 EPB32B_5_2_AVH_INTENSIFY_PRES "ISS中AVH中増圧ﾌﾗｸﾞ
";
CM_ SG_ 811 EPB32B_5_3_BREAK_IND "ﾌﾞﾚｰｷ踏み指示
";
CM_ SG_ 811 EPB32B_5_5_AVH_ON_LAMP "AVH_ON灯
";
CM_ SG_ 811 EPB32B_5_6_AVH_FUNC_ON_LUMP "AVH 作動灯
";
CM_ SG_ 811 EPB32B_5_7_AVH_ACTIVE "AVH有無ﾌﾗｸﾞ
";
CM_ SG_ 811 EPB32B_4_0_BUZZER "ﾌﾞｻﾞｰ
";
CM_ SG_ 811 EPB32B_4_2_HILL_HOLD_ON_LAMP "ﾋﾙﾎｰﾙﾄﾞ機能ONﾗﾝﾌﾟ
";
CM_ SG_ 811 EPB32B_4_3_CLAMP_LAMP "EPB作動灯
";
CM_ SG_ 811 EPB32B_4_5_WARN_LAMP "EPB警告灯
";
CM_ SG_ 811 EPB32B_4_7_WARN_EPB_MET_LCD "ﾒｰﾀ内液晶用EPB警告灯
";
CM_ SG_ 811 EPB32B_3_0_STATUS_EPB "EPB作動状態
";
CM_ SG_ 811 EPB32B_3_3_DYNAMIC_PARKING "動的ﾊﾟｰｷﾝｸﾞﾌﾗｸﾞ
";
CM_ SG_ 811 EPB32B_3_4_HILL_HOLD_RUN_FLG "ﾋﾙﾎｰﾙﾄﾞ作動ﾌﾗｸﾞ
";
CM_ SG_ 811 EPB32B_3_5_INHIBIT_ISS_DELAY "ISS作動禁止要求ﾌﾗｸﾞ(判定ﾃﾞｨﾚｲ有り)
";
CM_ SG_ 811 EPB32B_3_6_INHIBIT_ISS "ISS作動禁止要求ﾌﾗｸﾞ(判定ﾃﾞｨﾚｲ無し)
";
CM_ SG_ 811 EPB32B_3_7_AVH_PERMIT_CONT_ACC "AVH-ACC協調許可フラグ
";
CM_ SG_ 811 EPB32B_2_0_ERR_INFO "EPBｴﾗｰ情報
";
CM_ SG_ 811 EPB32B_2_2_EPB_FAIL_FLG1 "EPBﾌｪｰﾙﾌﾗｸﾞ1
";
CM_ SG_ 811 EPB32B_2_3_EPB_FAIL_FLG2 "EPBﾌｪｰﾙﾌﾗｸﾞ2
";
CM_ SG_ 811 EPB32B_2_4_EPB_FAIL_FLG3 "EPBﾌｪｰﾙﾌﾗｸﾞ3
";
CM_ SG_ 811 EPB32B_1_0_MSG_COUNTER "ﾒｯｾｰｼﾞｶｳﾝﾀ
";
CM_ SG_ 811 EPB32B_1_4_WAKE_UP_FRAME "ｳｪｲｸｱｯﾌﾟﾌﾚｰﾑ識別ﾌﾗｸﾞ
";
CM_ SG_ 811 EPB32B_1_5_REQ_COMM_CONT "通信継続要求ﾌﾗｸﾞ
";
CM_ SG_ 811 EPB32B_1_6 "予約:通信継続要求ﾌﾗｸﾞ(拡張)
";
CM_ SG_ 811 EPB32B_0_0_CHECK_SUM "ﾁｪｯｸｻﾑ
";
CM_ SG_ 1281 EPB501_1_4_ActiveWakeUpBit "Active Wakeup ﾌﾗｸﾞ
";
CM_ SG_ 1281 EPB501_0_0_SourceNodeID "送信元ID
";
CM_ SG_ 57 VDC039_7_0_SND_MAC "送信用MAC
";
CM_ SG_ 57 VDC039_4_4_RESET_FLG "ﾘｾｯﾄﾌﾗｸﾞ
";
CM_ SG_ 57 VDC039_4_6_SNDMSG_CNT "送信用ﾒｯｾｰｼﾞｶｳﾝﾀ
";
CM_ SG_ 57 VDC039_3_0_MSG_COUNTER "ﾒｯｾｰｼﾞｶｳﾝﾀ
";
CM_ SG_ 57 VDC039_3_4_Q_TARGET_EXTERNAL_Q "自動ブレーキ要求状態
";
CM_ SG_ 57 VDC039_1_0_Q_TARGET_EXTERNAL "外部目標流量
";
CM_ SG_ 323 VDC143_3_0_VEHICLE_SPEED "車両速度
";
CM_ SG_ 323 VDC143_2_0_P_EXT_MAX "4輪の車輪液圧推定値の最大値
";
CM_ SG_ 323 VDC143_1_0_MSG_COUNTER "メッセージカウンタ
";
CM_ SG_ 323 VDC143_1_4_IG_ON "VDCイグニッションON/OFF情報
";
CM_ SG_ 323 VDC143_1_5_VEHICLE_SPEED_Q "車両速度ステータス信号
";
CM_ SG_ 323 VDC143_1_7_DIAG_STATUS "VDC DIAG状態フラグ
";
CM_ SG_ 323 VDC143_0_0_CHECK_SUM "チェックサム
";
CM_ SG_ 56 VDC038_6_0_TARGET_FLUID_PRES_VDC "目標液圧(VDC)
";
CM_ SG_ 56 VDC038_5_2_P_MC_Q "マスターシリンダ液圧ステータス信号
";
CM_ SG_ 56 VDC038_5_4_PRESS_HOLD_ACTIVE "VDC液圧保持フラグ
";
CM_ SG_ 56 VDC038_5_5_DRIVE_OFF_DETEC "ドライブオフ情報
";
CM_ SG_ 56 VDC038_4_0_P_MC1 "マスターシリンダ液圧信号
";
CM_ SG_ 56 VDC038_2_0_Q_TARGET_EXTERNAL "外部目標流量
";
CM_ SG_ 56 VDC038_1_0_MSG_COUNTER "メッセージカウンタ
";
CM_ SG_ 56 VDC038_1_4_ABS_ACTIVE "ABS作動フラグ
";
CM_ SG_ 56 VDC038_1_6_Q_TARGET_EXTERNAL_Q "自動ブレーキ要求状態
";
CM_ SG_ 56 VDC038_0_0_CHECK_SUM "チェックサム
";
CM_ SG_ 362 VDC16A_6_0_ACCELERATE_F_R_R160 "前後Gｾﾝｻ値(UN-R160-01用)
";
CM_ SG_ 362 VDC16A_4_0_YAW_RATE_HI_RES "ヨーレート(高分解能)
";
CM_ SG_ 362 VDC16A_3_7_JUDGE_EXTRUSION "押し出し判定ﾌﾗｸﾞ
";
CM_ SG_ 362 VDC16A_2_0_ACCELERATE_L_R_HI_RES "横加速度(高分解能)
";
CM_ SG_ 362 VDC16A_1_0_MSG_COUNTER "メッセージカウンタ
";
CM_ SG_ 362 VDC16A_0_0_CHECK_SUM "チェックサム
";
CM_ SG_ 808 VDC328_7_1_IND_WARN_CBC "CBC 警告灯
";
CM_ SG_ 808 VDC328_7_2_ACTIVATE_CBC "CBC 作動灯
";
CM_ SG_ 808 VDC328_7_3_FLAG_ACT_CBC "CBC 作動フラグ
";
CM_ SG_ 808 VDC328_6_0_PROHIBIT_VDC_OFF_CCU "CCU協調VDC OFF制御禁止状態
";
CM_ SG_ 808 VDC328_6_1_PROHIBIT_AVH_CCU "CCU協調AVH制御禁止状態
";
CM_ SG_ 808 VDC328_5_0_VDC_BUZZER "VDCブザー
";
CM_ SG_ 808 VDC328_5_2_WARN_BRAKE_BOOST "ﾌﾞﾚｰｷ倍力機能ｳｫｰﾆﾝｸﾞ
";
CM_ SG_ 808 VDC328_5_4_WARN_RBS "RBS 警告灯
";
CM_ SG_ 808 VDC328_5_6_IND_HSA_ON "HSA ON灯
";
CM_ SG_ 808 VDC328_5_7_IND_TCS_OFF "TCS OFFﾗﾝﾌﾟ
";
CM_ SG_ 808 VDC328_4_0_IND_VDC_OFF "VDC OFFﾗﾝﾌﾟ
";
CM_ SG_ 808 VDC328_4_1_STATE_ACTIVATE_VDC "VDC/TCS作動状態信号
";
CM_ SG_ 808 VDC328_4_2_IND_HSA_OFF "HSA OFF灯
";
CM_ SG_ 808 VDC328_4_3_IND_HDC "HDCﾗﾝﾌﾟ
";
CM_ SG_ 808 VDC328_4_5_WARNING_BRAKE_SYS "ブレーキシステムウォーニング
";
CM_ SG_ 808 VDC328_4_7_ACTIVE_OHB "OHB作動ﾌﾗｸﾞ
";
CM_ SG_ 808 VDC328_3_0_IND_WARN_EBD "EBDｳｫｰﾆﾝｸﾞ
";
CM_ SG_ 808 VDC328_3_1_IND_WARN_ABS "ABSｳｫｰﾆﾝｸﾞ
";
CM_ SG_ 808 VDC328_3_2_IND_WARN_VDC "VDCｳｫｰﾆﾝｸﾞ
";
CM_ SG_ 808 VDC328_3_3_IND_WARN_HSA "HSA警告灯(HSAｳｫｰﾆﾝｸﾞ)
";
CM_ SG_ 808 VDC328_3_4_WARN_BRAKEFLUID_LV "ﾌﾞﾚｰｷﾌﾙｰﾄﾞﾚﾍﾞﾙ警告灯
";
CM_ SG_ 808 VDC328_3_6_IND_TCS_OFF "TCS OFFランプ
";
CM_ SG_ 808 VDC328_3_7_EXIST_EPB "EPB設定情報
";
CM_ SG_ 808 VDC328_2_0_WARN_EBD_MET_LCD "ﾒｰﾀ内液晶用EBDｳｫｰﾆﾝｸﾞ
";
CM_ SG_ 808 VDC328_2_1_WARN_ABS_MET_LCD "ﾒｰﾀ内液晶用ABSｳｫｰﾆﾝｸﾞ
";
CM_ SG_ 808 VDC328_2_2_WARN_VDC_MET_LCD "ﾒｰﾀ内液晶用VDCｳｫｰﾆﾝｸﾞ
";
CM_ SG_ 808 VDC328_2_3_WARN_HSA_MET_LCD "ﾒｰﾀ内液晶用HSA警告灯(HSAｳｫｰﾆﾝｸﾞ)
";
CM_ SG_ 808 VDC328_2_4_EXIST_VECTARING "ﾍﾞｸﾀﾘﾝｸﾞ機能設定情報
";
CM_ SG_ 808 VDC328_1_0_MSG_COUNTER "ﾒｯｾｰｼﾞｶｳﾝﾀ
";
CM_ SG_ 808 VDC328_0_0_CHECK_SUM "ﾁｪｯｸｻﾑ
";
CM_ SG_ 316 VDC13C_7_0_RCV_FAIL_ADA "ADA FAIL　受信
";
CM_ SG_ 316 VDC13C_7_1_FAIL_PCU "PCU通信異常
";
CM_ SG_ 316 VDC13C_7_2_CONT_STATE_ES_BRAKE "ACCブレーキ制御状態
";
CM_ SG_ 316 VDC13C_7_3_ASST_PRECRUSH_ACC "ACCﾌﾟﾘｸﾗﾌﾞﾚｰｷｱｼｽﾄ作動ﾌﾗｸﾞ
";
CM_ SG_ 316 VDC13C_7_4_CONT_STATE_PRECRUSH "プリクラ制御状態
";
CM_ SG_ 316 VDC13C_7_5_PERMIT_BRAKE_ACC "ACCﾌﾞﾚｰｷ制御許可ﾌﾗｸﾞ
";
CM_ SG_ 316 VDC13C_7_6_DETECT_BRAKING "ﾄﾞﾗｲﾊﾞﾌﾞﾚｰｷ検出ﾌﾗｸﾞ
";
CM_ SG_ 316 VDC13C_7_7_EMERGENCY_BRAKE "緊急ﾌﾞﾚｰｷｼｸﾞﾅﾙ
";
CM_ SG_ 316 VDC13C_6_0_SPD_PULSE_INTEGRAL "車速ﾊﾟﾙｽ信号積算値（SP1P）
";
CM_ SG_ 316 VDC13C_6_6_VDC_OFF "VDC OFFﾌﾗｸﾞ
";
CM_ SG_ 316 VDC13C_6_7_STBY_PREVIEW_VDC "ﾌﾟﾚﾋﾞｭｰVDCｽﾀﾝﾊﾞｲﾌﾗｸﾞ
";
CM_ SG_ 316 VDC13C_5_0_SPD_PULSE_RRRH "右後輪車輪速ﾊﾟﾙｽ信号(生ﾊﾟﾙｽ値)
";
CM_ SG_ 316 VDC13C_5_7_ACTIVATE_TSM "TSM作動ﾌﾗｸﾞ
";
CM_ SG_ 316 VDC13C_4_0_SPD_PULSE_RRLH "左後輪車輪速ﾊﾟﾙｽ信号(生ﾊﾟﾙｽ値)
";
CM_ SG_ 316 VDC13C_4_7_ACTIVATE_RMI "RMI作動ﾌﾗｸﾞ
";
CM_ SG_ 316 VDC13C_3_0_SPD_PULSE_FTRH "右前輪車輪速ﾊﾟﾙｽ信号(生ﾊﾟﾙｽ値)
";
CM_ SG_ 316 VDC13C_3_7_ACTIVATE_VECTARING "ﾌﾞﾚｰｷﾍﾞｸﾀﾘﾝｸﾞ制御作動ﾌﾗｸﾞ
";
CM_ SG_ 316 VDC13C_2_0_SPD_PULSE_FTLH "左前輪車輪速ﾊﾟﾙｽ信号(生ﾊﾟﾙｽ値)
";
CM_ SG_ 316 VDC13C_2_7_STATE_ACTIVATE_HSA "HSA作動状態信号
";
CM_ SG_ 316 VDC13C_1_0_MSG_COUNTER "ﾒｯｾｰｼﾞｶｳﾝﾀ
";
CM_ SG_ 316 VDC13C_1_4_ACTIVE_BRAKEHOLD "ﾌﾞﾚｰｷﾎｰﾙﾄﾞ作動ﾌﾗｸﾞ
";
CM_ SG_ 316 VDC13C_1_5_PROHIBIT_BRAKEHOLD "ﾌﾞﾚｰｷﾎｰﾙﾄﾞ禁止ﾌﾗｸﾞ
";
CM_ SG_ 316 VDC13C_1_6_BRAKELAMP_RELAY "ﾌﾞﾚｰｷﾗﾝﾌﾟﾘﾚｰ駆動信号
";
CM_ SG_ 316 VDC13C_1_7_STATUS_BRAKELAMP "ﾌﾞﾚｰｷﾗﾝﾌﾟ状態ﾌﾗｸﾞ
";
CM_ SG_ 316 VDC13C_0_0_CHECK_SUM "ﾁｪｯｸｻﾑ
";
CM_ SG_ 315 VDC13B_7_0_ACCELERATE_F_R "前後Gｾﾝｻ値
";
CM_ SG_ 315 VDC13B_6_0_ACCELERATE_L_R "横加速度
";
CM_ SG_ 315 VDC13B_4_0_ENG_TRQ_DOWN "ｴﾝｼﾞﾝﾄﾙｸ減少要求値
";
CM_ SG_ 315 VDC13B_2_0_ENG_TRQ_UP "ｴﾝｼﾞﾝﾄﾙｸｱｯﾌﾟ要求値
";
CM_ SG_ 315 VDC13B_1_0_MSG_COUNTER "ﾒｯｾｰｼﾞｶｳﾝﾀ
";
CM_ SG_ 315 VDC13B_1_4_BRAKE_TYPE "ﾌﾞﾚｰｷｼｽﾃﾑﾌﾗｸﾞ
";
CM_ SG_ 315 VDC13B_1_5_REQ_ENG_TRQ_DOWN "ｴﾝｼﾞﾝﾄﾙｸ減少要求ﾌﾗｸﾞ
";
CM_ SG_ 315 VDC13B_1_6_REQ_ENG_TRQ_UP "ｴﾝｼﾞﾝﾄﾙｸｱｯﾌﾟ要求ﾌﾗｸﾞ
";
CM_ SG_ 315 VDC13B_1_7_PROHIBIT_FUEL_CUT "ﾌｭｰｴﾙｶｯﾄ禁止ﾌﾗｸﾞ
";
CM_ SG_ 315 VDC13B_0_0_CHECK_SUM "ﾁｪｯｸｻﾑ
";
CM_ SG_ 314 VDC13A_6_3_SPD_WHEEL_RRRH "右後輪車輪速
";
CM_ SG_ 314 VDC13A_4_6_SPD_WHEEL_RRLH "左後輪車輪速
";
CM_ SG_ 314 VDC13A_3_1_SPD_WHEEL_FTRH "右前輪車輪速
";
CM_ SG_ 314 VDC13A_1_4_SPD_WHEEL_FTLH "左前輪車輪速
";
CM_ SG_ 314 VDC13A_1_0_MSG_COUNTER "ﾒｯｾｰｼﾞｶｳﾝﾀ
";
CM_ SG_ 314 VDC13A_0_0_CHECK_SUM "ﾁｪｯｸｻﾑ
";
CM_ SG_ 313 VDC139_7_4_FAIL_PRESSURE_SSR "圧力ｾﾝｻ故障ﾌﾗｸﾞ
";
CM_ SG_ 313 VDC139_7_5_STATUS_EPB "EPB作動状態
";
CM_ SG_ 313 VDC139_6_0_SSR_N_PRESS "負圧ｾﾝｻ値
";
CM_ SG_ 313 VDC139_5_0_PRESSURE_BRAKE "ﾌﾞﾚｰｷ圧力
";
CM_ SG_ 313 VDC139_4_0_HDC_STATUS "HDC状態信号
";
CM_ SG_ 313 VDC139_4_2_BRAKELAMPSW "BLS信号
";
CM_ SG_ 313 VDC139_4_3_FAIL_BRAKELAMPSW "BLS故障信号
";
CM_ SG_ 313 VDC139_4_4_ACTIVATE_ABS "ABS作動ﾌﾗｸﾞ
";
CM_ SG_ 313 VDC139_4_5_ACTIVATE_TCS "TCS作動ﾌﾗｸﾞ
";
CM_ SG_ 313 VDC139_4_6_CONT_OVER_STR "VDCｵｰﾊﾞｰ制御ﾌﾗｸﾞ
";
CM_ SG_ 313 VDC139_4_7_CONT_UNDER_STR "VDCｱﾝﾀﾞｰ制御ﾌﾗｸﾞ
";
CM_ SG_ 313 VDC139_3_5_FAIL_VDC_SSR "VDCｾﾝｻﾌｪｰﾙﾌﾗｸﾞ
";
CM_ SG_ 313 VDC139_3_6_FAIL_SPD_SSR_FHI "ｽﾋﾟｰﾄﾞｾﾝｻﾌｪｰﾙﾌﾗｸﾞ（FHI）
";
CM_ SG_ 313 VDC139_3_7_FAIL_ABS_SYS "ABSｼｽﾃﾑﾌｪｰﾙﾌﾗｸﾞ
";
CM_ SG_ 313 VDC139_2_0_SPD_WHEEL_AVE "駆動輪軸平均車輪速（VSO）
";
CM_ SG_ 313 VDC139_1_0_MSG_COUNTER "ﾒｯｾｰｼﾞｶｳﾝﾀ
";
CM_ SG_ 313 VDC139_1_4_FAIL_HDC_SYS "HDCｼｽﾃﾑﾌｪｰﾙﾌﾗｸﾞ
";
CM_ SG_ 313 VDC139_1_5_VEHICLE_HIGHT "車高情報
";
CM_ SG_ 313 VDC139_1_7_REPROGRAMING "CAN診断・送信停止
";
CM_ SG_ 313 VDC139_0_0_CHECK_SUM "ﾁｪｯｸｻﾑ
";
CM_ SG_ 312 VDC138_7_0_PRESSURE_WC_FTLH "FL W/C実液圧
";
CM_ SG_ 312 VDC138_6_0_PRESSURE_WC_FTRH "FR W/C実液圧
";
CM_ SG_ 312 VDC138_4_0_YAW_RATE "ﾖｰﾚｰﾄ
";
CM_ SG_ 312 VDC138_2_0_STEER_ANGLE "舵角ｾﾝｻ
";
CM_ SG_ 312 VDC138_1_0_MSG_COUNTER "ﾒｯｾｰｼﾞｶｳﾝﾀ
";
CM_ SG_ 312 VDC138_1_4_ACTIVE_LDP "LDP作動ﾌﾗｸﾞ
";
CM_ SG_ 312 VDC138_1_5_PROHIBIT_LDP "LDP禁止ﾌﾗｸﾞ
";
CM_ SG_ 312 VDC138_1_6_VDC_SMALL_MARGIN "VDC介入余裕小ﾌﾗｸﾞ
";
CM_ SG_ 312 VDC138_1_7_DETECT_REAR_SLIP "ﾘｱｽﾘｯﾌﾟ検出ﾌﾗｸﾞ
";
CM_ SG_ 312 VDC138_0_0_CHECK_SUM "ﾁｪｯｸｻﾑ
";
CM_ SG_ 947 IPMS3B3_4_0_JUDGE_LEAN_FORWARD "異常姿勢突っ伏し判定
";
CM_ SG_ 947 IPMS3B3_4_1_JUDGE_LOOK_DOWN "異常姿勢うつむき判定
";
CM_ SG_ 947 IPMS3B3_4_2_JUDGE_LEAN_BACK "異常姿勢仰け反り判定
";
CM_ SG_ 947 IPMS3B3_4_3_JUDGE_BEND_BACKWARD "異常姿勢えび反り判定
";
CM_ SG_ 947 IPMS3B3_4_4_JUDGE_TILT_HEAD "異常姿勢首のみ横倒れ判定
";
CM_ SG_ 947 IPMS3B3_4_5_JUDGE_FALL_SIDEWAYS "異常姿勢横倒れ判定
";
CM_ SG_ 947 IPMS3B3_4_6_JUDGE_LEAN_AGAINST "異常姿勢横もたれ判定
";
CM_ SG_ 947 IPMS3B3_3_0_JUDGE_LOSING_POSTURE "異常姿勢状態フラグ
";
CM_ SG_ 947 IPMS3B3_3_1_JUDGE_SHORT_DIST "ショートディストラクション状態フラグ
";
CM_ SG_ 947 IPMS3B3_3_2_JUDGE_MICRO_SLEEP "マイクロスリープ状態フラグ
";
CM_ SG_ 947 IPMS3B3_2_0_E2E_COUNTER "E2Eカウンタ
";
CM_ SG_ 947 IPMS3B3_0_0_E2E_CRC "CRC
";
CM_ SG_ 946 IPMS3B2_5_0_STATUS_IMPAIR_DRV "ドライバー異常状態判定機能ON/OFF状態
";
CM_ SG_ 946 IPMS3B2_5_1_VALID_IMPAIR_DRV "ドライバー異常状態判定参照可否
";
CM_ SG_ 946 IPMS3B2_5_2_JUDGE_IMPAIR_DRV "ドライバー異常状態判定
";
CM_ SG_ 946 IPMS3B2_2_0_STATUS_DIST_FAT_WARN "脇見・居眠り警報機能ON/OFF状態
";
CM_ SG_ 946 IPMS3B2_1_0_MSG_COUNTER "メッセージカウンタ
";
CM_ SG_ 946 IPMS3B2_1_4_FAIL_IPMS "IPMS故障通知
";
CM_ SG_ 946 IPMS3B2_0_0_CHECK_SUM "チェックサム
";
CM_ SG_ 1709 CCU6AD_7_0_DMS_SET_REQ "DMS設定変更要求
";
CM_ SG_ 1709 CCU6AD_7_1_DP_POPUP_RES "ポップアップ操作結果
";
CM_ SG_ 1709 CCU6AD_6_3_EYE_MONI_BLUE_IND_SET "アイサイトモニター 青色インジケータ 設定値
";
CM_ SG_ 1709 CCU6AD_6_2_EYE_MONI_GRE_IND_SET "アイサイトモニター 緑色インジケータ 設定値
";
CM_ SG_ 1709 CCU6AD_6_1_EYE_MONI_YEL_IND_SET "アイサイトモニター 黄色インジケータ 設定値
";
CM_ SG_ 1709 CCU6AD_6_0_EYE_MONI_RED_IND_SET "アイサイトモニター 赤色インジケータ 設定値
";
CM_ SG_ 1709 CCU6AD_5_0_DP_OPERATION_FLAG "DriverProfile操作フラグ
";
CM_ SG_ 1709 CCU6AD_5_4_DP_OPERATION_NO "DriverProfile操作No
";
CM_ SG_ 1709 CCU6AD_4_7_DP_CCU_FAIL "DriverProfile_CCUフェールフラグ
";
CM_ SG_ 1709 CCU6AD_4_3_ALERT_BUZZ_REQ "警報音量ブザー吹鳴要求
";
CM_ SG_ 1709 CCU6AD_4_0_ALERT_VOL_LEVEL_SET "警報音量変更要求
";
CM_ SG_ 1709 CCU6AD_3_2_PREC_CAR_START_VOL "先行車発進お知らせ変更要求
";
CM_ SG_ 1709 CCU6AD_3_0_PREC_CAR_SIG_VOL_SET "先行車捕捉音変更要求
";
CM_ SG_ 1709 CCU6AD_2_3_MET_TEMP_UNIT_SET "外気温単位変更要求
";
CM_ SG_ 1709 CCU6AD_2_0_UNIT_SET "単位(BEV)変更要求
";
CM_ SG_ 1709 CCU6AD_1_0_MSG_COUNTER "メッセージカウンタ
";
CM_ SG_ 1709 CCU6AD_1_4_DP_DKY_OPERATION_NO "DKY操作No
";
CM_ SG_ 1709 CCU6AD_0_0_CHECK_SUM "チェックサム
";
CM_ SG_ 1706 CCU6AA_5_0_WINDOW_LOCK_SET_REQ "ウィンドウロック変更要求
";
CM_ SG_ 1706 CCU6AA_5_2_DOOR_LINK_SET_REQ "室内灯ドア連動変更要求
";
CM_ SG_ 1706 CCU6AA_5_4_BULK_TURN_ON_REQ "室内灯一括点灯変更要求
";
CM_ SG_ 1706 CCU6AA_5_6_WIPER_SERV_MODE_REQ "ワイパーサービスモード変更要求
";
CM_ SG_ 1706 CCU6AA_4_0_ITMITT_SENSITIVE_REQ "ワイパー感度変更要求
";
CM_ SG_ 1706 CCU6AA_4_4_REAR_WIPER_SET_REQ "リアワイパー変更要求
";
CM_ SG_ 1706 CCU6AA_4_7_SMT_CSTM_RESET_REQ "SMTカスタマイズリセット要求
";
CM_ SG_ 1706 CCU6AA_3_0_WELCOME_RIDEON_REQ "ウェルカムランプ乗車時作動時間変更要求
";
CM_ SG_ 1706 CCU6AA_3_3_WELCOME_GETOFF_REQ "ウェルカムランプ降車時作動時間変更要求
";
CM_ SG_ 1706 CCU6AA_2_0_WIPER_HEADLAMP_REQ "ワイパー連動ヘッドランプ変更要求
";
CM_ SG_ 1706 CCU6AA_1_0_MSG_COUNTER "メッセージカウンタ
";
CM_ SG_ 1706 CCU6AA_1_4_WIUL_CUSTOM_REQ "WIUL変更要求
";
CM_ SG_ 1706 CCU6AA_1_6_WAL_CUSTOM_REQ "WAL変更要求
";
CM_ SG_ 1706 CCU6AA_0_0_CHECK_SUM "チェックサム
";
CM_ SG_ 1704 CCU6A8_7_5_TRQ_CHG_MODE_SET "トルク変動モード変更要求
";
CM_ SG_ 1704 CCU6A8_7_3_ADAPT_DEC_CHG_REQ "Adaptive変更要求
";
CM_ SG_ 1704 CCU6A8_7_0_DEC_SELECT_REQ_B "減速度セレクト変更要求_B
";
CM_ SG_ 1704 CCU6A8_6_5_DEC_SELECT_REQ_D "減速度セレクト変更要求_D
";
CM_ SG_ 1704 CCU6A8_6_2_DEC_SELECT_REQ_ALL "減速度セレクト変更要求_ALL
";
CM_ SG_ 1704 CCU6A8_6_0_DEC_SELECT_REQ_IND "減速度セレクト変更要求_Individual
";
CM_ SG_ 1704 CCU6A8_5_2_TOWING_MODE_REQ "トーイングモード変更要求
";
CM_ SG_ 1704 CCU6A8_5_0_FACTORY_MODE_STATE "工場状態モード
";
CM_ SG_ 1704 CCU6A8_4_2_TRIP_RESET_REQ "トリップリセット要求
";
CM_ SG_ 1704 CCU6A8_4_0_TRIP_SWITCH_REQ "トリップ切替要求
";
CM_ SG_ 1704 CCU6A8_3_0_DOW_SFT_POS_SET "DOW有効シフトポジション設定値
";
CM_ SG_ 1704 CCU6A8_2_6_DOW_SET "DOW設定値
";
CM_ SG_ 1704 CCU6A8_2_4_RCTA_SET "RCTA設定値
";
CM_ SG_ 1704 CCU6A8_2_2_BSD_LCA_2ND_SET "BSD/LCA2次警報音カスタマイズ設定値
";
CM_ SG_ 1704 CCU6A8_2_0_SRVD_SET "SRVD設定値
";
CM_ SG_ 1704 CCU6A8_1_6_RCR_CSTM_RESET_REQ "RCRカスタマイズリセット要求
";
CM_ SG_ 1704 CCU6A8_1_4_BEV_CSTM_RESET_REQ "BEVカスタマイズリセット要求
";
CM_ SG_ 1704 CCU6A8_1_0_MSG_COUNTER "メッセージカウンタ
";
CM_ SG_ 1704 CCU6A8_0_0_CHECK_SUM "チェックサム
";
CM_ SG_ 1149 CCU47D_3_0_AA_EST_CHG_TIME "AA 推定充電時間
";
CM_ SG_ 1149 CCU47D_2_0_E2E_COUNTER "E2Eカウンタ
";
CM_ SG_ 1149 CCU47D_0_0_E2E_CRC "CRC
";
CM_ SG_ 1148 CCU47C_7_0_AA_CRG_MAX_OUT_WAT "AA　充電時最大定格出力
";
CM_ SG_ 1148 CCU47C_3_0_AA_DEP_MIN_BAT_LEVEL "AA　出発時必要最小バッテリー量
";
CM_ SG_ 1148 CCU47C_2_0_E2E_COUNTER "E2Eカウンタ
";
CM_ SG_ 1148 CCU47C_0_0_E2E_CRC "CRC
";
CM_ SG_ 1144 CCU478_25_0_LAT_CHG_WEEK_DAYS "直近タイマー充電曜日
";
CM_ SG_ 1144 CCU478_24_3_Reserved "RESERVED
";
CM_ SG_ 1144 CCU478_23_0_LAT_CHG_END_TIME "直近タイマー充電終了時刻
";
CM_ SG_ 1144 CCU478_22_5_Reserved "RESERVED
";
CM_ SG_ 1144 CCU478_21_2_LAT_CHG_START_TIME "直近タイマー充電開始時刻
";
CM_ SG_ 1144 CCU478_21_0_LAT_CHG_SET_TYPE "直近タイマー充電設定タイプ
";
CM_ SG_ 1144 CCU478_20_6_Reserved "RESERVED
";
CM_ SG_ 1144 CCU478_20_2_TIRE_SIZE "タイヤサイズ
";
CM_ SG_ 1144 CCU478_20_0_TIRE_TYPE "タイヤ種別
";
CM_ SG_ 1144 CCU478_19_4_Reserved "RESERVED
";
CM_ SG_ 1144 CCU478_19_2_SW_PFO_MOD_CHG "パフォーマンスモード要求
";
CM_ SG_ 1144 CCU478_19_0_DEP_TIM_CHG_FLG "出発時刻プレコン設定変更フラグ
";
CM_ SG_ 1144 CCU478_18_0_DEP_TIM4_WEEK_DAYS "出発時刻プレコンID4曜日
";
CM_ SG_ 1144 CCU478_17_3_Reserved "RESERVED
";
CM_ SG_ 1144 CCU478_16_0_DEP_TIM4_START_TIME "出発時刻プレコンID4開始時刻
";
CM_ SG_ 1144 CCU478_15_7_DEP_TIM4_PER_FLG "出発時刻プレコンID4パフォーマンスモードフラグ
";
CM_ SG_ 1144 CCU478_15_5_DEP_TIM4_SW_STS "出発時刻プレコンID4オン・オフ状態
";
CM_ SG_ 1144 CCU478_15_0_TIM4_DISP_ID "出発時刻プレコンID4の表示順番ID
";
CM_ SG_ 1144 CCU478_14_0_DEP_TIM3_WEEK_DAYS "出発時刻プレコンID3曜日
";
CM_ SG_ 1144 CCU478_13_3_Reserved "RESERVED
";
CM_ SG_ 1144 CCU478_12_0_DEP_TIM3_START_TIME "出発時刻プレコンID3開始時刻
";
CM_ SG_ 1144 CCU478_11_7_DEP_TIM3_PER_FLG "出発時刻プレコンID3パフォーマンスモードフラグ
";
CM_ SG_ 1144 CCU478_11_5_DEP_TIM3_SW_STS "出発時刻プレコンID3オン・オフ状態
";
CM_ SG_ 1144 CCU478_11_0_TIM3_DISP_ID "出発時刻プレコンID3の表示順番ID
";
CM_ SG_ 1144 CCU478_10_0_DEP_TIM2_WEEK_DAYS "出発時刻プレコンID2曜日
";
CM_ SG_ 1144 CCU478_9_3_Reserved "RESERVED
";
CM_ SG_ 1144 CCU478_8_0_DEP_TIM2_START_TIME "出発時刻プレコンID2開始時刻
";
CM_ SG_ 1144 CCU478_7_7_DEP_TIM2_PER_FLG "出発時刻プレコンID2パフォーマンスモードフラグ
";
CM_ SG_ 1144 CCU478_7_5_DEP_TIM2_SW_STS "出発時刻プレコンID2オン・オフ状態
";
CM_ SG_ 1144 CCU478_7_0_TIM2_DISP_ID "出発時刻プレコンID2の表示順番ID
";
CM_ SG_ 1144 CCU478_6_0_DEP_TIM1_WEEK_DAYS "出発時刻プレコンID1曜日
";
CM_ SG_ 1144 CCU478_5_3_Reserved "RESERVED
";
CM_ SG_ 1144 CCU478_4_0_DEP_TIM1_START_TIME "出発時刻プレコンID1開始時刻
";
CM_ SG_ 1144 CCU478_3_7_DEP_TIM1_PER_FLG "出発時刻プレコンID1パフォーマンスモードフラグ
";
CM_ SG_ 1144 CCU478_3_5_DEP_TIM1_SW_STS "出発時刻プレコンID1オン・オフ状態
";
CM_ SG_ 1144 CCU478_3_0_TIM1_DISP_ID "出発時刻プレコンID1の表示順番ID
";
CM_ SG_ 1144 CCU478_2_0_E2E_COUNTER "E2Eカウンタ
";
CM_ SG_ 1144 CCU478_0_0_E2E_CRC "CRC
";
CM_ SG_ 1105 CCU451_31_0_BYTE26 "開発用変数26
";
CM_ SG_ 1105 CCU451_30_0_BYTE25 "開発用変数25
";
CM_ SG_ 1105 CCU451_29_0_BYTE24 "開発用変数24
";
CM_ SG_ 1105 CCU451_28_0_BYTE23 "開発用変数23
";
CM_ SG_ 1105 CCU451_27_0_BYTE22 "開発用変数22
";
CM_ SG_ 1105 CCU451_26_0_BYTE21 "開発用変数21
";
CM_ SG_ 1105 CCU451_25_0_BYTE20 "開発用変数20
";
CM_ SG_ 1105 CCU451_24_0_BYTE19 "開発用変数19
";
CM_ SG_ 1105 CCU451_23_0_BYTE18 "開発用変数18
";
CM_ SG_ 1105 CCU451_22_0_BYTE17 "開発用変数17
";
CM_ SG_ 1105 CCU451_21_0_BYTE16 "開発用変数16
";
CM_ SG_ 1105 CCU451_20_0_BYTE15 "開発用変数15
";
CM_ SG_ 1105 CCU451_19_0_BYTE14 "開発用変数14
";
CM_ SG_ 1105 CCU451_18_0_BYTE13 "開発用変数13
";
CM_ SG_ 1105 CCU451_17_0_BYTE12 "開発用変数12
";
CM_ SG_ 1105 CCU451_16_0_BYTE11 "開発用変数11
";
CM_ SG_ 1105 CCU451_15_0_BYTE10 "開発用変数10
";
CM_ SG_ 1105 CCU451_14_0_BYTE9 "開発用変数9
";
CM_ SG_ 1105 CCU451_13_0_BYTE8 "開発用変数8
";
CM_ SG_ 1105 CCU451_12_0_BYTE7 "開発用変数7
";
CM_ SG_ 1105 CCU451_11_0_BYTE6 "開発用変数6
";
CM_ SG_ 1105 CCU451_10_0_BYTE5 "開発用変数5
";
CM_ SG_ 1105 CCU451_9_0_BYTE4 "開発用変数4
";
CM_ SG_ 1105 CCU451_8_0_CHG_BTN_FLG_CCU "充電ボタン表示フラグ_CCU
";
CM_ SG_ 1105 CCU451_8_3_CHG_CNG_FLG_CCU "充電ボタン変化フラグ_CCU
";
CM_ SG_ 1105 CCU451_8_4_Reserved "RESERVED
";
CM_ SG_ 1105 CCU451_7_3_Reserved "RESERVED
";
CM_ SG_ 1105 CCU451_6_0_CHG_COMTI "充電完了時間_CCU
";
CM_ SG_ 1105 CCU451_5_0_SW_RIGHT_NOW_PRE_CON "即時プレコンSW情報
";
CM_ SG_ 1105 CCU451_5_2_Reserved "RESERVED
";
CM_ SG_ 1105 CCU451_4_1_CHG_HILMT_REQ "充電量上限設定要求値_CCU
";
CM_ SG_ 1105 CCU451_4_0_CHG_STP_REQ "充電停止要求_CCU
";
CM_ SG_ 1105 CCU451_3_4_DCCHG_PWRUPLMT "DC充電電力上限設定値_CCU
";
CM_ SG_ 1105 CCU451_3_0_ACCHG_CORUPLMT "AC充電電流上限設定値_CCU
";
CM_ SG_ 1105 CCU451_2_0_E2E_COUNTER "E2Eカウンタ
";
CM_ SG_ 1105 CCU451_0_0_E2E_CRC "CRC
";
CM_ SG_ 1726 CCU6BE_10_0_CCU_BOOT_STATE "CCU起動状態
";
CM_ SG_ 1726 CCU6BE_9_0_DISP_DRAINAGE "排水制御要求
";
CM_ SG_ 1726 CCU6BE_8_0_DISP_POURING_WATER "注水制御要求
";
CM_ SG_ 1726 CCU6BE_7_4_QDK_DEV "利用者認証デバイス_CID制御
";
CM_ SG_ 1726 CCU6BE_5_0_SLOTID_ERASE "消去対象デバイスSlotID
";
CM_ SG_ 1726 CCU6BE_4_2_QDK_OSWAP "オーナー用デジタルキー機種交換要求_CID制御
";
CM_ SG_ 1726 CCU6BE_4_4_QDK_FDRQ "フレンド用デジタルキー消去要求_CID制御
";
CM_ SG_ 1726 CCU6BE_4_6_QDK_OWCQ "利用者認証要求_CID制御
";
CM_ SG_ 1726 CCU6BE_3_0_QDK_ORRQ "オーナ用デジタルキー登録事前要求_CID制御
";
CM_ SG_ 1726 CCU6BE_3_2_QDK_OGRQ "オーナーデバイス登録処理ステータス確認要求_CID制御
";
CM_ SG_ 1726 CCU6BE_3_4_QDK_ODRQ "オーナ用デジタルキー消去要求_CID制御
";
CM_ SG_ 1726 CCU6BE_3_6_QDK_ADLQ "デジタルキー全キー消去要求_CID制御
";
CM_ SG_ 1726 CCU6BE_2_0_E2E_COUNTER "E2Eカウンタ
";
CM_ SG_ 1726 CCU6BE_0_0_CRC "CRC
";
CM_ SG_ 1312 IAVAS520_1_4_ActiveWakeUpBit "Active Wakeup ﾌﾗｸﾞ
";
CM_ SG_ 1312 IAVAS520_0_0_SourceNodeID "送信元ID
";
CM_ SG_ 989 IAVAS3DD_2_0_SP_STATUS "スピーカ状態
";
CM_ SG_ 989 IAVAS3DD_1_0_MSG_COUNTER "ﾒｯｾｰｼﾞｶｳﾝﾀ
";
CM_ SG_ 989 IAVAS3DD_0_0_CHECK_SUM "ﾁｪｯｸｻﾑ
";
BA_DEF_ SG_  "Fhi_SignalComment" STRING ;
BA_DEF_ SG_  "GenSigInactiveValue" INT 0 10000;
BA_DEF_ SG_  "GenSigStartValue" FLOAT 0 100000000000;
BA_DEF_ SG_  "GenSigSendType" ENUM  "Cyclic","OnWrite","OnWriteWithRepetition","OnChange","OnChangeWithRepetition","IfActive","IfActiveWithRepetition","NoSigSendType";
BA_DEF_ BO_  "MsgRoutingId" STRING ;
BA_DEF_ BO_  "DiagResponse" ENUM  "No","Yes";
BA_DEF_ BO_  "DiagRequest" ENUM  "No","Yes";
BA_DEF_ BO_  "DiagState" ENUM  "No","Yes";
BA_DEF_ BO_  "GenMsgILSupport" ENUM  "No","Yes";
BA_DEF_ BO_  "GenMsgNrOfRepetition" INT 0 999999;
BA_DEF_ BO_  "GenMsgDelayTime" INT 0 1000;
BA_DEF_ BO_  "GenMsgCycleTimeFast" INT 0 10000;
BA_DEF_ BO_  "GenMsgCycleTime" INT 0 10000;
BA_DEF_ BO_  "GenMsgSendType" ENUM  "Cyclic","NotUsed","NotUsed","NotUsed","NotUsed","Cyclic","NotUsed","IfActive","NoMsgSendType";
BA_DEF_ BO_  "CANFD_BRS" ENUM  "0","1";
BA_DEF_ BO_  "VFrameFormat" ENUM  "StandardCAN","ExtendedCAN","reserved","reserved","reserved","reserved","reserved","reserved","reserved","reserved","reserved","reserved","reserved","reserved","StandardCAN_FD","ExtendedCAN_FD";
BA_DEF_DEF_  "Fhi_SignalComment" "";
BA_DEF_DEF_  "GenSigInactiveValue" 0;
BA_DEF_DEF_  "GenSigStartValue" 0;
BA_DEF_DEF_  "GenSigSendType" "NoSigSendType";
BA_DEF_DEF_  "MsgRoutingId" "";
BA_DEF_DEF_  "DiagResponse" "No";
BA_DEF_DEF_  "DiagRequest" "No";
BA_DEF_DEF_  "DiagState" "No";
BA_DEF_DEF_  "GenMsgILSupport" "Yes";
BA_DEF_DEF_  "GenMsgNrOfRepetition" 0;
BA_DEF_DEF_  "GenMsgDelayTime" 0;
BA_DEF_DEF_  "GenMsgCycleTimeFast" 0;
BA_DEF_DEF_  "GenMsgCycleTime" 0;
BA_DEF_DEF_  "GenMsgSendType" "Cyclic";
BA_DEF_DEF_  "CANFD_BRS" "1";
BA_DEF_DEF_  "VFrameFormat" "StandardCAN";
BA_ "GenMsgCycleTime" BO_ 1654 1000;
BA_ "GenMsgDelayTime" BO_ 1654 10;
BA_ "GenMsgCycleTimeFast" BO_ 1654 20;
BA_ "GenMsgNrOfRepetition" BO_ 1654 3;
BA_ "MsgRoutingId" BO_ 1654 "80 ";
BA_ "GenMsgILSupport" BO_ 1654 0;
BA_ "VFrameFormat" BO_ 1654 14;
BA_ "GenMsgCycleTime" BO_ 1652 1000;
BA_ "GenMsgDelayTime" BO_ 1652 10;
BA_ "GenMsgCycleTimeFast" BO_ 1652 20;
BA_ "GenMsgNrOfRepetition" BO_ 1652 3;
BA_ "MsgRoutingId" BO_ 1652 "79 ";
BA_ "GenMsgILSupport" BO_ 1652 0;
BA_ "VFrameFormat" BO_ 1652 14;
BA_ "GenMsgCycleTime" BO_ 948 100;
BA_ "GenMsgDelayTime" BO_ 948 10;
BA_ "MsgRoutingId" BO_ 948 "78 ";
BA_ "GenMsgILSupport" BO_ 948 0;
BA_ "VFrameFormat" BO_ 948 14;
BA_ "GenMsgCycleTime" BO_ 1725 1200;
BA_ "GenMsgDelayTime" BO_ 1725 10;
BA_ "GenMsgCycleTimeFast" BO_ 1725 50;
BA_ "GenMsgNrOfRepetition" BO_ 1725 4;
BA_ "MsgRoutingId" BO_ 1725 "74 ";
BA_ "GenMsgILSupport" BO_ 1725 0;
BA_ "VFrameFormat" BO_ 1725 14;
BA_ "GenMsgCycleTime" BO_ 1724 1200;
BA_ "GenMsgDelayTime" BO_ 1724 200;
BA_ "GenMsgCycleTimeFast" BO_ 1724 1000;
BA_ "GenMsgNrOfRepetition" BO_ 1724 1;
BA_ "MsgRoutingId" BO_ 1724 "73 ";
BA_ "GenMsgILSupport" BO_ 1724 0;
BA_ "VFrameFormat" BO_ 1724 14;
BA_ "GenMsgCycleTime" BO_ 1723 1200;
BA_ "GenMsgDelayTime" BO_ 1723 10;
BA_ "GenMsgCycleTimeFast" BO_ 1723 50;
BA_ "GenMsgNrOfRepetition" BO_ 1723 4;
BA_ "MsgRoutingId" BO_ 1723 "72 ";
BA_ "GenMsgILSupport" BO_ 1723 0;
BA_ "VFrameFormat" BO_ 1723 14;
BA_ "GenMsgCycleTime" BO_ 1713 1200;
BA_ "GenMsgDelayTime" BO_ 1713 10;
BA_ "GenMsgCycleTimeFast" BO_ 1713 20;
BA_ "GenMsgNrOfRepetition" BO_ 1713 1;
BA_ "MsgRoutingId" BO_ 1713 "70 ";
BA_ "GenMsgILSupport" BO_ 1713 0;
BA_ "VFrameFormat" BO_ 1713 14;
BA_ "GenMsgCycleTime" BO_ 1019 500;
BA_ "GenMsgDelayTime" BO_ 1019 10;
BA_ "GenMsgCycleTimeFast" BO_ 1019 20;
BA_ "GenMsgNrOfRepetition" BO_ 1019 3;
BA_ "MsgRoutingId" BO_ 1019 "69 ";
BA_ "GenMsgILSupport" BO_ 1019 0;
BA_ "VFrameFormat" BO_ 1019 14;
BA_ "GenMsgCycleTime" BO_ 818 120;
BA_ "GenMsgDelayTime" BO_ 818 10;
BA_ "GenMsgNrOfRepetition" BO_ 818 1;
BA_ "MsgRoutingId" BO_ 818 "61 ";
BA_ "GenMsgILSupport" BO_ 818 0;
BA_ "VFrameFormat" BO_ 818 14;
BA_ "GenMsgCycleTime" BO_ 1622 1000;
BA_ "GenMsgDelayTime" BO_ 1622 10;
BA_ "GenMsgCycleTimeFast" BO_ 1622 20;
BA_ "GenMsgNrOfRepetition" BO_ 1622 10;
BA_ "MsgRoutingId" BO_ 1622 "56 ";
BA_ "GenMsgILSupport" BO_ 1622 0;
BA_ "VFrameFormat" BO_ 1622 14;
BA_ "GenMsgCycleTime" BO_ 1621 1000;
BA_ "GenMsgDelayTime" BO_ 1621 10;
BA_ "GenMsgCycleTimeFast" BO_ 1621 20;
BA_ "GenMsgNrOfRepetition" BO_ 1621 10;
BA_ "MsgRoutingId" BO_ 1621 "55 ";
BA_ "GenMsgILSupport" BO_ 1621 0;
BA_ "VFrameFormat" BO_ 1621 14;
BA_ "GenMsgCycleTime" BO_ 1618 1200;
BA_ "GenMsgDelayTime" BO_ 1618 10;
BA_ "MsgRoutingId" BO_ 1618 "53 ";
BA_ "GenMsgILSupport" BO_ 1618 0;
BA_ "VFrameFormat" BO_ 1618 14;
BA_ "GenMsgCycleTime" BO_ 1617 1200;
BA_ "GenMsgDelayTime" BO_ 1617 10;
BA_ "MsgRoutingId" BO_ 1617 "52 ";
BA_ "GenMsgILSupport" BO_ 1617 0;
BA_ "VFrameFormat" BO_ 1617 14;
BA_ "GenMsgCycleTime" BO_ 942 100;
BA_ "GenMsgDelayTime" BO_ 942 10;
BA_ "GenMsgCycleTimeFast" BO_ 942 20;
BA_ "GenMsgNrOfRepetition" BO_ 942 2;
BA_ "MsgRoutingId" BO_ 942 "50 ";
BA_ "GenMsgILSupport" BO_ 942 0;
BA_ "VFrameFormat" BO_ 942 14;
BA_ "GenMsgCycleTime" BO_ 940 100;
BA_ "GenMsgDelayTime" BO_ 940 10;
BA_ "GenMsgCycleTimeFast" BO_ 940 20;
BA_ "GenMsgNrOfRepetition" BO_ 940 10;
BA_ "MsgRoutingId" BO_ 940 "49 ";
BA_ "GenMsgILSupport" BO_ 940 0;
BA_ "VFrameFormat" BO_ 940 14;
BA_ "GenMsgCycleTime" BO_ 960 100;
BA_ "GenMsgDelayTime" BO_ 960 10;
BA_ "GenMsgCycleTimeFast" BO_ 960 20;
BA_ "GenMsgNrOfRepetition" BO_ 960 10;
BA_ "MsgRoutingId" BO_ 960 "48 ";
BA_ "GenMsgILSupport" BO_ 960 0;
BA_ "VFrameFormat" BO_ 960 14;
BA_ "GenMsgCycleTime" BO_ 1616 1000;
BA_ "GenMsgDelayTime" BO_ 1616 10;
BA_ "GenMsgCycleTimeFast" BO_ 1616 20;
BA_ "GenMsgNrOfRepetition" BO_ 1616 10;
BA_ "MsgRoutingId" BO_ 1616 "47 ";
BA_ "GenMsgILSupport" BO_ 1616 0;
BA_ "VFrameFormat" BO_ 1616 14;
BA_ "GenMsgCycleTime" BO_ 1615 1000;
BA_ "GenMsgDelayTime" BO_ 1615 10;
BA_ "GenMsgCycleTimeFast" BO_ 1615 20;
BA_ "GenMsgNrOfRepetition" BO_ 1615 10;
BA_ "MsgRoutingId" BO_ 1615 "46 ";
BA_ "GenMsgILSupport" BO_ 1615 0;
BA_ "VFrameFormat" BO_ 1615 14;
BA_ "GenMsgCycleTime" BO_ 305 20;
BA_ "MsgRoutingId" BO_ 305 "45 ";
BA_ "VFrameFormat" BO_ 305 14;
BA_ "GenMsgCycleTime" BO_ 1350 1000;
BA_ "VFrameFormat" BO_ 1350 14;
BA_ "GenMsgCycleTime" BO_ 798 100;
BA_ "VFrameFormat" BO_ 798 14;
BA_ "GenMsgCycleTime" BO_ 799 100;
BA_ "VFrameFormat" BO_ 799 14;
BA_ "GenMsgCycleTime" BO_ 345 20;
BA_ "VFrameFormat" BO_ 345 14;
BA_ "GenMsgCycleTime" BO_ 59 10;
BA_ "VFrameFormat" BO_ 59 14;
BA_ "GenMsgCycleTime" BO_ 809 100;
BA_ "GenMsgDelayTime" BO_ 809 20;
BA_ "GenMsgCycleTimeFast" BO_ 809 20;
BA_ "GenMsgNrOfRepetition" BO_ 809 3;
BA_ "MsgRoutingId" BO_ 809 "41 ";
BA_ "VFrameFormat" BO_ 809 14;
BA_ "GenMsgCycleTime" BO_ 319 20;
BA_ "VFrameFormat" BO_ 319 14;
BA_ "GenMsgCycleTime" BO_ 58 10;
BA_ "VFrameFormat" BO_ 58 14;
BA_ "GenMsgCycleTime" BO_ 1282 1000;
BA_ "VFrameFormat" BO_ 1282 14;
BA_ "GenMsgCycleTime" BO_ 811 100;
BA_ "GenMsgDelayTime" BO_ 811 10;
BA_ "MsgRoutingId" BO_ 811 "40 ";
BA_ "VFrameFormat" BO_ 811 14;
BA_ "GenMsgCycleTime" BO_ 1281 1000;
BA_ "VFrameFormat" BO_ 1281 14;
BA_ "GenMsgCycleTime" BO_ 57 10;
BA_ "VFrameFormat" BO_ 57 14;
BA_ "GenMsgCycleTime" BO_ 323 20;
BA_ "MsgRoutingId" BO_ 323 "39 ";
BA_ "VFrameFormat" BO_ 323 14;
BA_ "GenMsgCycleTime" BO_ 56 10;
BA_ "VFrameFormat" BO_ 56 14;
BA_ "GenMsgCycleTime" BO_ 362 20;
BA_ "MsgRoutingId" BO_ 362 "38 ";
BA_ "VFrameFormat" BO_ 362 14;
BA_ "GenMsgCycleTime" BO_ 808 100;
BA_ "GenMsgDelayTime" BO_ 808 10;
BA_ "MsgRoutingId" BO_ 808 "37 ";
BA_ "VFrameFormat" BO_ 808 14;
BA_ "GenMsgCycleTime" BO_ 316 20;
BA_ "MsgRoutingId" BO_ 316 "36 ";
BA_ "VFrameFormat" BO_ 316 14;
BA_ "GenMsgCycleTime" BO_ 315 20;
BA_ "MsgRoutingId" BO_ 315 "35 ";
BA_ "VFrameFormat" BO_ 315 14;
BA_ "GenMsgCycleTime" BO_ 314 20;
BA_ "MsgRoutingId" BO_ 314 "34 ";
BA_ "VFrameFormat" BO_ 314 14;
BA_ "GenMsgCycleTime" BO_ 313 20;
BA_ "MsgRoutingId" BO_ 313 "33 ";
BA_ "VFrameFormat" BO_ 313 14;
BA_ "GenMsgCycleTime" BO_ 312 20;
BA_ "MsgRoutingId" BO_ 312 "32 ";
BA_ "VFrameFormat" BO_ 312 14;
BA_ "GenMsgCycleTime" BO_ 309 20;
BA_ "VFrameFormat" BO_ 309 14;
BA_ "GenMsgCycleTime" BO_ 308 20;
BA_ "VFrameFormat" BO_ 308 14;
BA_ "GenMsgCycleTime" BO_ 503 33;
BA_ "GenMsgCycleTimeFast" BO_ 503 33;
BA_ "GenMsgNrOfRepetition" BO_ 503 10;
BA_ "VFrameFormat" BO_ 503 14;
BA_ "GenMsgCycleTime" BO_ 502 33;
BA_ "GenMsgCycleTimeFast" BO_ 502 33;
BA_ "GenMsgNrOfRepetition" BO_ 502 10;
BA_ "VFrameFormat" BO_ 502 14;
BA_ "GenMsgCycleTime" BO_ 501 33;
BA_ "GenMsgCycleTimeFast" BO_ 501 33;
BA_ "GenMsgNrOfRepetition" BO_ 501 10;
BA_ "VFrameFormat" BO_ 501 14;
BA_ "GenMsgCycleTime" BO_ 500 33;
BA_ "GenMsgCycleTimeFast" BO_ 500 33;
BA_ "GenMsgNrOfRepetition" BO_ 500 10;
BA_ "VFrameFormat" BO_ 500 14;
BA_ "GenMsgCycleTime" BO_ 947 120;
BA_ "GenMsgCycleTimeFast" BO_ 947 50;
BA_ "GenMsgNrOfRepetition" BO_ 947 3;
BA_ "MsgRoutingId" BO_ 947 "31 ";
BA_ "VFrameFormat" BO_ 947 14;
BA_ "GenMsgCycleTime" BO_ 946 120;
BA_ "GenMsgCycleTimeFast" BO_ 946 50;
BA_ "GenMsgNrOfRepetition" BO_ 946 3;
BA_ "MsgRoutingId" BO_ 946 "30 ";
BA_ "VFrameFormat" BO_ 946 14;
BA_ "GenMsgCycleTime" BO_ 1709 1200;
BA_ "GenMsgDelayTime" BO_ 1709 10;
BA_ "GenMsgCycleTimeFast" BO_ 1709 50;
BA_ "GenMsgNrOfRepetition" BO_ 1709 4;
BA_ "MsgRoutingId" BO_ 1709 "25 ";
BA_ "GenMsgILSupport" BO_ 1709 0;
BA_ "VFrameFormat" BO_ 1709 14;
BA_ "GenMsgCycleTime" BO_ 1706 1200;
BA_ "GenMsgDelayTime" BO_ 1706 10;
BA_ "GenMsgCycleTimeFast" BO_ 1706 50;
BA_ "GenMsgNrOfRepetition" BO_ 1706 4;
BA_ "MsgRoutingId" BO_ 1706 "22 ";
BA_ "GenMsgILSupport" BO_ 1706 0;
BA_ "VFrameFormat" BO_ 1706 14;
BA_ "GenMsgCycleTime" BO_ 1704 1200;
BA_ "GenMsgDelayTime" BO_ 1704 10;
BA_ "GenMsgCycleTimeFast" BO_ 1704 50;
BA_ "GenMsgNrOfRepetition" BO_ 1704 4;
BA_ "MsgRoutingId" BO_ 1704 "21 ";
BA_ "GenMsgILSupport" BO_ 1704 0;
BA_ "VFrameFormat" BO_ 1704 14;
BA_ "GenMsgCycleTime" BO_ 1149 1200;
BA_ "GenMsgDelayTime" BO_ 1149 10;
BA_ "GenMsgCycleTimeFast" BO_ 1149 50;
BA_ "GenMsgNrOfRepetition" BO_ 1149 4;
BA_ "MsgRoutingId" BO_ 1149 "20 ";
BA_ "GenMsgILSupport" BO_ 1149 0;
BA_ "VFrameFormat" BO_ 1149 14;
BA_ "GenMsgCycleTime" BO_ 1148 1200;
BA_ "GenMsgDelayTime" BO_ 1148 10;
BA_ "GenMsgCycleTimeFast" BO_ 1148 50;
BA_ "GenMsgNrOfRepetition" BO_ 1148 4;
BA_ "MsgRoutingId" BO_ 1148 "19 ";
BA_ "GenMsgILSupport" BO_ 1148 0;
BA_ "VFrameFormat" BO_ 1148 14;
BA_ "GenMsgCycleTime" BO_ 1144 1000;
BA_ "GenMsgCycleTimeFast" BO_ 1144 20;
BA_ "GenMsgNrOfRepetition" BO_ 1144 3;
BA_ "MsgRoutingId" BO_ 1144 "16 ";
BA_ "GenMsgILSupport" BO_ 1144 0;
BA_ "VFrameFormat" BO_ 1144 14;
BA_ "GenMsgCycleTime" BO_ 927 300;
BA_ "GenMsgDelayTime" BO_ 927 10;
BA_ "GenMsgNrOfRepetition" BO_ 927 1;
BA_ "MsgRoutingId" BO_ 927 "12 ";
BA_ "GenMsgILSupport" BO_ 927 0;
BA_ "VFrameFormat" BO_ 927 14;
BA_ "GenMsgCycleTime" BO_ 1105 1000;
BA_ "GenMsgCycleTimeFast" BO_ 1105 20;
BA_ "GenMsgNrOfRepetition" BO_ 1105 3;
BA_ "MsgRoutingId" BO_ 1105 "10 ";
BA_ "GenMsgILSupport" BO_ 1105 0;
BA_ "VFrameFormat" BO_ 1105 14;
BA_ "GenMsgCycleTime" BO_ 1726 1000;
BA_ "GenMsgDelayTime" BO_ 1726 10;
BA_ "GenMsgNrOfRepetition" BO_ 1726 1;
BA_ "MsgRoutingId" BO_ 1726 "8 ";
BA_ "GenMsgILSupport" BO_ 1726 0;
BA_ "VFrameFormat" BO_ 1726 14;
BA_ "GenMsgCycleTime" BO_ 1312 1000;
BA_ "VFrameFormat" BO_ 1312 14;
BA_ "GenMsgCycleTime" BO_ 989 200;
BA_ "MsgRoutingId" BO_ 989 "1 ";
BA_ "VFrameFormat" BO_ 989 14;
BA_ "GenSigStartValue" SG_ 948 ACN3B4_2_0_AMB_AC 8191;
BA_ "GenSigStartValue" SG_ 1724 AVN6BC_1_4_GNSS_STATUS 1;
BA_ "GenSigStartValue" SG_ 1723 AVN6BB_7_0_ISA_IACC_OFFSET_CSTM 10;
BA_ "GenSigStartValue" SG_ 1713 AVN6B1_7_1_PRESENT_YEAR 127;
BA_ "GenSigStartValue" SG_ 1713 AVN6B1_4_0_PRESENT_TIME_SEC 60;
BA_ "GenSigStartValue" SG_ 1713 AVN6B1_3_0_PRESENT_TIME_MIN 60;
BA_ "GenSigStartValue" SG_ 1713 AVN6B1_2_1_PRESENT_TIME_HOUR 30;
BA_ "GenSigStartValue" SG_ 1019 AVN3FB_6_0_ACPANEL_PA_TEMP 63;
BA_ "GenSigStartValue" SG_ 1019 AVN3FB_5_0_ACPANEL_DR_TEMP 63;
BA_ "GenSigSendType" SG_ 818 PMN332_7_0_RES_CONTROL_STATUS 3;
BA_ "GenSigSendType" SG_ 818 PMN332_7_2_REQ_RES_P_LOCK 3;
BA_ "GenSigSendType" SG_ 818 PMN332_7_5_IGB_RELAY_REQ 3;
BA_ "GenSigSendType" SG_ 818 PMN332_7_6_IGA_RELAY_REQ 3;
BA_ "GenSigSendType" SG_ 818 PMN332_7_7_REQ_STOP_RES 3;
BA_ "GenSigSendType" SG_ 818 PMN332_6_0_RES_IDLE_TIME 3;
BA_ "GenSigSendType" SG_ 818 PMN332_6_7_CUST 3;
BA_ "GenSigSendType" SG_ 818 PMN332_5_0_PUSHSTART_SW 3;
BA_ "GenSigSendType" SG_ 818 PMN332_5_1_SIG_KEY_PUSHSTART 3;
BA_ "GenSigSendType" SG_ 818 PMN332_5_2_STATE_MODE_POWER 3;
BA_ "GenSigSendType" SG_ 818 PMN332_5_4_BUZ_2SHOT_IN 3;
BA_ "GenSigSendType" SG_ 818 PMN332_5_5_BUZ_INTERMIT1_IN 3;
BA_ "GenSigSendType" SG_ 818 PMN332_5_6_BUZ_INTERMIT2_IN 3;
BA_ "GenSigSendType" SG_ 818 PMN332_5_7_BUZ_CONTINUE_IN 3;
BA_ "GenSigSendType" SG_ 818 PMN332_2_0_WARN_SSP_SIG1 3;
BA_ "GenSigSendType" SG_ 818 PMN332_2_1_WARN_SSP_SIG2 3;
BA_ "GenSigSendType" SG_ 818 PMN332_2_4_SMT_PWR_SIG 3;
BA_ "GenSigSendType" SG_ 818 PMN332_2_7_BUZ_1SHOT_IN 3;
BA_ "GenSigSendType" SG_ 1618 BIU652_7_0_IND_SECURITY_IMB 3;
BA_ "GenSigSendType" SG_ 1618 BIU652_6_0_OCCUPATION_3RDRH 3;
BA_ "GenSigSendType" SG_ 1618 BIU652_6_1_OCCUPATION_3RDCTR 3;
BA_ "GenSigSendType" SG_ 1618 BIU652_6_2_OCCUPATION_3RDLH 3;
BA_ "GenSigSendType" SG_ 1618 BIU652_6_3_OCCUPATION_RRRH 3;
BA_ "GenSigSendType" SG_ 1618 BIU652_6_4_OCCUPATION_RRCTR 3;
BA_ "GenSigSendType" SG_ 1618 BIU652_6_5_OCCUPATION_RRLH 3;
BA_ "GenSigSendType" SG_ 1618 BIU652_6_6_HORNHAZARD_RES_SIG 3;
BA_ "GenSigSendType" SG_ 1618 BIU652_6_7_OCCUPATION_DRVR 3;
BA_ "GenSigSendType" SG_ 1618 BIU652_5_0_STATUS_ROOMLAMP 3;
BA_ "GenSigSendType" SG_ 1618 BIU652_5_3_HEADLAMP_SMALL 3;
BA_ "GenSigSendType" SG_ 1618 BIU652_5_4_ALL_UNLOCK_STATE 3;
BA_ "GenSigSendType" SG_ 1618 BIU652_5_5_DRVR_UNLOCK_STATE 3;
BA_ "GenSigSendType" SG_ 1618 BIU652_5_6_ALL_LOCK_STATE 3;
BA_ "GenSigSendType" SG_ 1618 BIU652_4_0_TRIG_LOCK_UNLOCK 3;
BA_ "GenSigSendType" SG_ 1618 BIU652_3_0_DOOR_DRVR 3;
BA_ "GenSigSendType" SG_ 1618 BIU652_3_1_DOOR_PASS 3;
BA_ "GenSigSendType" SG_ 1618 BIU652_3_2_DOOR_RRRH 3;
BA_ "GenSigSendType" SG_ 1618 BIU652_3_3_DOOR_RRLH 3;
BA_ "GenSigSendType" SG_ 1618 BIU652_3_4_DOOR_RG 3;
BA_ "GenSigSendType" SG_ 1618 BIU652_3_5_DOOR_TR 3;
BA_ "GenSigSendType" SG_ 1618 BIU652_3_7_OPENSW_RG 3;
BA_ "GenSigSendType" SG_ 1618 BIU652_2_0_LOCKSTATUS_DRVR 3;
BA_ "GenSigSendType" SG_ 1618 BIU652_2_1_LOCKSTATUS_PASS 3;
BA_ "GenSigSendType" SG_ 1618 BIU652_2_2_LOCKSTATUS_RRRH 3;
BA_ "GenSigSendType" SG_ 1618 BIU652_2_3_LOCKSTATUS_RRLH 3;
BA_ "GenSigSendType" SG_ 1618 BIU652_2_4_LOCKSTATUS_RG 3;
BA_ "GenSigSendType" SG_ 1618 BIU652_2_6_UNLOCK_DOORKEYSW 3;
BA_ "GenSigSendType" SG_ 1618 BIU652_2_7_LOCK_DOORKEYSW 3;
BA_ "GenSigSendType" SG_ 1617 BIU651_7_0_PWPOS_RL 3;
BA_ "GenSigSendType" SG_ 1617 BIU651_7_2_PWPOS_RR 3;
BA_ "GenSigSendType" SG_ 1617 BIU651_7_4_PWPOS_PASS 3;
BA_ "GenSigSendType" SG_ 1617 BIU651_7_6_PWPOS_DRVR 3;
BA_ "GenSigSendType" SG_ 1617 BIU651_6_0_IND_ACTIVE_HBA 3;
BA_ "GenSigSendType" SG_ 1617 BIU651_6_2_ADB_ACTIVE 3;
BA_ "GenSigSendType" SG_ 1617 BIU651_6_3_JUDGE_ILL 3;
BA_ "GenSigSendType" SG_ 1617 BIU651_6_4_TYPE_LO_BEAM 3;
BA_ "GenSigSendType" SG_ 1617 BIU651_6_6_TYPE_HI_BEAM 3;
BA_ "GenSigSendType" SG_ 1617 BIU651_5_0_SRF_ACTIVE 3;
BA_ "GenSigSendType" SG_ 1617 BIU651_5_1_SRF_IND 3;
BA_ "GenSigSendType" SG_ 1617 BIU651_5_3_SRF_LAMP_LIGHT 3;
BA_ "GenSigSendType" SG_ 1617 BIU651_5_4_SRF_LAMP_LEFT 3;
BA_ "GenSigSendType" SG_ 1617 BIU651_5_5_MSG_STATUS_HBA 3;
BA_ "GenSigSendType" SG_ 1617 BIU651_5_7_IND_FAIL_HBA 3;
BA_ "GenSigSendType" SG_ 1617 BIU651_4_0_BUZ_PATTERN 3;
BA_ "GenSigSendType" SG_ 1617 BIU651_4_4_CSTM_OPE_ALARM 3;
BA_ "GenSigSendType" SG_ 1617 BIU651_4_6_CSTM_HBA 3;
BA_ "GenSigSendType" SG_ 1617 BIU651_3_0_HEADLAMP_PASS_SW 3;
BA_ "GenSigSendType" SG_ 1617 BIU651_3_1_HEADLAMP_AUTO_SW 3;
BA_ "GenSigSendType" SG_ 1617 BIU651_3_2_JUDGE_DOOR_LOCK 3;
BA_ "GenSigSendType" SG_ 1617 BIU651_3_3_JUDGE_DOOR_UNLOCK 3;
BA_ "GenSigSendType" SG_ 1617 BIU651_3_4_HEADLAMP_Lo_SW 3;
BA_ "GenSigSendType" SG_ 1617 BIU651_3_5_HEADLAMP_HI_SW 3;
BA_ "GenSigSendType" SG_ 1617 BIU651_3_6_WIPER_AUTO_SW 3;
BA_ "GenSigSendType" SG_ 1617 BIU651_3_7_PRG_LIN_MEMORY_ON_OFF 3;
BA_ "GenSigSendType" SG_ 1617 BIU651_2_0_CSTM_ILLUMI_SSR 3;
BA_ "GenSigSendType" SG_ 1617 BIU651_2_1_HANDLE 3;
BA_ "GenSigSendType" SG_ 1617 BIU651_2_2_CSTM_SMT 3;
BA_ "GenSigSendType" SG_ 1617 BIU651_2_3_AJARDOOR_STATUS 3;
BA_ "GenSigSendType" SG_ 1617 BIU651_2_4_ONETOUCH_LAMP_OUT 3;
BA_ "GenSigSendType" SG_ 1617 BIU651_2_5_PRG_FAIL_FLAG 3;
BA_ "GenSigSendType" SG_ 1617 BIU651_2_6_CSTM_PSMECU 3;
BA_ "GenSigSendType" SG_ 1617 BIU651_2_7_STATE_REGIST_DEL 3;
BA_ "GenSigSendType" SG_ 1617 BIU651_1_4_SRPOS 3;
BA_ "GenSigSendType" SG_ 1617 BIU651_1_7_WIPER_INT_STATUS 3;
BA_ "GenSigStartValue" SG_ 942 BIU3AE_5_0_WIPER_FT_VOLUME 2;
BA_ "GenSigStartValue" SG_ 809 BST329_1_4_EB_HMI_WARNINGON 1;
BA_ "GenSigStartValue" SG_ 809 BST329_1_6_WARN_BST_RED 1;
BA_ "Fhi_SignalComment" SG_ 811 EPB32B_6_0_VEHICLE_RUN_STOP_FLG "-

";
BA_ "Fhi_SignalComment" SG_ 811 EPB32B_5_0_FLG_AVH_OILPRES_EPB "-

";
BA_ "Fhi_SignalComment" SG_ 811 EPB32B_5_1_FLG_AVH "-

";
BA_ "Fhi_SignalComment" SG_ 811 EPB32B_5_2_AVH_INTENSIFY_PRES "-

";
BA_ "Fhi_SignalComment" SG_ 811 EPB32B_5_3_BREAK_IND "-

";
BA_ "Fhi_SignalComment" SG_ 811 EPB32B_5_5_AVH_ON_LAMP "-

";
BA_ "Fhi_SignalComment" SG_ 811 EPB32B_4_0_BUZZER "-

";
BA_ "Fhi_SignalComment" SG_ 811 EPB32B_4_2_HILL_HOLD_ON_LAMP "-

";
BA_ "Fhi_SignalComment" SG_ 811 EPB32B_4_3_CLAMP_LAMP "-

";
BA_ "Fhi_SignalComment" SG_ 811 EPB32B_4_5_WARN_LAMP "-

";
BA_ "Fhi_SignalComment" SG_ 811 EPB32B_4_7_WARN_EPB_MET_LCD "-

";
BA_ "Fhi_SignalComment" SG_ 811 EPB32B_3_0_STATUS_EPB "-

";
BA_ "Fhi_SignalComment" SG_ 811 EPB32B_3_3_DYNAMIC_PARKING "-

";
BA_ "Fhi_SignalComment" SG_ 811 EPB32B_3_4_HILL_HOLD_RUN_FLG "-

";
BA_ "Fhi_SignalComment" SG_ 811 EPB32B_3_5_INHIBIT_ISS_DELAY "-

";
BA_ "Fhi_SignalComment" SG_ 811 EPB32B_3_6_INHIBIT_ISS "-

";
BA_ "Fhi_SignalComment" SG_ 811 EPB32B_2_0_ERR_INFO "-

";
BA_ "Fhi_SignalComment" SG_ 811 EPB32B_2_2_EPB_FAIL_FLG1 "-

";
BA_ "Fhi_SignalComment" SG_ 811 EPB32B_2_3_EPB_FAIL_FLG2 "-

";
BA_ "Fhi_SignalComment" SG_ 811 EPB32B_2_4_EPB_FAIL_FLG3 "-

";
BA_ "Fhi_SignalComment" SG_ 811 EPB32B_1_5_REQ_COMM_CONT "-

";
BA_ "GenSigSendType" SG_ 808 VDC328_7_3_FLAG_ACT_CBC 3;
BA_ "GenSigStartValue" SG_ 808 VDC328_5_2_WARN_BRAKE_BOOST 1;
BA_ "GenSigSendType" SG_ 808 VDC328_5_4_WARN_RBS 3;
BA_ "GenSigSendType" SG_ 808 VDC328_5_6_IND_HSA_ON 3;
BA_ "GenSigStartValue" SG_ 808 VDC328_5_7_IND_TCS_OFF 1;
BA_ "GenSigSendType" SG_ 808 VDC328_5_7_IND_TCS_OFF 3;
BA_ "GenSigStartValue" SG_ 808 VDC328_4_0_IND_VDC_OFF 1;
BA_ "GenSigStartValue" SG_ 808 VDC328_4_5_WARNING_BRAKE_SYS 1;
BA_ "GenSigStartValue" SG_ 808 VDC328_3_0_IND_WARN_EBD 1;
BA_ "GenSigStartValue" SG_ 808 VDC328_3_1_IND_WARN_ABS 1;
BA_ "GenSigStartValue" SG_ 808 VDC328_3_2_IND_WARN_VDC 1;
BA_ "GenSigStartValue" SG_ 808 VDC328_3_3_IND_WARN_HSA 1;
BA_ "GenSigStartValue" SG_ 808 VDC328_3_6_IND_TCS_OFF 1;
BA_ "Fhi_SignalComment" SG_ 316 VDC13C_7_0_RCV_FAIL_ADA "EyeSight対応以外は『0固定』

";
BA_ "Fhi_SignalComment" SG_ 316 VDC13C_7_1_FAIL_PCU "EyeSight対応以外は『0固定』

";
BA_ "Fhi_SignalComment" SG_ 316 VDC13C_7_2_CONT_STATE_ES_BRAKE "EyeSight対応以外は『0固定』

";
BA_ "Fhi_SignalComment" SG_ 316 VDC13C_7_3_ASST_PRECRUSH_ACC "EyeSight対応以外は『0固定』

";
BA_ "Fhi_SignalComment" SG_ 316 VDC13C_7_4_CONT_STATE_PRECRUSH "EyeSight対応以外は『0固定』

";
BA_ "Fhi_SignalComment" SG_ 316 VDC13C_7_5_PERMIT_BRAKE_ACC "EyeSight対応以外は『0固定』

";
BA_ "Fhi_SignalComment" SG_ 316 VDC13C_7_6_DETECT_BRAKING "EyeSight対応以外は『0固定』

";
BA_ "GenSigStartValue" SG_ 316 VDC13C_6_6_VDC_OFF 1;
BA_ "Fhi_SignalComment" SG_ 316 VDC13C_5_7_ACTIVATE_TSM "BF4：「0：非制御中」固定

";
BA_ "Fhi_SignalComment" SG_ 316 VDC13C_1_7_STATUS_BRAKELAMP "EyeSight対応以外は『0固定』

";
BA_ "Fhi_SignalComment" SG_ 315 VDC13B_7_0_ACCELERATE_F_R "補正値

";
BA_ "Fhi_SignalComment" SG_ 315 VDC13B_6_0_ACCELERATE_L_R "補正値

";
BA_ "GenSigStartValue" SG_ 315 VDC13B_4_0_ENG_TRQ_DOWN 65535;
BA_ "GenSigStartValue" SG_ 313 VDC139_7_4_FAIL_PRESSURE_SSR 1;
BA_ "Fhi_SignalComment" SG_ 313 VDC139_7_5_STATUS_EPB "-

";
BA_ "GenSigStartValue" SG_ 313 VDC139_4_3_FAIL_BRAKELAMPSW 1;
BA_ "GenSigStartValue" SG_ 313 VDC139_3_5_FAIL_VDC_SSR 1;
BA_ "GenSigStartValue" SG_ 313 VDC139_3_6_FAIL_SPD_SSR_FHI 1;
BA_ "GenSigStartValue" SG_ 313 VDC139_3_7_FAIL_ABS_SYS 1;
BA_ "Fhi_SignalComment" SG_ 313 VDC139_2_0_SPD_WHEEL_AVE "GW:ID139-B3b4~B2b0→ID270-B5b4~B4b0

";
BA_ "GenSigStartValue" SG_ 313 VDC139_1_4_FAIL_HDC_SYS 1;
BA_ "Fhi_SignalComment" SG_ 313 VDC139_1_5_VEHICLE_HIGHT "XUVは「01:OBK」/北米SPORT_OBKは「10:標準」を送信

";
BA_ "Fhi_SignalComment" SG_ 312 VDC138_7_0_PRESSURE_WC_FTLH "EyeSight対応以外は『0固定』

";
BA_ "Fhi_SignalComment" SG_ 312 VDC138_6_0_PRESSURE_WC_FTRH "EyeSight対応以外は『0固定』

";
BA_ "Fhi_SignalComment" SG_ 312 VDC138_4_0_YAW_RATE "補正値

";
BA_ "Fhi_SignalComment" SG_ 312 VDC138_2_0_STEER_ANGLE "補正値

";
BA_ "GenSigStartValue" SG_ 1709 CCU6AD_6_3_EYE_MONI_BLUE_IND_SET 1;
BA_ "GenSigStartValue" SG_ 1709 CCU6AD_6_2_EYE_MONI_GRE_IND_SET 1;
BA_ "GenSigStartValue" SG_ 1709 CCU6AD_6_1_EYE_MONI_YEL_IND_SET 1;
BA_ "GenSigStartValue" SG_ 1709 CCU6AD_6_0_EYE_MONI_RED_IND_SET 1;
BA_ "GenSigStartValue" SG_ 1149 CCU47D_3_0_AA_EST_CHG_TIME 4294967295;
BA_ "GenSigStartValue" SG_ 1148 CCU47C_7_0_AA_CRG_MAX_OUT_WAT 4294967295;
BA_ "GenSigStartValue" SG_ 1148 CCU47C_3_0_AA_DEP_MIN_BAT_LEVEL 4294967295;
BA_ "GenSigStartValue" SG_ 1144 CCU478_23_0_LAT_CHG_END_TIME 2046;
BA_ "GenSigStartValue" SG_ 1144 CCU478_21_2_LAT_CHG_START_TIME 2046;
BA_ "GenSigStartValue" SG_ 1144 CCU478_16_0_DEP_TIM4_START_TIME 2046;
BA_ "GenSigStartValue" SG_ 1144 CCU478_12_0_DEP_TIM3_START_TIME 2046;
BA_ "GenSigStartValue" SG_ 1144 CCU478_8_0_DEP_TIM2_START_TIME 2046;
BA_ "GenSigStartValue" SG_ 1144 CCU478_4_0_DEP_TIM1_START_TIME 2046;
BA_ "GenSigStartValue" SG_ 1105 CCU451_6_0_CHG_COMTI 2046;
BA_ "GenSigStartValue" SG_ 1105 CCU451_4_1_CHG_HILMT_REQ 126;
BA_ "GenSigStartValue" SG_ 1105 CCU451_3_4_DCCHG_PWRUPLMT 14;
BA_ "GenSigStartValue" SG_ 1105 CCU451_3_0_ACCHG_CORUPLMT 14;
BA_ "GenSigSendType" SG_ 1726 CCU6BE_10_0_CCU_BOOT_STATE 3;
BA_ "GenSigSendType" SG_ 1726 CCU6BE_9_0_DISP_DRAINAGE 3;
BA_ "GenSigSendType" SG_ 1726 CCU6BE_8_0_DISP_POURING_WATER 3;
BA_ "GenSigSendType" SG_ 1726 CCU6BE_7_4_QDK_DEV 3;
BA_ "GenSigSendType" SG_ 1726 CCU6BE_5_0_SLOTID_ERASE 3;
BA_ "GenSigSendType" SG_ 1726 CCU6BE_4_2_QDK_OSWAP 3;
BA_ "GenSigSendType" SG_ 1726 CCU6BE_4_4_QDK_FDRQ 3;
BA_ "GenSigSendType" SG_ 1726 CCU6BE_4_6_QDK_OWCQ 3;
BA_ "GenSigSendType" SG_ 1726 CCU6BE_3_0_QDK_ORRQ 3;
BA_ "GenSigSendType" SG_ 1726 CCU6BE_3_2_QDK_OGRQ 3;
BA_ "GenSigSendType" SG_ 1726 CCU6BE_3_4_QDK_ODRQ 3;
BA_ "GenSigSendType" SG_ 1726 CCU6BE_3_6_QDK_ADLQ 3;
BA_ "GenSigSendType" SG_ 1726 CCU6BE_2_0_E2E_COUNTER 3;
BA_ "GenSigSendType" SG_ 1726 CCU6BE_0_0_CRC 3;
VAL_ 1654 ACN676_1_5_REQ_HVH_STB 1 "STB ON要求有り" 0 "STB ON要求無し" ;
VAL_ 1654 ACN676_1_4_REQ_HVH_ON 1 "ヒータON要求有り" 0 "ヒータON要求無し" ;
VAL_ 1652 ACN674_7_0_STATE_AC_CONT 3 "FULL A/C MODE" 2 "コンプレッサON MODE" 1 "未定義" 0 "コンプレッサOFF MODE" ;
VAL_ 1652 ACN674_6_6_REQ_OBD_WARNING 1 "REQ" 0 "NON REQ" ;
VAL_ 1652 ACN674_6_1_REQ_CAUTION_AC 1 "REQ" 0 "NON REQ" ;
VAL_ 1652 ACN674_6_0_REQ_COMP_STB 1 "スタンバイON要求" 0 "スタンバイOFF要求" ;
VAL_ 1652 ACN674_1_5_JUDGE_SLOWSTART 1 "可" 0 "否" ;
VAL_ 1652 ACN674_1_4_JUDGE_COMPWAKE 1 "可" 0 "否" ;
VAL_ 1725 AVN6BD_7_1_EYE_SAFETY_MODE_CSTM 1 "ON" 0 "OFF" ;
VAL_ 1725 AVN6BD_7_2_EYE_BRAKE_HAPTIC_CSTM 3 "BUZZER OFF/BREAK OFF" 2 "BUZZER OFF/BREAK ON" 1 "BUZZER ON/BREAK OFF" 0 "BUZZER ON/BREAK ON" ;
VAL_ 1725 AVN6BD_7_4_LDW_SW_PUSH_STATE 1 "SW_Push" 0 "SW_Release" ;
VAL_ 1725 AVN6BD_7_5_LDW_SW_FAIL_STATE 1 "Fail" 0 "No_Fail" ;
VAL_ 1725 AVN6BD_7_6_FCW_SW_PUSH_STATE 1 "SW_Push" 0 "SW_Release" ;
VAL_ 1725 AVN6BD_7_7_FCW_SW_FAIL_STATE 1 "Fail" 0 "No_Fail" ;
VAL_ 1725 AVN6BD_6_0_REQ_CHG_CSTM_EYE 1 "required" 0 "NOT required" ;
VAL_ 1725 AVN6BD_6_1_REQ_RESET_CSTM_EYE 1 "required" 0 "NOT required" ;
VAL_ 1725 AVN6BD_6_3_CSTM_LANE_CONT 1 "LEFT" 0 "RIGHT" ;
VAL_ 1725 AVN6BD_6_4_CSTM_MIS_AT_BACK 3 "ON_FAST" 2 "ON_MIDDLE" 1 "ON_SLOW" 0 "OFF" ;
VAL_ 1725 AVN6BD_6_6_CSTM_ACC_CONT 3 "Dynamic" 2 "Standard" 1 "Comfort" 0 "Eco" ;
VAL_ 1724 AVN6BC_5_0_LAT_N_S 1 "South" 0 "North" ;
VAL_ 1724 AVN6BC_1_4_GNSS_STATUS 7 "GNSS fail" 6 "Estimation error level 5" 5 "Estimation error level 4" 4 "Estimation error level 3" 3 "Estimation error level 2" 2 "Estimation error level 1" 1 "No fix" 0 "Invalid" ;
VAL_ 1724 AVN6BC_1_7_LON_E_W 1 "East" 0 "West" ;
VAL_ 1723 AVN6BB_7_0_ISA_IACC_OFFSET_CSTM 20 "10" 19 "9" 18 "8" 17 "7" 16 "6" 15 "5" 14 "4" 13 "3" 12 "2" 11 "1" 10 "0" 9 "-1" 8 "-2" 7 "-3" 6 "-4" 5 "-5" 4 "-6" 3 "-7" 2 "-8" 1 "-9" 0 "-10" ;
VAL_ 1723 AVN6BB_7_5_EYE_TOLLBOOTH_DECEL 1 "ON" 0 "OFF" ;
VAL_ 1723 AVN6BB_7_6_EYE_CURVE_DECEL_CSTM 1 "ON" 0 "OFF" ;
VAL_ 1723 AVN6BB_7_7_EYE_GREEN_LIGHT_CSTM 1 "ON" 0 "OFF" ;
VAL_ 1723 AVN6BB_6_0_CCU_FAIL 1 "FAIL" 0 "NORMAL" ;
VAL_ 1723 AVN6BB_6_1_EYE_P_CR_CSTM 1 "ON" 0 "OFF" ;
VAL_ 1723 AVN6BB_6_2_EYE_ALK_B_LDW_CSTM 3 "ALK-B ON+LDW ON" 2 "ALK-B ON+LDW OFF" 1 "ALK-B OFF+LDW ON" 0 "ALK-B OFF+LDW OFF" ;
VAL_ 1723 AVN6BB_6_4_EYE_CSTM_REQ 1 "required" 0 "NOT required" ;
VAL_ 1723 AVN6BB_6_5_EYE_ELK_CSTM 1 "ON" 0 "OFF" ;
VAL_ 1723 AVN6BB_6_6_EYE_ALKB_EDGE_CSTM 1 "ON" 0 "OFF" ;
VAL_ 1723 AVN6BB_6_7_FCW_ON_OFF 1 "ON" 0 "OFF" ;
VAL_ 1723 AVN6BB_5_0_DMS_SELECT_ID 5 "ID5" 4 "ID4" 3 "ID3" 2 "ID2" 1 "ID1" 0 "DEFAULT" ;
VAL_ 1723 AVN6BB_5_4_TPMS_TH_MODE_CSTM 3 "TPMS3 SW (Towing)" 2 "TPMS2 SW (Loading)" 1 "TPMS1 SW (Normal)" 0 "No Operation" ;
VAL_ 1723 AVN6BB_5_6_DMS_SET_REQ 1 "required" 0 "NOT required" ;
VAL_ 1723 AVN6BB_5_7_DMS_RECOG_SET 1 "RECOG_ON" 0 "RECOG_OFF" ;
VAL_ 1723 AVN6BB_4_0_DMS_EDIT_REQ 15 "Operation Failure" 6 "MANUAL_SCAN" 5 "ID_CUST_DEL" 4 "ID_CUST_SET" 3 "ALL_ID_DEL" 2 "ID_DEL_SELECT" 1 "ID_REGIST" 0 "DEFAULT" ;
VAL_ 1723 AVN6BB_4_4_VEHICLE_DEMO 1 "ON" 0 "OFF (Default)" ;
VAL_ 1723 AVN6BB_4_5_SRVD_CSTM_REQ 1 "required" 0 "NOT required" ;
VAL_ 1723 AVN6BB_4_6_SEAT_RESET_REQ 1 "required" 0 "NOT required" ;
VAL_ 1723 AVN6BB_4_7_SEATAWAY_SET_CSTM 1 "required" 0 "NOT required" ;
VAL_ 1723 AVN6BB_3_0_SRVD_ON_OFF 1 "ON" 0 "OFF" ;
VAL_ 1723 AVN6BB_3_1_PRG_RESET_REQ 1 "required" 0 "NOT required" ;
VAL_ 1723 AVN6BB_3_2_PRG_MEM_CSTM 1 "required" 0 "NOT required" ;
VAL_ 1723 AVN6BB_3_3_DMS_ON_OFF 1 "ON/OFF Change" 0 "invalid" ;
VAL_ 1723 AVN6BB_3_4_MIR_RESET_REQ 1 "required" 0 "NOT required" ;
VAL_ 1723 AVN6BB_3_5_MIR_AFOLD_CSTM 1 "required" 0 "NOT required" ;
VAL_ 1723 AVN6BB_3_6_MIR_RTILT_CSTM 1 "required" 0 "NOT required" ;
VAL_ 1723 AVN6BB_3_7_EYE_TSA_CSTM 1 "TSA Enable(ISA)" 0 "TSA Disable(MSA)" ;
VAL_ 1723 AVN6BB_2_0_AVH_ON_OFF 3 "BLANK_NoInput" 2 "AVH ON_Input" 1 "AVH OFF_Input" 0 "Neutral" ;
VAL_ 1723 AVN6BB_2_2_VDC_ON_OFF 3 "BLANK_NoInput" 2 "VDC ON_Input" 1 "VDC OFF_Input" 0 "Neutral" ;
VAL_ 1723 AVN6BB_2_4_CCU_HALT_RESET 1 "Reset/Halt" 0 "Normal" ;
VAL_ 1723 AVN6BB_2_5_EYE_LDW_TIMING_CSTM 1 "LATE" 0 "EARLY" ;
VAL_ 1723 AVN6BB_2_6_FCW_CSTM 3 "OFF" 2 "FAR" 1 "NEAR" 0 "ON/NORM" ;
VAL_ 1723 AVN6BB_1_4_EYE_WARN_CSTM 1 "Steering Wheel Vibration" 0 "Buzzer" ;
VAL_ 1723 AVN6BB_1_5_EYE_FCTI_CSTM 3 "Reserve" 2 "Display + Sound" 1 "Display" 0 "OFF" ;
VAL_ 1723 AVN6BB_1_7_LDW_WARNING_ON_OFF 1 "ON" 0 "OFF" ;
VAL_ 1713 AVN6B1_5_0_FAIL_AVN 1 "improperly" 0 "properly" ;
VAL_ 1713 AVN6B1_5_1_IN_OPERATION 1 "operating" 0 "non operating" ;
VAL_ 1713 AVN6B1_5_2_TYPE_NAVI 3 "High" 2 "Mid" 1 "Base" 0 "Non" ;
VAL_ 1713 AVN6B1_5_4_XM_ENABLE 3 "Reservation" 2 "Reservation" 1 "Receivable" 0 "Non" ;
VAL_ 1713 AVN6B1_5_6_FLG_ABLE_WELCOME_SCL 1 "表示可" 0 "表示不可" ;
VAL_ 1713 AVN6B1_5_7_STEER_ANGLE_INTERLOCK 1 "ON" 0 "OFF" ;
VAL_ 1713 AVN6B1_4_7_BACK_CAMERA_DELAY 1 "ON" 0 "OFF" ;
VAL_ 1713 AVN6B1_3_7_MVS_FTSNR_INTERRUPT 1 "ON" 0 "OFF" ;
VAL_ 1713 AVN6B1_2_0_GPS_CLOCK_FLG 1 "validity" 0 "invalidity" ;
VAL_ 1713 AVN6B1_2_6_TIME_FORMAT 3 "Reserved" 2 "24h" 1 "12h" 0 "Invalid" ;
VAL_ 1713 AVN6B1_1_4_WAKE_UP_FRAME 1 "WakeUP_FRAME" 0 "Normal_FRAME" ;
VAL_ 1713 AVN6B1_1_5_REQ_COMM_CONT 1 "REQ" 0 "NON_REQ" ;
VAL_ 1713 AVN6B1_1_6_ACTIVE_AVN_CSTM 1 "Customize" 0 "Non Customize" ;
VAL_ 1713 AVN6B1_1_7_REQ_STOP_CAMERA_OUT 1 "Request" 0 "No request" ;
VAL_ 1019 AVN3FB_7_0_SMT_TIM_RESET_REQ 1 "required" 0 "NOT required" ;
VAL_ 1019 AVN3FB_7_1_SMT_EG_CSTM_REQ 1 "required" 0 "NOT required" ;
VAL_ 1019 AVN3FB_7_2_EYE_YEILD_CSTM 1 "ON" 0 "OFF" ;
VAL_ 1019 AVN3FB_7_3_EYE_STOP_CSTM 1 "ON" 0 "OFF" ;
VAL_ 1019 AVN3FB_7_4_EYE_NO_ENTRY_CSTM 1 "ON" 0 "OFF" ;
VAL_ 1019 AVN3FB_7_5_MVS_CAMERA_SELECT_SW 1 "SW Push Event" 0 "No Operation(SW Release Event)" ;
VAL_ 1019 AVN3FB_7_7_ACPANEL_DR_ONLY 1 "SW Push Event" 0 "invalid" ;
VAL_ 1019 AVN3FB_6_6_ACPANEL_MODE_DOWN 1 "SW Push Event" 0 "invalid" ;
VAL_ 1019 AVN3FB_6_7_ACPANEL_MODE_UP 1 "SW Push Event" 0 "invalid" ;
VAL_ 1019 AVN3FB_5_6_ACPANEL_FAN_DOWN 1 "SW Push Event" 0 "invalid" ;
VAL_ 1019 AVN3FB_5_7_ACPANEL_FAN_UP 1 "SW Push Event" 0 "invalid" ;
VAL_ 1019 AVN3FB_4_0_ACPANEL_FAN_LEVEL 15 "No change" 14 "Reserve" 13 "Reserve" 12 "Reserve" 11 "Reserve" 10 "Reserve" 9 "Reserve" 8 "Reserve" 7 "HI" 6 "M5" 5 "M4" 4 "M3" 3 "M2" 2 "M1" 1 "LO" 0 "invalid" ;
VAL_ 1019 AVN3FB_4_4_ACPANEL_MODE_VENT 15 "Invalid" 6 "DEF" 5 "FOOT/DEF" 4 "FOOT" 3 "B/L" 2 "VENTⅡ" 1 "VENT" 0 "Invalid" ;
VAL_ 1019 AVN3FB_3_0_ACPANEL_PA_TEMP_DOWN 1 "SW Push Event" 0 "invalid" ;
VAL_ 1019 AVN3FB_3_1_ACPANEL_PA_TEMP_UP 1 "SW Push Event" 0 "invalid" ;
VAL_ 1019 AVN3FB_3_2_ACPANEL_DR_TEMP_DOWN 1 "SW Push Event" 0 "invalid" ;
VAL_ 1019 AVN3FB_3_3_ACPANEL_DR_TEMP_UP 1 "SW Push Event" 0 "invalid" ;
VAL_ 1019 AVN3FB_3_4_ACPANEL_SYNC 1 "SW Push Event" 0 "invalid" ;
VAL_ 1019 AVN3FB_3_5_ACPANEL_AC 1 "SW Push Event" 0 "invalid" ;
VAL_ 1019 AVN3FB_3_6_F_DEF_SW 1 "SW Push Event" 0 "invalid" ;
VAL_ 1019 AVN3FB_3_7_R_DEF_SW 1 "SW Push Event" 0 "invalid" ;
VAL_ 1019 AVN3FB_2_0_ACPANEL_AUTO 1 "SW Push Event" 0 "invalid" ;
VAL_ 1019 AVN3FB_2_1_ACPANEL_MAX_AC 1 "SW Push Event" 0 "invalid" ;
VAL_ 1019 AVN3FB_2_2_ACPANEL_SEAT_C_P 1 "SW Push Event" 0 "invalid" ;
VAL_ 1019 AVN3FB_2_3_ACPANEL_SEAT_C_D 1 "SW Push Event" 0 "invalid" ;
VAL_ 1019 AVN3FB_2_4_ACPANEL_SEAT_H_P 1 "SW Push Event" 0 "invalid" ;
VAL_ 1019 AVN3FB_2_5_ACPANEL_SEAT_H_D 1 "SW Push Event" 0 "invalid" ;
VAL_ 1019 AVN3FB_2_6_ACPANEL_INNER_AIR 1 "SW Push Event" 0 "invalid" ;
VAL_ 1019 AVN3FB_2_7_ACPANEL_AC_ON_OFF 1 "SW Push Event" 0 "invalid" ;
VAL_ 1019 AVN3FB_1_4_EYE_CSTM_REQ_3FB 1 "required" 0 "NOT required" ;
VAL_ 1019 AVN3FB_1_5_DDAW_WARNING_CSTM 1 "ON" 0 "OFF" ;
VAL_ 1019 AVN3FB_1_6_SIGN_SWITCH_SND 1 "ON" 0 "OFF" ;
VAL_ 1019 AVN3FB_1_7_SLWF_CSTM 1 "ON" 0 "OFF" ;
VAL_ 818 PMN332_7_0_RES_CONTROL_STATUS 3 "Termination for Remote engine start control (Termination sequence for Remote engine start control)" 2 "Remote engine start heating operation (During Remote engine start running)" 1 "Remote engine start starting control (Before engine starts)" 0 "OFF (Remote engine start uncontrolled)" ;
VAL_ 818 PMN332_7_2_REQ_RES_P_LOCK 1 "REQ_RES_P_LOCK" 0 "NON_REQ" ;
VAL_ 818 PMN332_7_7_REQ_STOP_RES 1 "REQ_STOP_RES" 0 "NON_REQ" ;
VAL_ 818 PMN332_6_7_CUST 1 "ON" 0 "OFF" ;
VAL_ 818 PMN332_5_0_PUSHSTART_SW 1 "ON" 0 "OFF" ;
VAL_ 818 PMN332_5_1_SIG_KEY_PUSHSTART 1 "Key_DEFINED" 0 "Key_NOT_DEFINED" ;
VAL_ 818 PMN332_5_2_STATE_MODE_POWER 2 "RES_Start_MODE" 1 "Pre_Air_Cond_MODE" 0 "Normal_MODE" ;
VAL_ 818 PMN332_5_4_BUZ_2SHOT_IN 1 "REQ" 0 "NON_REQ" ;
VAL_ 818 PMN332_5_5_BUZ_INTERMIT1_IN 1 "REQ" 0 "NON_REQ" ;
VAL_ 818 PMN332_5_6_BUZ_INTERMIT2_IN 1 "REQ" 0 "NON_REQ" ;
VAL_ 818 PMN332_5_7_BUZ_CONTINUE_IN 1 "REQ" 0 "NON_REQ" ;
VAL_ 818 PMN332_2_0_WARN_SSP_SIG1 1 "SMART_FAIL_WARN" 0 "NON_REQ" ;
VAL_ 818 PMN332_2_1_WARN_SSP_SIG2 4 "TIMER_RESET_DISPLAY" 3 "30S_BEFORE_ENGINE_STOP" 2 "SMART_EMERGENCY_STOP_OPERATION" 1 "SMART_FAIL_WARN" 0 "NON_REQ" ;
VAL_ 818 PMN332_2_4_SMT_PWR_SIG 2 "IGNITION_ON_IND" 1 "ACCESSORY_IND" 0 "NON_REQ" ;
VAL_ 818 PMN332_2_7_BUZ_1SHOT_IN 1 "REQ" 0 "NON_REQ" ;
VAL_ 1622 BIU656_6_0_KICK_OPEN_REQ_PRG 1 "ACTIVE" 0 "NON_ACTIVE" ;
VAL_ 1622 BIU656_6_1_KICK_CLOSE_REQ_PRG 1 "ACTIVE" 0 "NON_ACTIVE" ;
VAL_ 1622 BIU656_6_6_CARGO_LAMP_OUT 1 "Turn_ON" 0 "Turn_OFF" ;
VAL_ 1622 BIU656_6_7_PERMITT_KEY_RG_UNL 1 "PERMIT" 0 "INHIBIT" ;
VAL_ 1622 BIU656_5_0_PRG_DRVR_OPENERSW 1 "ON" 0 "OFF" ;
VAL_ 1622 BIU656_5_1_HF_PRG_OFF_SW 1 "ON" 0 "OFF" ;
VAL_ 1622 BIU656_5_2_PERMIT_OPEN_RG 1 "PERMIT" 0 "INHIBIT" ;
VAL_ 1622 BIU656_5_3_BUZ_ON_OFF 1 "ON" 0 "OFF" ;
VAL_ 1622 BIU656_5_4_PRG_DRVR_SW_PERMIT 1 "PERMIT" 0 "INHIBIT" ;
VAL_ 1622 BIU656_5_5_CSTM_HF_PRG_LOCK 1 "ACTIVE" 0 "NON_ACTIVE" ;
VAL_ 1622 BIU656_5_6_CSTM_KICK_SENSOR 1 "ACTIVE" 0 "NON_ACTIVE" ;
VAL_ 1622 BIU656_5_7_KICK_REQ_PRG 1 "ACTIVE" 0 "NON_ACTIVE" ;
VAL_ 1622 BIU656_4_0_NOT_SMT_KEY_RG_SW 3 "No_definition" 2 "Long_Key_Press" 1 "Short_Key_Press" 0 "OFF" ;
VAL_ 1622 BIU656_4_2_SMT_KEY_RG_SW 3 "No_definition" 2 "Long_Key_Press" 1 "Short_Key_Press" 0 "OFF" ;
VAL_ 1622 BIU656_4_4_OPEN_RG_OPENER_SW 3 "No_definition" 2 "Long_Key_Press" 1 "Short_Key_Press" 0 "OFF" ;
VAL_ 1622 BIU656_3_4_CHECKED_KEYNO 7 "SMT_KEY_7" 6 "SMT_KEY_6" 5 "SMT_KEY_5" 4 "SMT_KEY_4" 3 "SMT_KEY_3" 2 "SMT_KEY_2" 1 "SMT_KEY_1" 0 "Unregistered" ;
VAL_ 1622 BIU656_3_7_LOCKSTATUS_DRVR 1 "UNLOCK" 0 "LOCK" ;
VAL_ 1621 BIU655_4_0_BUZZER_PATTERN 178 "BUZ_pattern2_by_autolock" 177 "BUZ_pattern1_by_autolock" 165 "BUZ_pattern5_by_answerback" 164 "BUZ_pattern4_by_answerback" 163 "BUZ_pattern3_by_answerback" 162 "BUZ_pattern2_by_answerback" 161 "BUZ_pattern1_by_answerback" 240 "BUZ_stop_by_keyless" 145 "BUZ_pattern4_by_keyless" 129 "BUZ_pattern3_by_keyless" 225 "BUZ_pattern2_by_keyless" 97 "BUZ_pattern1_by_keyless" 0 "BUZ_hold" ;
VAL_ 1621 BIU655_3_0_BUZZER_VOL_REQ 7 "ON_duty_7" 6 "ON_duty_6" 5 "ON_duty_5" 4 "ON_duty_4" 3 "ON_duty_3" 2 "ON_duty_2" 1 "ON_duty_1" 0 "NONE" ;
VAL_ 1621 BIU655_3_3_RDEF_RELAY_REQ 1 "ON_REQ" 0 "OFF_REQ" ;
VAL_ 1621 BIU655_3_4_WIPER_DEICER_REQ 1 "ON_REQ" 0 "OFF_REQ" ;
VAL_ 1621 BIU655_3_5_FT_WIPER_REQ 3 "NON" 2 "Hi_REQ" 1 "Lo_REQ" 0 "OFF" ;
VAL_ 1621 BIU655_2_0_RR_WIPER_REQ 1 "ON_REQ" 0 "OFF_REQ" ;
VAL_ 1621 BIU655_2_1_WASHER_REQ 3 "NON" 2 "Rr_REQ" 1 "Fr_REQ" 0 "OFF" ;
VAL_ 1621 BIU655_2_3_HL_WASHER_REQ 1 "ON_REQ" 0 "OFF_REQ" ;
VAL_ 1621 BIU655_2_4_FT_FOG_RELAY_REQ 1 "ON_REQ" 0 "OFF_REQ" ;
VAL_ 1621 BIU655_2_5_HEADLAMP_HI_REQ 3 "NON" 2 "ON_REQ" 1 "Dimmer_REQ" 0 "OFF" ;
VAL_ 1621 BIU655_2_7_HEADLAMP_LO_REQ 1 "ON_REQ" 0 "OFF_REQ" ;
VAL_ 1618 BIU652_7_0_IND_SECURITY_IMB 6 "WARNING by the supersonic wave sensor" 5 "WARNING by the impact sensor" 4 "ALARM by the supersonic wave sensor" 3 "ALARM by the impact sensor" 7 "ALARM by open the hood" 2 "ALARM by open the trunk" 1 "ALARM by open the door" 240 "Four flashing with the immobilize" 224 "Three flashing by the immobilizer" 208 "Two flashing by the immobilizer" 192 "One flashing by the immobilizer" 144 "Flashing by the immobilizer" 128 "Lighting by the immobilizer" 112 "Lighting by the panic mode" 96 "Wait flashing by ALARM" 80 "Flashing by ALARM" 64 "Lighting by ALARM" 0 "OFF" ;
VAL_ 1618 BIU652_6_0_OCCUPATION_3RDRH 1 "ON" 0 "OFF" ;
VAL_ 1618 BIU652_6_1_OCCUPATION_3RDCTR 1 "ON" 0 "OFF" ;
VAL_ 1618 BIU652_6_2_OCCUPATION_3RDLH 1 "ON" 0 "OFF" ;
VAL_ 1618 BIU652_6_3_OCCUPATION_RRRH 1 "ON" 0 "OFF" ;
VAL_ 1618 BIU652_6_4_OCCUPATION_RRCTR 1 "ON" 0 "OFF" ;
VAL_ 1618 BIU652_6_5_OCCUPATION_RRLH 1 "ON" 0 "OFF" ;
VAL_ 1618 BIU652_6_6_HORNHAZARD_RES_SIG 1 "ON" 0 "OFF" ;
VAL_ 1618 BIU652_6_7_OCCUPATION_DRVR 1 "ON" 0 "OFF" ;
VAL_ 1618 BIU652_5_0_STATUS_ROOMLAMP 7 "TURN_ON_α_S4" 6 "TURN_ON_α_S3A" 5 "TURN_ON_α_S3" 4 "TURN_ON_Pattern2_S2A" 3 "TURN_ON_Pattern1_S2" 2 "TURN_OFF_Pattern2_S1A" 1 "TURN_OFF_Pattern1_S1" 0 "TURN_OFF_S0" ;
VAL_ 1618 BIU652_5_3_HEADLAMP_SMALL 1 "Turn_ON" 0 "Turn_OFF" ;
VAL_ 1618 BIU652_5_4_ALL_UNLOCK_STATE 1 "ON" 0 "OFF" ;
VAL_ 1618 BIU652_5_5_DRVR_UNLOCK_STATE 1 "ON" 0 "OFF" ;
VAL_ 1618 BIU652_5_6_ALL_LOCK_STATE 1 "ON" 0 "OFF" ;
VAL_ 1618 BIU652_3_0_DOOR_DRVR 1 "OPEN" 0 "CLOSE" ;
VAL_ 1618 BIU652_3_1_DOOR_PASS 1 "OPEN" 0 "CLOSE" ;
VAL_ 1618 BIU652_3_2_DOOR_RRRH 1 "OPEN" 0 "CLOSE" ;
VAL_ 1618 BIU652_3_3_DOOR_RRLH 1 "OPEN" 0 "CLOSE" ;
VAL_ 1618 BIU652_3_4_DOOR_RG 1 "OPEN" 0 "CLOSE" ;
VAL_ 1618 BIU652_3_5_DOOR_TR 1 "OPEN" 0 "CLOSE" ;
VAL_ 1618 BIU652_3_7_OPENSW_RG 1 "ON" 0 "OFF" ;
VAL_ 1618 BIU652_2_0_LOCKSTATUS_DRVR 1 "UNLOCK" 0 "LOCK" ;
VAL_ 1618 BIU652_2_1_LOCKSTATUS_PASS 1 "UNLOCK" 0 "LOCK" ;
VAL_ 1618 BIU652_2_2_LOCKSTATUS_RRRH 1 "UNLOCK" 0 "LOCK" ;
VAL_ 1618 BIU652_2_3_LOCKSTATUS_RRLH 1 "UNLOCK" 0 "LOCK" ;
VAL_ 1618 BIU652_2_4_LOCKSTATUS_RG 1 "UNLOCK OR PERMIT_UNLOCK" 0 "LOCK OR PROHIBIT_UNLOOK" ;
VAL_ 1618 BIU652_2_6_UNLOCK_DOORKEYSW 1 "ON" 0 "OFF" ;
VAL_ 1618 BIU652_2_7_LOCK_DOORKEYSW 1 "ON" 0 "OFF" ;
VAL_ 1617 BIU651_7_0_PWPOS_RL 3 "other" 2 "ALL CLOSE" 1 "ALL OPEN" 0 "INDEFINITE" ;
VAL_ 1617 BIU651_7_2_PWPOS_RR 3 "other" 2 "ALL CLOSE" 1 "ALL OPEN" 0 "INDEFINITE" ;
VAL_ 1617 BIU651_7_4_PWPOS_PASS 3 "other" 2 "ALL CLOSE" 1 "ALL OPEN" 0 "INDEFINITE" ;
VAL_ 1617 BIU651_7_6_PWPOS_DRVR 3 "other" 2 "ALL CLOSE" 1 "ALL OPEN" 0 "INDEFINITE" ;
VAL_ 1617 BIU651_6_0_IND_ACTIVE_HBA 3 "NONE" 2 "BLINK" 1 "Turn_ON" 0 "Turn_OFF" ;
VAL_ 1617 BIU651_6_2_ADB_ACTIVE 1 "ACTIVE" 0 "NON_ACTIVE" ;
VAL_ 1617 BIU651_6_3_JUDGE_ILL 1 "ACTIVE" 0 "NON_ACTIVE" ;
VAL_ 1617 BIU651_6_4_TYPE_LO_BEAM 3 "NONE" 2 "LED" 1 "HID" 0 "HALOGEN" ;
VAL_ 1617 BIU651_6_6_TYPE_HI_BEAM 3 "NONE" 2 "LED" 1 "HID" 0 "HALOGEN" ;
VAL_ 1617 BIU651_5_0_SRF_ACTIVE 1 "ACTIVE" 0 "NON_ACTIVE" ;
VAL_ 1617 BIU651_5_1_SRF_IND 3 "NONE" 2 "BLINK" 1 "Turn_ON" 0 "Turn_OFF" ;
VAL_ 1617 BIU651_5_3_SRF_LAMP_LIGHT 1 "Turn_ON" 0 "Turn_OFF" ;
VAL_ 1617 BIU651_5_4_SRF_LAMP_LEFT 1 "Turn_ON" 0 "Turn_OFF" ;
VAL_ 1617 BIU651_5_5_MSG_STATUS_HBA 3 "NONE" 2 "FAIL" 1 "HALT" 0 "OFF" ;
VAL_ 1617 BIU651_5_7_IND_FAIL_HBA 1 "Turn_ON" 0 "Turn_OFF" ;
VAL_ 1617 BIU651_4_0_BUZ_PATTERN 8 "NON" 7 "Customize_2" 6 "Customize_1" 5 "NON" 4 "NON" 3 "Light_Warning" 2 "Key_Warning" 1 "Reverse_BUZZ" 0 "BUZZ_STOP" ;
VAL_ 1617 BIU651_4_4_CSTM_OPE_ALARM 3 "NON" 2 "OFF" 1 "ON" 0 "BLINK" ;
VAL_ 1617 BIU651_4_6_CSTM_HBA 3 "BLANK" 2 "MIRROR_HBA" 1 "EYESIGHT_HBA" 0 "NON_ACTIVE" ;
VAL_ 1617 BIU651_3_0_HEADLAMP_PASS_SW 1 "ON" 0 "OFF" ;
VAL_ 1617 BIU651_3_1_HEADLAMP_AUTO_SW 1 "ON" 0 "OFF" ;
VAL_ 1617 BIU651_3_2_JUDGE_DOOR_LOCK 1 "REQ" 0 "NON_REQ" ;
VAL_ 1617 BIU651_3_3_JUDGE_DOOR_UNLOCK 1 "CONNECT" 0 "NON_CONNECT" ;
VAL_ 1617 BIU651_3_4_HEADLAMP_Lo_SW 1 "ON" 0 "OFF" ;
VAL_ 1617 BIU651_3_5_HEADLAMP_HI_SW 1 "ON" 0 "OFF" ;
VAL_ 1617 BIU651_3_6_WIPER_AUTO_SW 1 "ON" 0 "OFF" ;
VAL_ 1617 BIU651_3_7_PRG_LIN_MEMORY_ON_OFF 1 "ON" 0 "OFF" ;
VAL_ 1617 BIU651_2_0_CSTM_ILLUMI_SSR 1 "ACTIVE" 0 "NON_ACTIVE" ;
VAL_ 1617 BIU651_2_1_HANDLE 1 "RHD" 0 "LHD" ;
VAL_ 1617 BIU651_2_2_CSTM_SMT 1 "SMART" 0 "NOT SMART" ;
VAL_ 1617 BIU651_2_3_AJARDOOR_STATUS 1 "AJAR_DOOR" 0 "NOT_AJAR_DOOR" ;
VAL_ 1617 BIU651_2_4_ONETOUCH_LAMP_OUT 1 "ON" 0 "OFF" ;
VAL_ 1617 BIU651_2_5_PRG_FAIL_FLAG 1 "ON" 0 "OFF" ;
VAL_ 1617 BIU651_2_6_CSTM_PSMECU 1 "ACTIVE" 0 "NON_ACTIVE" ;
VAL_ 1617 BIU651_2_7_STATE_REGIST_DEL 1 "FINISIED" 0 "NOT_FINISIED" ;
VAL_ 1617 BIU651_1_4_SRPOS 7 "未使用" 6 "未使用" 5 "チルト区間で開" 4 "スライド区間で開" 3 "全閉" 2 "チルト全開" 1 "スライド全開" 0 "不定" ;
VAL_ 1617 BIU651_1_7_WIPER_INT_STATUS 1 "INT_ON" 0 "INT_OFF" ;
VAL_ 942 BIU3AE_5_0_WIPER_FT_VOLUME 5 "NON" 4 "Vol.5" 3 "Vol.4" 2 "Vol.3" 1 "Vol.2" 0 "Vol.1" ;
VAL_ 942 BIU3AE_4_4_FT_WIPER_FAIL 1 "FAIL" 0 "NORMAL" ;
VAL_ 942 BIU3AE_4_5_WIPER_FT 3 "AUTO" 2 "HIGH" 1 "LOW(MIST)" 0 "OFF" ;
VAL_ 942 BIU3AE_3_0_WINKER_LEVER_STATUS 5 "NON" 4 "Left_ON_Hold" 3 "Right_ON_Hold" 2 "Left_ON" 1 "Right_ON" 0 "OFF" ;
VAL_ 942 BIU3AE_3_4_WINKER_FACTOR 15 "NON" 14 "NON" 13 "Turn_Right(ActiveLaneChange)" 12 "Turn_Left(ActiveLaneChange)" 11 "Turn_Right(MinimumRiskManeuver)" 10 "Turn_Left(MinimumRiskManeuver)" 9 "OFF(MinimumRiskManeuver)" 8 "Hazard(Other)" 7 "Hazard(MinimumRiskManeuver)" 6 "Hazard(Emergency Brake)" 5 "Hazard(Hazard SW)" 4 "Turn_Right(deep push)" 3 "Turn_Right(shallow push)" 2 "Turn_Left(deep push)" 1 "Turn_Left(shallow push)" 0 "OFF" ;
VAL_ 942 BIU3AE_2_0_TURN_LAMP_FAIL_LEFT 1 "FAIL" 0 "NORMAL" ;
VAL_ 942 BIU3AE_2_1_TURN_LAMP_FAIL_RIGHT 1 "FAIL" 0 "NORMAL" ;
VAL_ 942 BIU3AE_2_3_HAZARD_SW 1 "ON" 0 "OFF" ;
VAL_ 940 BIU3AC_7_0_HEADLAMP_SMALL 1 "Turn_ON" 0 "Turn_OFF" ;
VAL_ 940 BIU3AC_7_1_HEADLAMP_LO_REQ 1 "Turn_ON" 0 "Turn_OFF" ;
VAL_ 940 BIU3AC_7_2_HEADLAMP_HI_REQ 1 "Turn_ON" 0 "Turn_OFF" ;
VAL_ 940 BIU3AC_7_3_FT_FOG_RELAY_REQ 1 "Turn_ON" 0 "Turn_OFF" ;
VAL_ 940 BIU3AC_7_4_FOGLAMP_RR 1 "Turn_ON" 0 "Turn_OFF" ;
VAL_ 940 BIU3AC_7_5_DRL 1 "Turn_ON" 0 "Turn_OFF" ;
VAL_ 940 BIU3AC_7_6_WIPER_FRONT 1 "ON" 0 "OFF" ;
VAL_ 940 BIU3AC_7_7_RDEF_RELAY_REQ 1 "ON" 0 "OFF" ;
VAL_ 940 BIU3AC_6_0_RDEFOGSW 1 "ON" 0 "OFF" ;
VAL_ 940 BIU3AC_6_1_CSTM_PRG 1 "PRG" 0 "NOT_PRG" ;
VAL_ 940 BIU3AC_6_2_FAIL_SHIFTLOCKSOL 1 "FAIL" 0 "NORMAL" ;
VAL_ 940 BIU3AC_6_3_REQ_CANCEL_ISS 1 "CANCEL" 0 "NON_CANCEL" ;
VAL_ 940 BIU3AC_6_4_REVERSE_MT 1 "REVERSE_ON" 0 "OFF" ;
VAL_ 940 BIU3AC_6_5_HANDBRAKE 1 "ON" 0 "OFF" ;
VAL_ 940 BIU3AC_6_6_BRAKELAMPSW 1 "ON" 0 "OFF" ;
VAL_ 940 BIU3AC_6_7_TOWING_SW 1 "ON" 0 "OFF" ;
VAL_ 940 BIU3AC_5_0_LANE_OFF_SW 3 "NONE" 2 "BREAKING_OF_WIRE" 1 "P-CR-OFF-SW_ON" 0 "OFF" ;
VAL_ 940 BIU3AC_5_2_PCR_OFF_SW 3 "NONE" 2 "BREAKING_OF_WIRE" 1 "P-CR-OFF-SW_ON" 0 "OFF" ;
VAL_ 940 BIU3AC_5_4_DIMMER_CANCEL 1 "ACTIVE" 0 "NON_ACTIVE" ;
VAL_ 940 BIU3AC_5_5_KEYSW 1 "ON" 0 "OFF" ;
VAL_ 940 BIU3AC_5_6_IND_ND_SHIFTLOCK 1 "表示" 0 "非表示" ;
VAL_ 940 BIU3AC_4_0_DOOR_DRVR 1 "OPEN" 0 "CLOSE" ;
VAL_ 940 BIU3AC_4_1_DOOR_PASS 1 "OPEN" 0 "CLOSE" ;
VAL_ 940 BIU3AC_4_2_DOOR_RRRH 1 "OPEN" 0 "CLOSE" ;
VAL_ 940 BIU3AC_4_3_DOOR_RRLH 1 "OPEN" 0 "CLOSE" ;
VAL_ 940 BIU3AC_4_4_DOOR_RG 1 "OPEN" 0 "CLOSE" ;
VAL_ 940 BIU3AC_4_5_DOOR_TR 1 "OPEN" 0 "CLOSE" ;
VAL_ 940 BIU3AC_4_6_HOOD_CLOSE 1 "ON" 0 "OFF" ;
VAL_ 940 BIU3AC_4_7_HOOD_OPEN 1 "ON" 0 "OFF" ;
VAL_ 940 BIU3AC_3_0_GW_STSW_RES 1 "REQ_RES_EGStart" 0 "NON_REQ_RES_EGStart" ;
VAL_ 940 BIU3AC_3_1_GW_POWER_RES 2 "RES_Start_MODE" 1 "Pre_Air_Cond_MODE" 0 "Normal_MODE" ;
VAL_ 940 BIU3AC_3_3_ST1 1 "ST" 0 "NORMAL" ;
VAL_ 940 BIU3AC_3_4_ST2 1 "ST" 0 "NORMAL" ;
VAL_ 940 BIU3AC_3_5_ACC 1 "ON" 0 "OFF" ;
VAL_ 940 BIU3AC_3_6_IGA 1 "ON" 0 "OFF" ;
VAL_ 940 BIU3AC_3_7_BAT_BACKUP 1 "ON" 0 "OFF" ;
VAL_ 940 BIU3AC_2_0_CSTM_AC 1 "ACTIVE" 0 "NON_ACTIVE" ;
VAL_ 940 BIU3AC_2_1_IMB_SMT 3 "Push&SMT" 2 "IMB_NO" 1 "IMB_YES" 0 "NON" ;
VAL_ 940 BIU3AC_2_3_CSTM_WGN_SDN 1 "WGN" 0 "SDN" ;
VAL_ 940 BIU3AC_2_4_VAL_SEAT_BACK_CTSM 1 "SEAT_BACK_ON" 0 "SEAT_BACK_OFF" ;
VAL_ 940 BIU3AC_2_5_VAL_MIR_AFOLD_CTSM 1 "MIR_AFOLD_ON" 0 "MIR_AFOLD_OFF" ;
VAL_ 940 BIU3AC_2_6_VAL_MIR_RTILT_CTSM 1 "MIR_RTILT_ON" 0 "MIR_RTILT_OFF" ;
VAL_ 940 BIU3AC_2_7_WIPER_REAR 1 "ON" 0 "OFF" ;
VAL_ 940 BIU3AC_1_4_PADDLESHIFT_DOWN_SW 1 "ON" 0 "OFF" ;
VAL_ 940 BIU3AC_1_5_PADDLESHIFT_UP_SW 1 "ON" 0 "OFF" ;
VAL_ 940 BIU3AC_1_6_MANUALMODE_SW 1 "ON" 0 "OFF" ;
VAL_ 1616 BIU650_7_3_DOOR_LINK_SW_STS 1 "ON" 0 "OFF" ;
VAL_ 1616 BIU650_6_3_RR_WIPER_STATUS 3 "Undefined" 2 "Hi" 1 "Lo" 0 "OFF" ;
VAL_ 1616 BIU650_6_5_WIPER_SENSITIVITY_CTM 3 "4" 2 "3" 1 "2" 0 "1" ;
VAL_ 1616 BIU650_5_2_FMH_DOOR_LOCK 3 "Undefined" 2 "Unlock" 1 "Lock" 0 "No request" ;
VAL_ 1616 BIU650_5_4_LMH_DOOR_LOCK 3 "Undefined" 2 "Unlock" 1 "Lock" 0 "No request" ;
VAL_ 1616 BIU650_4_0_REQ_OPE_AUTOLIGHT 3 "Undefined" 2 "Lo" 1 "Small" 0 "OFF" ;
VAL_ 1616 BIU650_4_2_STATE_SHINSSR 3 "Normal Mode" 2 "Diagnostic Mode" 1 "Shipping Inspection Mode" 0 "Initialization Mode" ;
VAL_ 1616 BIU650_4_4_STATE_RLS_FAIL 3 "Undefined" 2 "Recovering" 1 "Abnormal" 0 "Normal" ;
VAL_ 1616 BIU650_3_0_REQ_FWASHER_ITLOCK 1 "ON" 0 "OFF" ;
VAL_ 1616 BIU650_3_1_FWIPER_RTN 1 "ON" 0 "OFF" ;
VAL_ 1616 BIU650_3_2_TURN_LAMP_STATE_LEFT 1 "Blink" 0 "OFF" ;
VAL_ 1616 BIU650_3_3_TURN_LAMP_STATE_RIGHT 1 "Blink" 0 "OFF" ;
VAL_ 1616 BIU650_2_0_HEADLAMP_SMALL_SW 1 "ON" 0 "OFF" ;
VAL_ 1616 BIU650_2_1_HEADLAMP_LO_SW 1 "ON" 0 "OFF" ;
VAL_ 1616 BIU650_2_2_HEADLAMP_OFF_SW 1 "ON" 0 "OFF" ;
VAL_ 1616 BIU650_2_3_HEADLAMP_Hi_SW 1 "ON" 0 "OFF" ;
VAL_ 1616 BIU650_2_4_HEAD_LAMP_PASS_SW 1 "ON" 0 "OFF" ;
VAL_ 1616 BIU650_2_5_FFOG_SW 1 "ON" 0 "OFF" ;
VAL_ 1616 BIU650_2_6_RFOG_SW 1 "ON" 0 "OFF" ;
VAL_ 798 BST31E_3_4_HBC_REQUEST 1 "REQUEST" 0 "NON REQUEST" ;
VAL_ 799 BST31F_2_3_HBC_REQUEST 1 "REQUEST" 0 "NON REQUEST" ;
VAL_ 345 BST159_3_4_HBC_REQUEST 1 "REQUEST" 0 "NON REQUEST" ;
VAL_ 809 BST329_1_4_EB_HMI_WARNINGON 1 "Turn_ON" 0 "Turn_OFF" ;
VAL_ 809 BST329_1_5_WARN_BST_MET_LCD 0 "NOT_IINDICATE" 1 "INDICATE" ;
VAL_ 809 BST329_1_6_WARN_BST_RED 1 "Turn_ON" 0 "Turn_OFF" ;
VAL_ 319 BST13F_4_0_FAIL_VDC 1 "Normal" 0 "AnomaｌyDetection" ;
VAL_ 319 BST13F_2_0_BRAKE_PEDAL_APPLIED 0 "NO OPERATE" 1 "OPERATE" ;
VAL_ 319 BST13F_2_1_BRAKE_PEDAL_APPLIED_Q 3 "Reserved" 2 "Faulty" 1 "Normal" 0 "NotInitialized" ;
VAL_ 319 BST13F_2_3_HBC_REQUEST 1 "REQUEST" 0 "NON REQUEST" ;
VAL_ 319 BST13F_2_4_EB_DIAG_ACTIVE 1 "DIAG MODE" 0 "NON DIAG MODE" ;
VAL_ 319 BST13F_2_6_P_RUNOUT_Q 3 "Reserved" 2 "Faulty" 1 "Normal" 0 "NotInitialized" ;
VAL_ 1282 BST502_1_4_ActiveWakeUpBit 1 "active wakeup" 0 "passive wakeup" ;
VAL_ 811 EPB32B_6_0_VEHICLE_RUN_STOP_FLG 3 "reserve" 2 "ERROR" 1 "DRIVING" 0 "STOPPING" ;
VAL_ 811 EPB32B_6_2_REQ_HILL_P_CAUTION 1 "Turn_ON" 0 "Turn_OFF" ;
VAL_ 811 EPB32B_5_0_FLG_AVH_OILPRES_EPB 0 "NOT_OPERATE" 1 "OPERATE" ;
VAL_ 811 EPB32B_5_1_FLG_AVH 1 "AVH_OPERATE" 0 "AVH_NOT_OPERATE" ;
VAL_ 811 EPB32B_5_2_AVH_INTENSIFY_PRES 0 "OTHER" 1 "AVH_INTENSIFY_PRESSURE_DURING_ISS" ;
VAL_ 811 EPB32B_5_3_BREAK_IND 3 "UNDEFINED(TURN_OFF/DISPLAY OFF)" 2 "BLINK(Segment LC) or DISPLAY ON(Color LC)" 1 "TURN_ON(Segment LC) or DISPLAY ON(Color LC)" 0 "TURN_OFF(Segment LC) or DISPLAY OFF(Color LC)" ;
VAL_ 811 EPB32B_5_5_AVH_ON_LAMP 1 "ON" 0 "OFF" ;
VAL_ 811 EPB32B_5_6_AVH_FUNC_ON_LUMP 1 "ON" 0 "OFF" ;
VAL_ 811 EPB32B_5_7_AVH_ACTIVE 1 "WITH_AVH" 0 "WIITHOUT_AVH" ;
VAL_ 811 EPB32B_4_0_BUZZER 3 "CANCEL_Pi-X1" 2 "SHIFT_DISABLE_PiX2" 1 "DRIVER_BRAKE_CUE_Pi-" 0 "NO_BUZZER" ;
VAL_ 811 EPB32B_4_2_HILL_HOLD_ON_LAMP 1 "ON" 0 "OFF" ;
VAL_ 811 EPB32B_4_3_CLAMP_LAMP 3 "No_difinition" 2 "LAMP_BLINK" 1 "LAMP_ON" 0 "LAMP_OFF" ;
VAL_ 811 EPB32B_4_5_WARN_LAMP 3 "No_difinition" 2 "LAMP_BLINK" 1 "LAMP_ON" 0 "LAMP_OFF" ;
VAL_ 811 EPB32B_4_7_WARN_EPB_MET_LCD 1 "INDICATE" 0 "NOT_IINDICATE" ;
VAL_ 811 EPB32B_3_0_STATUS_EPB 7 "No_difinition" 6 "No_difinition" 5 "DYNAMIC PARKING" 4 "RELEASING" 3 "OPERATING" 2 "OPERATE" 1 "RELEASE" 0 "ERROR" ;
VAL_ 811 EPB32B_3_3_DYNAMIC_PARKING 1 "ON" 0 "OFF" ;
VAL_ 811 EPB32B_3_4_HILL_HOLD_RUN_FLG 1 "OPERATE" 0 "NOT_OPERATE" ;
VAL_ 811 EPB32B_3_5_INHIBIT_ISS_DELAY 1 "INHIBIT" 0 "PERMIT" ;
VAL_ 811 EPB32B_3_6_INHIBIT_ISS 1 "INHIBIT" 0 "PERMIT" ;
VAL_ 811 EPB32B_3_7_AVH_PERMIT_CONT_ACC 1 "PERMISSION" 0 "PROHIBITION" ;
VAL_ 811 EPB32B_2_0_ERR_INFO 3 "PULL_FORCE_FAIL" 2 "EMERGENCY_RELEASE" 1 "STROKE_SHORT" 0 "NORMAL" ;
VAL_ 811 EPB32B_2_2_EPB_FAIL_FLG1 1 "PERMIT" 0 "INHIBIT" ;
VAL_ 811 EPB32B_2_3_EPB_FAIL_FLG2 1 "PERMIT" 0 "INHIBIT" ;
VAL_ 811 EPB32B_2_4_EPB_FAIL_FLG3 1 "PERMIT" 0 "INHIBIT" ;
VAL_ 811 EPB32B_1_4_WAKE_UP_FRAME 1 "WakeUP_FRAME" 0 "Normal_FRAME" ;
VAL_ 811 EPB32B_1_5_REQ_COMM_CONT 1 "REQUEST" 0 "NO_REQUEST" ;
VAL_ 1281 EPB501_1_4_ActiveWakeUpBit 1 "active wakeup" 0 "passive wakeup" ;
VAL_ 57 VDC039_3_4_Q_TARGET_EXTERNAL_Q 3 "-" 2 "CONTROL(AEB)" 1 "CONTROL(ACC)" 0 "NON CONTROL" ;
VAL_ 323 VDC143_1_4_IG_ON 0 "OFF" 1 "ON" ;
VAL_ 323 VDC143_1_5_VEHICLE_SPEED_Q 3 "Reserved" 2 "Faulty" 1 "Normal" 0 "NotInitialized" ;
VAL_ 323 VDC143_1_7_DIAG_STATUS 0 "NON DIAG MODE" 1 "DIAG MODE" ;
VAL_ 56 VDC038_5_2_P_MC_Q 3 "Reserved" 2 "Faulty" 1 "Normal" 0 "NotInitialized" ;
VAL_ 56 VDC038_5_4_PRESS_HOLD_ACTIVE 1 "BRK_HOLD_ACTIVE" 0 "BRK_HOLD_OFF" ;
VAL_ 56 VDC038_5_5_DRIVE_OFF_DETEC 1 "REQ" 0 "NON_REQ" ;
VAL_ 56 VDC038_1_4_ABS_ACTIVE 0 "ABS NON OPERAT" 1 "ABS OPERATE" ;
VAL_ 56 VDC038_1_6_Q_TARGET_EXTERNAL_Q 3 "-" 2 "CONTROL(AEB)" 1 "CONTROL(ACC)" 0 "NON CONTROL" ;
VAL_ 362 VDC16A_3_7_JUDGE_EXTRUSION 1 "EXTRUSION" 0 "OTHER" ;
VAL_ 808 VDC328_7_1_IND_WARN_CBC 1 "Turn_ON" 0 "Turn_OFF" ;
VAL_ 808 VDC328_7_2_ACTIVATE_CBC 1 "Turn_ON" 0 "Turn_OFF" ;
VAL_ 808 VDC328_7_3_FLAG_ACT_CBC 1 "ACTIVE" 0 "NON_ACTIVE" ;
VAL_ 808 VDC328_6_0_PROHIBIT_VDC_OFF_CCU 1 "PROHIBIT" 0 "PERMIT" ;
VAL_ 808 VDC328_6_1_PROHIBIT_AVH_CCU 1 "PROHIBIT" 0 "PERMIT" ;
VAL_ 808 VDC328_5_0_VDC_BUZZER 3 "reserve" 2 "VDC_OFF_SHIFT" 1 "VDC_OFF_SHIFT_DISABLE" 0 "NO_BUZZER" ;
VAL_ 808 VDC328_5_2_WARN_BRAKE_BOOST 1 "TURN_ON" 0 "TURN_OFF" ;
VAL_ 808 VDC328_5_6_IND_HSA_ON 1 "HSA ON" 0 "HSA OFF" ;
VAL_ 808 VDC328_5_7_IND_TCS_OFF 1 "Turn_ON" 0 "Turn_OFF" ;
VAL_ 808 VDC328_4_0_IND_VDC_OFF 1 "Turn_ON" 0 "Turn_OFF" ;
VAL_ 808 VDC328_4_1_STATE_ACTIVATE_VDC 1 "ACTIVE" 0 "NON_ACTIVE" ;
VAL_ 808 VDC328_4_2_IND_HSA_OFF 1 "HSA OFF" 0 "HSA ON" ;
VAL_ 808 VDC328_4_3_IND_HDC 3 "Uncertain_TURN_OFF" 2 "BLINK" 1 "TURN_ON" 0 "TURN_OFF" ;
VAL_ 808 VDC328_4_5_WARNING_BRAKE_SYS 3 "reserve" 2 "reserve" 1 "TURN_ON" 0 "TURN_OFF" ;
VAL_ 808 VDC328_4_7_ACTIVE_OHB 1 "ACTIVE" 0 "DEACTIVE" ;
VAL_ 808 VDC328_3_0_IND_WARN_EBD 1 "Turn_ON" 0 "Turn_OFF" ;
VAL_ 808 VDC328_3_1_IND_WARN_ABS 1 "Turn_ON" 0 "Turn_OFF" ;
VAL_ 808 VDC328_3_2_IND_WARN_VDC 1 "Turn_ON" 0 "Turn_OFF" ;
VAL_ 808 VDC328_3_3_IND_WARN_HSA 1 "Turn_ON" 0 "Turn_OFF" ;
VAL_ 808 VDC328_3_4_WARN_BRAKEFLUID_LV 3 "OTHER_FAIL" 2 "RESERVE" 1 "FAIL_Turn_ON" 0 "Turn_OFF" ;
VAL_ 808 VDC328_3_6_IND_TCS_OFF 1 "ON" 0 "OFF" ;
VAL_ 808 VDC328_3_7_EXIST_EPB 1 "WITH_EPB" 0 "WIITHOUT_EPB" ;
VAL_ 808 VDC328_2_0_WARN_EBD_MET_LCD 1 "INDICATE" 0 "NOT_IINDICATE" ;
VAL_ 808 VDC328_2_1_WARN_ABS_MET_LCD 1 "INDICATE" 0 "NOT_IINDICATE" ;
VAL_ 808 VDC328_2_2_WARN_VDC_MET_LCD 1 "INDICATE" 0 "NOT_IINDICATE" ;
VAL_ 808 VDC328_2_3_WARN_HSA_MET_LCD 1 "INDICATE" 0 "NOT_IINDICATE" ;
VAL_ 808 VDC328_2_4_EXIST_VECTARING 1 "WITH VECTORING(16inch_BRAKE)" 0 "WITHOUT VECTORING(15inch_BRAKE)" ;
VAL_ 316 VDC13C_7_0_RCV_FAIL_ADA 1 "ALIVE" 0 "NO_ALIVE" ;
VAL_ 316 VDC13C_7_1_FAIL_PCU 1 "NORMAL" 0 "FAIL" ;
VAL_ 316 VDC13C_7_2_CONT_STATE_ES_BRAKE 1 "ALIVE" 0 "NO_ALIVE" ;
VAL_ 316 VDC13C_7_3_ASST_PRECRUSH_ACC 1 "ACTIVE" 0 "NON_ACTIVE" ;
VAL_ 316 VDC13C_7_4_CONT_STATE_PRECRUSH 1 "ACTIVE" 0 "NON_ACTIVE" ;
VAL_ 316 VDC13C_7_5_PERMIT_BRAKE_ACC 1 "PERMIT" 0 "INHIBIT" ;
VAL_ 316 VDC13C_7_6_DETECT_BRAKING 1 "Driver Brake_ON" 0 "Driver Brake_OFF" ;
VAL_ 316 VDC13C_7_7_EMERGENCY_BRAKE 1 "ON" 0 "OFF" ;
VAL_ 316 VDC13C_6_6_VDC_OFF 1 "SYS_ON" 0 "SYS_OFF" ;
VAL_ 316 VDC13C_6_7_STBY_PREVIEW_VDC 1 "PREVIEW_VDC" 0 "NORMAL_VDC" ;
VAL_ 316 VDC13C_5_7_ACTIVATE_TSM 1 "CONTROL" 0 "NOT_CONTROL" ;
VAL_ 316 VDC13C_4_7_ACTIVATE_RMI 1 "CONTROL" 0 "NOT_CONTROL" ;
VAL_ 316 VDC13C_3_7_ACTIVATE_VECTARING 1 "ACTIVE" 0 "NON_ACTIVE" ;
VAL_ 316 VDC13C_2_7_STATE_ACTIVATE_HSA 1 "ACTIVE" 0 "NON_ACTIVE" ;
VAL_ 316 VDC13C_1_4_ACTIVE_BRAKEHOLD 1 "HOLD" 0 "RELEASE" ;
VAL_ 316 VDC13C_1_5_PROHIBIT_BRAKEHOLD 1 "PROHIBIT" 0 "PERMIT" ;
VAL_ 316 VDC13C_1_6_BRAKELAMP_RELAY 1 "ON" 0 "OFF" ;
VAL_ 316 VDC13C_1_7_STATUS_BRAKELAMP 1 "W/C>0MPa_and_ID160_B2b4=1" 0 "TURN_OFF" ;
VAL_ 315 VDC13B_1_4_BRAKE_TYPE 1 "ACTIVE_BOOSTER" 0 "VDC" ;
VAL_ 315 VDC13B_1_5_REQ_ENG_TRQ_DOWN 1 "REQ" 0 "NON_REQ" ;
VAL_ 315 VDC13B_1_6_REQ_ENG_TRQ_UP 1 "REQ" 0 "NON_REQ" ;
VAL_ 315 VDC13B_1_7_PROHIBIT_FUEL_CUT 1 "PROHIBIT" 0 "PERMIT" ;
VAL_ 313 VDC139_7_4_FAIL_PRESSURE_SSR 1 "NORMAL" 0 "FAIL" ;
VAL_ 313 VDC139_7_5_STATUS_EPB 7 "No_difinition" 6 "AVH_OPERATE" 5 "DYNAMIC PARKING" 4 "RELEASING" 3 "OPERATING" 2 "OPERATE" 1 "RELEASE" 0 "ERROR" ;
VAL_ 313 VDC139_4_0_HDC_STATUS 3 "Uncertain(SYS_OFF)" 2 "SYS_ACTIVE" 1 "SYS_WAIT" 0 "SYS_OFF" ;
VAL_ 313 VDC139_4_2_BRAKELAMPSW 1 "ON" 0 "OFF" ;
VAL_ 313 VDC139_4_3_FAIL_BRAKELAMPSW 1 "NORMAL" 0 "FAIL" ;
VAL_ 313 VDC139_4_4_ACTIVATE_ABS 1 "ACTIVE" 0 "NON_ACTIVE" ;
VAL_ 313 VDC139_4_5_ACTIVATE_TCS 1 "ACTIVE" 0 "NON_ACTIVE" ;
VAL_ 313 VDC139_4_6_CONT_OVER_STR 1 "control" 0 "NON_Control" ;
VAL_ 313 VDC139_4_7_CONT_UNDER_STR 1 "control" 0 "NON_Control" ;
VAL_ 313 VDC139_3_5_FAIL_VDC_SSR 1 "NORMAL" 0 "FAIL" ;
VAL_ 313 VDC139_3_6_FAIL_SPD_SSR_FHI 1 "NORMAL" 0 "FAIL" ;
VAL_ 313 VDC139_3_7_FAIL_ABS_SYS 1 "NORMAL" 0 "FAIL" ;
VAL_ 313 VDC139_1_4_FAIL_HDC_SYS 1 "NORMAL" 0 "FAIL" ;
VAL_ 313 VDC139_1_5_VEHICLE_HIGHT 2 "STANDARD" 1 "OBK" 0 "NON" ;
VAL_ 313 VDC139_1_7_REPROGRAMING 1 "STOP_Diag&COMM" 0 "NORMAL" ;
VAL_ 312 VDC138_1_4_ACTIVE_LDP 1 "ACTIVE" 0 "NON_ACTIVE" ;
VAL_ 312 VDC138_1_5_PROHIBIT_LDP 1 "PROHIBIT" 0 "PERMIT" ;
VAL_ 312 VDC138_1_6_VDC_SMALL_MARGIN 1 "SMALL MARGIN" 0 "NOMAL" ;
VAL_ 312 VDC138_1_7_DETECT_REAR_SLIP 1 "CONTROL" 0 "NOT_CONTROL" ;
VAL_ 1709 CCU6AD_7_0_DMS_SET_REQ 1 "required" 0 "NOT required" ;
VAL_ 1709 CCU6AD_7_1_DP_POPUP_RES 3 "failure" 2 "success" 1 "on_display" 0 "no_process" ;
VAL_ 1709 CCU6AD_6_3_EYE_MONI_BLUE_IND_SET 1 "ON" 0 "OFF" ;
VAL_ 1709 CCU6AD_6_2_EYE_MONI_GRE_IND_SET 1 "ON" 0 "OFF" ;
VAL_ 1709 CCU6AD_6_1_EYE_MONI_YEL_IND_SET 1 "ON" 0 "OFF" ;
VAL_ 1709 CCU6AD_6_0_EYE_MONI_RED_IND_SET 1 "ON" 0 "OFF" ;
VAL_ 1709 CCU6AD_5_0_DP_OPERATION_FLAG 15 "process_stop" 14 "Reserve" 13 "user_switch_require" 12 "Reserve" 11 "user_delete" 10 "Reserve" 9 "user_register_complete" 8 "user_register_ongoing" 7 "Reserve" 6 "SMT_delete" 5 "SMT_register" 4 "DKY_delete" 3 "DKY_register" 2 "IPMS_delete" 1 "IPMS_register" 0 "default" ;
VAL_ 1709 CCU6AD_5_4_DP_OPERATION_NO 15 "all_ID" 14 "Guest" 13 "Reserve" 12 "Reserve" 11 "Reserve" 10 "Reserve" 9 "Reserve" 8 "Reserve" 7 "No.7" 6 "No.6" 5 "No.5" 4 "No.4" 3 "No.3" 2 "No.2" 1 "No.1" 0 "default" ;
VAL_ 1709 CCU6AD_4_7_DP_CCU_FAIL 1 "FAIL" 0 "NORMAL" ;
VAL_ 1709 CCU6AD_4_3_ALERT_BUZZ_REQ 3 "Large" 2 "Middle" 1 "Small" 0 "NOT_required" ;
VAL_ 1709 CCU6AD_4_0_ALERT_VOL_LEVEL_SET 3 "Large" 2 "Middle" 1 "Small" 0 "NOT_required" ;
VAL_ 1709 CCU6AD_3_2_PREC_CAR_START_VOL 3 "ON_Sound" 2 "ON_Buzzer" 1 "OFF" 0 "NOT_required" ;
VAL_ 1709 CCU6AD_3_0_PREC_CAR_SIG_VOL_SET 2 "ON" 1 "OFF" 0 "NOT_required" ;
VAL_ 1709 CCU6AD_2_3_MET_TEMP_UNIT_SET 2 "degF" 1 "degC" 0 "NOT_required" ;
VAL_ 1709 CCU6AD_2_0_UNIT_SET 6 "miles_MPH_kWhpermiles" 5 "miles_MPH_Whpermiles" 4 "miles_MPH_milesperkWh" 3 "km_kmh_kWhper100km" 2 "km_kmh_kmperWhkm" 1 "km_kmh_kmperkWh" 0 "NOT_required" ;
VAL_ 1709 CCU6AD_1_4_DP_DKY_OPERATION_NO 15 "No.15" 14 "No.14" 13 "No.13" 12 "No.12" 11 "No.11" 10 "No.10" 9 "No.9" 8 "No.8" 7 "No.7" 6 "No.6" 5 "No.5" 4 "No.4" 3 "No.3" 2 "No.2" 1 "No.1" 0 "initial" ;
VAL_ 1706 CCU6AA_5_0_WINDOW_LOCK_SET_REQ 1 "required" 0 "NOT_required" ;
VAL_ 1706 CCU6AA_5_2_DOOR_LINK_SET_REQ 1 "required" 0 "NOT_required" ;
VAL_ 1706 CCU6AA_5_4_BULK_TURN_ON_REQ 1 "required" 0 "NOT_required" ;
VAL_ 1706 CCU6AA_5_6_WIPER_SERV_MODE_REQ 3 "Reserve" 2 "ON" 1 "OFF" 0 "NOT required" ;
VAL_ 1706 CCU6AA_4_0_ITMITT_SENSITIVE_REQ 21 "Reserve" 20 "Reserve" 19 "Reserve" 18 "Reserve" 17 "Reserve" 16 "Reserve" 9 "Reserve" 8 "Reserve" 7 "Reserve" 6 "Reserve" 5 "Reserve" 4 "4" 3 "3" 2 "2" 1 "1" 0 "NOT required" ;
VAL_ 1706 CCU6AA_4_4_REAR_WIPER_SET_REQ 3 "Hi" 2 "Lo" 1 "OFF" 0 "NOT_required" ;
VAL_ 1706 CCU6AA_3_0_WELCOME_RIDEON_REQ 7 "Reserve" 6 "Reserve" 5 "Reserve" 4 "30sec" 3 "20sec" 2 "10sec" 1 "OFF" 0 "NOT required" ;
VAL_ 1706 CCU6AA_3_3_WELCOME_GETOFF_REQ 7 "Reserve" 6 "90sec" 5 "60sec" 4 "30sec" 3 "20sec" 2 "10sec" 1 "OFF" 0 "NOT required" ;
VAL_ 1706 CCU6AA_2_0_WIPER_HEADLAMP_REQ 3 "Reserve" 2 "ON" 1 "OFF" 0 "NOT required" ;
VAL_ 1706 CCU6AA_1_4_WIUL_CUSTOM_REQ 2 "ON" 1 "OFF" 0 "NOT_required" ;
VAL_ 1706 CCU6AA_1_6_WAL_CUSTOM_REQ 2 "ON" 1 "OFF" 0 "NOT_required" ;
VAL_ 1704 CCU6A8_7_5_TRQ_CHG_MODE_SET 3 "Blink" 2 "ON" 1 "OFF" 0 "NOT_required" ;
VAL_ 1704 CCU6A8_7_3_ADAPT_DEC_CHG_REQ 3 "Blink" 2 "ON" 1 "OFF" 0 "NOT_required" ;
VAL_ 1704 CCU6A8_7_0_DEC_SELECT_REQ_B 3 "Hi" 2 "Mid" 1 "Lo" 0 "NOT_required" ;
VAL_ 1704 CCU6A8_6_5_DEC_SELECT_REQ_D 3 "Hi" 2 "Mid" 1 "Lo" 0 "NOT_required" ;
VAL_ 1704 CCU6A8_6_2_DEC_SELECT_REQ_ALL 3 "Hi" 2 "Mid" 1 "Lo" 0 "NOT_required" ;
VAL_ 1704 CCU6A8_6_0_DEC_SELECT_REQ_IND 3 "Blink" 2 "ON" 1 "OFF" 0 "NOT_required" ;
VAL_ 1704 CCU6A8_5_2_TOWING_MODE_REQ 2 "ON" 1 "OFF" 0 "NOT_required" ;
VAL_ 1704 CCU6A8_5_0_FACTORY_MODE_STATE 3 "Blink" 2 "ON" 1 "OFF" 0 "NOT_required" ;
VAL_ 1704 CCU6A8_4_2_TRIP_RESET_REQ 1 "required" 0 "NOT_required" ;
VAL_ 1704 CCU6A8_4_0_TRIP_SWITCH_REQ 3 "TRIP B" 2 "TRIP A" 1 "ODO" 0 "NOT required" ;
VAL_ 1704 CCU6A8_3_0_DOW_SFT_POS_SET 1 "required" 0 "NOT required" ;
VAL_ 1704 CCU6A8_2_6_DOW_SET 1 "required" 0 "NOT required" ;
VAL_ 1704 CCU6A8_2_4_RCTA_SET 1 "required" 0 "NOT required" ;
VAL_ 1704 CCU6A8_2_2_BSD_LCA_2ND_SET 1 "required" 0 "NOT required" ;
VAL_ 1704 CCU6A8_2_0_SRVD_SET 1 "required" 0 "NOT required" ;
VAL_ 1704 CCU6A8_1_6_RCR_CSTM_RESET_REQ 1 "required" 0 "NOT required" ;
VAL_ 1704 CCU6A8_1_4_BEV_CSTM_RESET_REQ 1 "required" 0 "NOT required" ;
VAL_ 1144 CCU478_21_0_LAT_CHG_SET_TYPE 3 "Fail_Value" 2 "Time_Range_Type" 1 "Start_Time_Type" 0 "Initial_Value" ;
VAL_ 1144 CCU478_20_2_TIRE_SIZE 7 "21inch" 6 "20inch" 5 "19inch" 4 "18inch" 3 "17inch" 2 "16inch" 1 "15inch" 0 "Initial_Value" ;
VAL_ 1144 CCU478_20_0_TIRE_TYPE 3 "All_Terrain" 2 "Winter" 1 "Normal" 0 "Initial_Value" ;
VAL_ 1144 CCU478_19_2_SW_PFO_MOD_CHG 2 "Performance_Mode_Req" 1 "Normal_Mode_Req" 0 "No_Req" ;
VAL_ 1144 CCU478_19_0_DEP_TIM_CHG_FLG 3 "Fail_Value" 2 "Departure_Time_Setting_UnChanged" 1 "Departure_Time_Setting_Changed" 0 "Initial_Value" ;
VAL_ 1144 CCU478_15_7_DEP_TIM4_PER_FLG 1 "Performance_Mode" 0 "Initial_Value(Normal)" ;
VAL_ 1144 CCU478_15_5_DEP_TIM4_SW_STS 3 "Fail_Value" 2 "ON" 1 "OFF" 0 "Initial_Value(Non-timer)" ;
VAL_ 1144 CCU478_15_0_TIM4_DISP_ID 31 "Fail_Value" 4 "Disp_Seq_No_ID4" 3 "Disp_Seq_No_ID3" 2 "Disp_Seq_No_ID2" 1 "Disp_Seq_No_ID1" 0 "Initial_Value(Non-display)" ;
VAL_ 1144 CCU478_11_7_DEP_TIM3_PER_FLG 1 "Performance_Mode" 0 "Initial_Value(Normal)" ;
VAL_ 1144 CCU478_11_5_DEP_TIM3_SW_STS 3 "Fail_Value" 2 "ON" 1 "OFF" 0 "Initial_Value(Non-timer)" ;
VAL_ 1144 CCU478_11_0_TIM3_DISP_ID 31 "Fail_Value" 4 "Disp_Seq_No_ID4" 3 "Disp_Seq_No_ID3" 2 "Disp_Seq_No_ID2" 1 "Disp_Seq_No_ID1" 0 "Initial_Value(Non-display)" ;
VAL_ 1144 CCU478_7_7_DEP_TIM2_PER_FLG 1 "Performance_Mode" 0 "Initial_Value(Normal)" ;
VAL_ 1144 CCU478_7_5_DEP_TIM2_SW_STS 3 "Fail_Value" 2 "ON" 1 "OFF" 0 "Initial_Value(Non-timer)" ;
VAL_ 1144 CCU478_7_0_TIM2_DISP_ID 31 "Fail_Value" 4 "Disp_Seq_No_ID4" 3 "Disp_Seq_No_ID3" 2 "Disp_Seq_No_ID2" 1 "Disp_Seq_No_ID1" 0 "Initial_Value(Non-display)" ;
VAL_ 1144 CCU478_3_7_DEP_TIM1_PER_FLG 1 "Performance_Mode" 0 "Initial_Value(Normal)" ;
VAL_ 1144 CCU478_3_5_DEP_TIM1_SW_STS 3 "Fail_Value" 2 "ON" 1 "OFF" 0 "Initial_Value(Non-timer)" ;
VAL_ 1144 CCU478_3_0_TIM1_DISP_ID 31 "Fail_Value" 4 "Disp_Seq_No_ID4" 3 "Disp_Seq_No_ID3" 2 "Disp_Seq_No_ID2" 1 "Disp_Seq_No_ID1" 0 "Initial_Value(Non-display)" ;
VAL_ 1105 CCU451_8_0_CHG_BTN_FLG_CCU 4 "Precondition_Button_Display(Resverd)" 2 "Begin_Charging_Button_Display" 1 "Stop_Charging_Button_Display" 0 "Non_Display(Initial)" ;
VAL_ 1105 CCU451_8_3_CHG_CNG_FLG_CCU 1 "Changed" 0 "No_Change(Initial)" ;
VAL_ 1105 CCU451_5_0_SW_RIGHT_NOW_PRE_CON 4 "Undefined" 2 "ON" 1 "OFF" 0 "No_Request" ;
VAL_ 1105 CCU451_4_0_CHG_STP_REQ 1 "Request" 0 "Not Request" ;
VAL_ 1105 CCU451_3_4_DCCHG_PWRUPLMT 15 "Fail" 14 "Initial" 8 "50kW" 7 "75kW" 6 "100kW" 5 "125kW" 4 "150kW" 3 "175kW" 2 "200kW" 1 "225kW" 0 "MAX" ;
VAL_ 1105 CCU451_3_0_ACCHG_CORUPLMT 15 "Fail" 14 "Initial" 6 "8A" 5 "12A" 4 "16A" 3 "24A" 2 "32A" 1 "40A" 0 "MAX " ;
VAL_ 1726 CCU6BE_10_0_CCU_BOOT_STATE 7 "Reserved" 6 "Reserved" 5 "Reserved" 4 "Reserved" 3 "CCU_NORMAL_STARTUP_STATE" 2 "IOC_AND_CLUSTER_NORMAL_STARTUP_STATE" 1 "IOC_AND_IVI_NORMAL_STARTUP_STATE" 0 "IOC_NORMAL_STARTUP_STATE" ;
VAL_ 1726 CCU6BE_9_0_DISP_DRAINAGE 5 "CANCEL_INSTRUCTION" 4 "WAITING_FOR_DRAINAGE_COMPLETION" 3 "START_DRAINAGE_COMPLETION" 2 "WAITING_FOR_DRAINAGE_COMPLETION_START" 1 "SWITCH_TO_DRAINAGE_MODE" 0 "NO_DRAINAGE_CONTROL_REQUEST" ;
VAL_ 1726 CCU6BE_8_0_DISP_POURING_WATER 13 "CANCEL_INSTRUCTION" 12 "INJECTION_COMPLETED" 11 "START_INJECTION_COMPLETION" 10 "WAITING_FOR_INJECTION_COMPLETION" 9 "START_4TH_AIR_BLEEDING" 8 "WAITING_FOR_4TH_AIR_BLEEDING" 7 "START_3RD_AIR_BLEEDING" 6 "WAITING_FOR_3RD_AIR_BLEEDING" 5 "START_2ND_AIR_BLEEDING" 4 "WAITING_FOR_2ND_AIR_BLEEDING" 3 "START_1ST_AIR_BLEEDING" 2 "WAITING_FOR_1ST_AIR_BLEEDING" 1 "SWITCH_TO_WATER_INJECTION_MODE" 0 "NO_WATER_INJECTION_REQUEST" ;
VAL_ 1726 CCU6BE_4_2_QDK_OSWAP 2 "Cancel" 1 "Reqest" 0 "No reqest" ;
VAL_ 1726 CCU6BE_4_4_QDK_FDRQ 2 "Cancel" 1 "Reqest" 0 "No reqest" ;
VAL_ 1726 CCU6BE_4_6_QDK_OWCQ 2 "Cancel" 1 "Reqest" 0 "No reqest" ;
VAL_ 1726 CCU6BE_3_0_QDK_ORRQ 2 "Cancel" 1 "Reqest" 0 "No reqest" ;
VAL_ 1726 CCU6BE_3_2_QDK_OGRQ 2 "Cancel" 1 "Reqest" 0 "No reqest" ;
VAL_ 1726 CCU6BE_3_4_QDK_ODRQ 2 "Cancel" 1 "Reqest" 0 "No reqest" ;
VAL_ 1726 CCU6BE_3_6_QDK_ADLQ 2 "Cancel" 1 "Reqest" 0 "No reqest" ;
VAL_ 1312 IAVAS520_1_4_ActiveWakeUpBit 1 "active wakeup" 0 "passive wakeup" ;
VAL_ 989 IAVAS3DD_2_0_SP_STATUS 4 "―" 3 "発音中（AVAS＋警告音）" 2 "発音中（警告音のみ）" 1 "発音中（ＡＶＡＳのみ）" 0 "停止中" ;
